VERSION ""

NS_ :

BS_:

BU_: HCM IPMA_ADAS PSCM ABS_ESC PCM ECM_HEV VDM CMR_DSMC SOBDMC_HPCM GWM _delete AWD_DLCM GENERIC TSTR

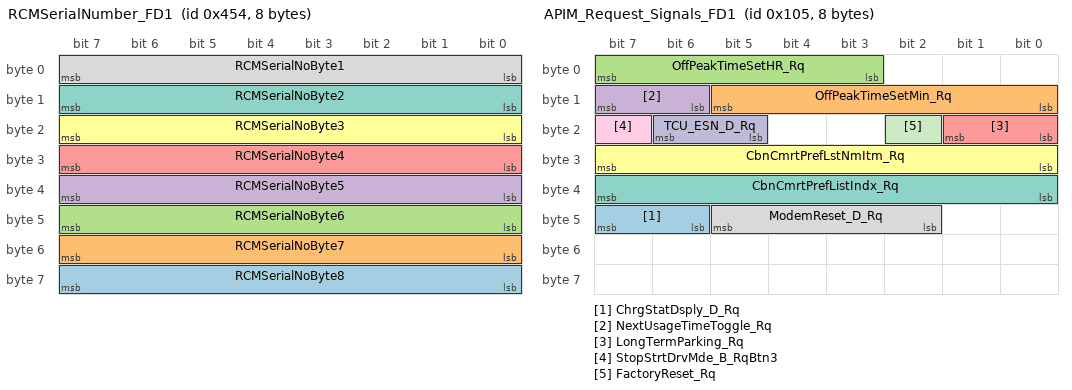
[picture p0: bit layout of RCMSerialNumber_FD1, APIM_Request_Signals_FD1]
BO_ 1108 RCMSerialNumber_FD1: 8 GWM
 SG_ RCMSerialNoByte8 : 63|8@0+ (1,0) [0|253] "Unitless"  ABS_ESC
 SG_ RCMSerialNoByte7 : 55|8@0+ (1,0) [0|253] "Unitless"  ABS_ESC
 SG_ RCMSerialNoByte6 : 47|8@0+ (1,0) [0|253] "Unitless"  ABS_ESC
 SG_ RCMSerialNoByte5 : 39|8@0+ (1,0) [0|253] "Unitless"  ABS_ESC
 SG_ RCMSerialNoByte4 : 31|8@0+ (1,0) [0|253] "Unitless"  ABS_ESC
 SG_ RCMSerialNoByte3 : 23|8@0+ (1,0) [0|253] "Unitless"  ABS_ESC
 SG_ RCMSerialNoByte2 : 15|8@0+ (1,0) [0|253] "Unitless"  ABS_ESC
 SG_ RCMSerialNoByte1 : 7|8@0+ (1,0) [0|253] "Unitless"  ABS_ESC

BO_ 261 APIM_Request_Signals_FD1: 8 GWM
 SG_ ChrgStatDsply_D_Rq : 47|2@0+ (1,0) [0|3] "SED"  GENERIC
 SG_ OffPeakTimeSetMin_Rq : 13|6@0+ (1,0) [0|63] "unitless"  GENERIC
 SG_ OffPeakTimeSetHR_Rq : 7|5@0+ (1,0) [0|31] "unitless"  GENERIC
 SG_ NextUsageTimeToggle_Rq : 15|2@0+ (1,0) [0|3] "SED"  GENERIC
 SG_ LongTermParking_Rq : 17|2@0+ (1,0) [0|3] "SED"  GENERIC
 SG_ CbnCmrtPrefLstNmItm_Rq : 31|8@0+ (1,0) [0|255] "unitless"  GENERIC
 SG_ CbnCmrtPrefListIndx_Rq : 39|8@0+ (1,0) [0|255] "unitless"  GENERIC
 SG_ ModemReset_D_Rq : 45|4@0+ (1,0) [0|15] "SED"  SOBDMC_HPCM
 SG_ StopStrtDrvMde_B_RqBtn3 : 23|1@0+ (1,0) [0|1] "SED"  PCM
 SG_ TCU_ESN_D_Rq : 22|2@0+ (1,0) [0|3] "SED"  GENERIC
 SG_ FactoryReset_Rq : 18|1@0+ (1,0) [0|1] "SED"  SOBDMC_HPCM

BO_ 1146 TrailerInfo_2_FD1: 8 GWM
 SG_ TrlrAidSwtch_D_RqDrv : 35|2@0+ (1,0) [0|3] "SED"  IPMA_ADAS
 SG_ TrlrAidCtl_U_RqDrv : 31|12@0+ (0.00125,0) [0|5.11625] "volt" Vector__XXX

BO_ 533 APIM_Send_Signals_2_FD1: 8 GWM
 SG_ TjaLcEnbl_D_RqMnu : 57|2@0+ (1,0) [0|3] "SED" Vector__XXX
 SG_ ClrExitAsstEnbl_D_RqMnu : 60|2@0+ (1,0) [0|3] "SED"  IPMA_ADAS
 SG_ TrlrAidMde_D_Rq : 5|2@0+ (1,0) [0|3] "SED" Vector__XXX
 SG_ TCU_Init_Actvtn_St : 1|2@0+ (1,0) [0|3] "SED"  GENERIC
 SG_ TCU_Final_Actvtn_St : 3|2@0+ (1,0) [0|3] "SED"  GENERIC
 SG_ OtaTrg_D_Stat : 41|2@0+ (1,0) [0|3] "SED"  GENERIC
 SG_ OnbChrgGoTTouch_D_Rq : 43|2@0+ (1,0) [0|3] "SED"  SOBDMC_HPCM,GENERIC
 SG_ OnbChrgGoTPrcond_D_Rq : 34|2@0+ (1,0) [0|3] "SED"  SOBDMC_HPCM,GENERIC
 SG_ OnbChrgGoTOn_D_Rq : 25|2@0+ (1,0) [0|3] "SED"  SOBDMC_HPCM,GENERIC
 SG_ OnbChrgGoTMnte_D_Rq : 47|4@0+ (1,0) [0|15] "minute"  SOBDMC_HPCM,GENERIC
 SG_ OnbChrgGoTHr_T_Rq : 39|5@0+ (1,0) [0|29] "hour"  SOBDMC_HPCM,GENERIC
 SG_ OnbChrgGoTExtHtr_D_Rq : 27|2@0+ (1,0) [0|3] "SED"  SOBDMC_HPCM,GENERIC
 SG_ OnbChrgGoTElement_D_Rq : 31|4@0+ (1,0) [0|15] "Unitless"  SOBDMC_HPCM,GENERIC
 SG_ OnbChrgGoTDelete_B_Rq : 17|1@0+ (1,0) [0|1] "SED"  SOBDMC_HPCM,GENERIC
 SG_ OnbChrgClearAll_B_Rq : 18|1@0+ (1,0) [0|1] "SED"  SOBDMC_HPCM,GENERIC
 SG_ PaakMyKey_D_Rq : 7|2@0+ (1,0) [0|3] "SED"  GENERIC
 SG_ AutoEpbZoomView_B_Stat : 32|1@0+ (1,0) [0|1] "SED" Vector__XXX
 SG_ AutoEpbButtn_B_Stat : 19|1@0+ (1,0) [0|1] "SED" Vector__XXX
 SG_ DcacPw_D_Rq : 62|2@0+ (1,0) [0|3] "SED" Vector__XXX
 SG_ DcacPwReset_B_Rq : 63|1@0+ (1,0) [0|1] "SED" Vector__XXX
 SG_ LghtAmbDrvMde_D_Rq : 49|2@0+ (1,0) [0|3] "SED"  GENERIC
 SG_ DcacPwLoButtn_B_Stat : 13|1@0+ (1,0) [0|1] "SED" Vector__XXX
 SG_ DcacPwOffButtn_B_Stat : 12|1@0+ (1,0) [0|1] "SED" Vector__XXX
 SG_ DcacPwHiButtn_B_Stat : 14|1@0+ (1,0) [0|1] "SED" Vector__XXX
 SG_ DcacPwResetButtn_B_Stat : 11|1@0+ (1,0) [0|1] "SED" Vector__XXX
 SG_ DcacPwButtn_B_Falt : 15|1@0+ (1,0) [0|1] "SED" Vector__XXX
 SG_ OnbChrgGoTUpdate_B_Rq : 16|1@0+ (1,0) [0|1] "SED"  SOBDMC_HPCM,GENERIC
 SG_ TrlrAlarmButtn_B_Stat : 50|1@0+ (1,0) [0|1] "SED"  GENERIC
 SG_ DcacMdeButtn_B_Stat : 8|1@0+ (1,0) [0|1] "SED" Vector__XXX
 SG_ DcacGfciTestBttn_B_Stat : 9|1@0+ (1,0) [0|1] "SED" Vector__XXX
 SG_ TrlrHitch_D_RqMnu : 23|4@0+ (1,0) [0|15] "SED"  IPMA_ADAS
 SG_ TrlrBrkGain_No_Rq : 55|5@0+ (0.5,0) [0|15.5] "unitless"  GENERIC
 SG_ DcacPwButtn_B_Stat : 10|1@0+ (1,0) [0|1] "SED" Vector__XXX

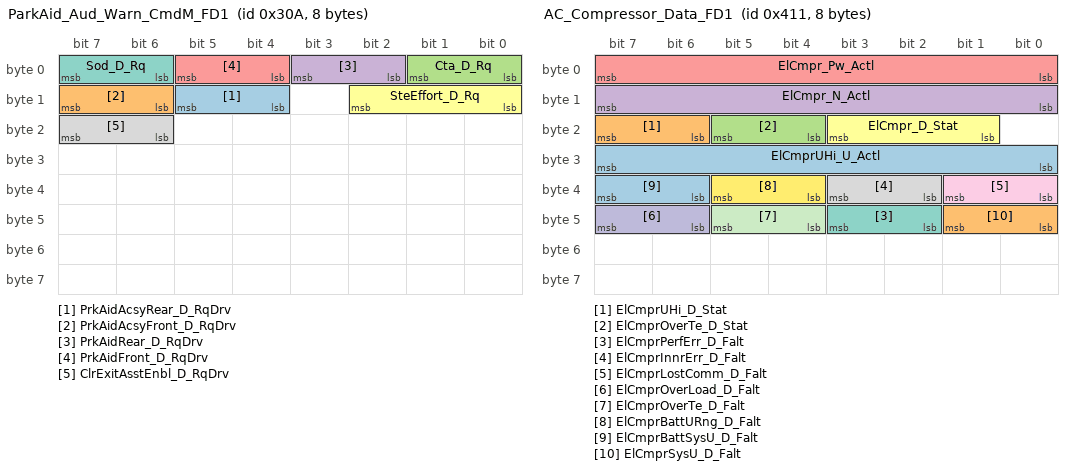
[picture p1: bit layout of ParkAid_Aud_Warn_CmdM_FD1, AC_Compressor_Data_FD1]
BO_ 778 ParkAid_Aud_Warn_CmdM_FD1: 8 GWM
 SG_ PrkAidAcsyRear_D_RqDrv : 13|2@0+ (1,0) [0|3] "SED"  IPMA_ADAS
 SG_ PrkAidAcsyFront_D_RqDrv : 15|2@0+ (1,0) [0|3] "SED"  IPMA_ADAS
 SG_ Cta_D_Rq : 1|2@0+ (1,0) [0|3] "SED"  IPMA_ADAS
 SG_ PrkAidRear_D_RqDrv : 3|2@0+ (1,0) [0|3] "SED"  IPMA_ADAS
 SG_ PrkAidFront_D_RqDrv : 5|2@0+ (1,0) [0|3] "SED"  IPMA_ADAS
 SG_ SteEffort_D_Rq : 10|3@0+ (1,0) [0|7] "SED" Vector__XXX
 SG_ Sod_D_Rq : 7|2@0+ (1,0) [0|3] "SED"  IPMA_ADAS
 SG_ ClrExitAsstEnbl_D_RqDrv : 23|2@0+ (1,0) [0|3] "SED"  IPMA_ADAS

BO_ 1041 AC_Compressor_Data_FD1: 8 GWM
 SG_ ElCmprUHi_U_Actl : 31|8@0+ (2,0) [0|510] "volt"  SOBDMC_HPCM,GENERIC
 SG_ ElCmprUHi_D_Stat : 23|2@0+ (1,0) [0|3] "SED"  SOBDMC_HPCM,GENERIC
 SG_ ElCmprOverTe_D_Stat : 21|2@0+ (1,0) [0|3] "SED"  SOBDMC_HPCM,GENERIC
 SG_ ElCmpr_N_Actl : 15|8@0+ (50,0) [0|12700] "RPM"  SOBDMC_HPCM,GENERIC
 SG_ ElCmpr_Pw_Actl : 7|8@0+ (40,0) [0|10160] "watts"  SOBDMC_HPCM
 SG_ ElCmpr_D_Stat : 19|3@0+ (1,0) [0|7] "SED"  SOBDMC_HPCM,GENERIC
 SG_ ElCmprPerfErr_D_Falt : 43|2@0+ (1,0) [0|3] "SED"  GENERIC,SOBDMC_HPCM
 SG_ ElCmprInnrErr_D_Falt : 35|2@0+ (1,0) [0|3] "SED"  GENERIC,SOBDMC_HPCM
 SG_ ElCmprLostComm_D_Falt : 33|2@0+ (1,0) [0|3] "SED"  GENERIC,SOBDMC_HPCM
 SG_ ElCmprOverLoad_D_Falt : 47|2@0+ (1,0) [0|3] "SED"  GENERIC,SOBDMC_HPCM
 SG_ ElCmprOverTe_D_Falt : 45|2@0+ (1,0) [0|3] "SED"  GENERIC,SOBDMC_HPCM
 SG_ ElCmprBattURng_D_Falt : 37|2@0+ (1,0) [0|3] "SED"  GENERIC,SOBDMC_HPCM
 SG_ ElCmprBattSysU_D_Falt : 39|2@0+ (1,0) [0|3] "SED"  GENERIC,SOBDMC_HPCM
 SG_ ElCmprSysU_D_Falt : 41|2@0+ (1,0) [0|3] "SED"  GENERIC,SOBDMC_HPCM

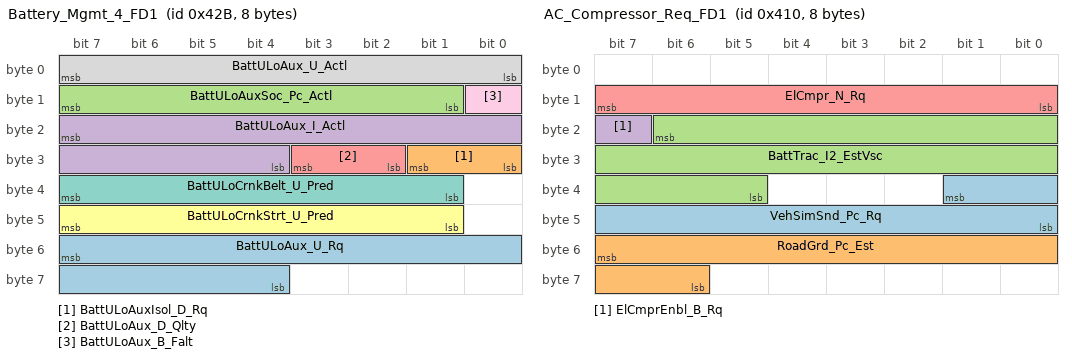
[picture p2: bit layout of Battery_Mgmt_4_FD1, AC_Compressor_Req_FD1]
BO_ 1067 Battery_Mgmt_4_FD1: 8 GWM
 SG_ BattULoAux_U_Rq : 55|12@0+ (0.00390625,0) [0|15.9921875] "volt" Vector__XXX
 SG_ BattULoAuxIsol_D_Rq : 25|2@0+ (1,0) [0|3] "SED" Vector__XXX
 SG_ BattULoAuxSoc_Pc_Actl : 15|7@0+ (1,0) [0|127] "percent" Vector__XXX
 SG_ BattULoAux_I_Actl : 23|12@0+ (0.0625,-128) [-128|127.875] "ampere" Vector__XXX
 SG_ BattULoAux_D_Qlty : 27|2@0+ (1,0) [0|3] "SED" Vector__XXX
 SG_ BattULoCrnkStrt_U_Pred : 47|7@0+ (0.1,0) [0|12.7] "volt" Vector__XXX
 SG_ BattULoCrnkBelt_U_Pred : 39|7@0+ (0.1,0) [0|12.7] "volt" Vector__XXX
 SG_ BattULoAux_U_Actl : 7|8@0+ (0.0625,0) [0|15.875] "volt" Vector__XXX
 SG_ BattULoAux_B_Falt : 8|1@0+ (1,0) [0|1] "SED" Vector__XXX

BO_ 1118 BatteryCharge_Data2_FD1: 8 GWM
 SG_ BptTgl_B_Complt : 29|1@0+ (1,0) [0|1] "SED"  SOBDMC_HPCM
 SG_ AcChrgRdy_B_Stat : 51|1@0+ (1,0) [0|1] "SED"  GENERIC
 SG_ DgtlCommGtwyMde_D_Rq : 48|4@0+ (1,0) [0|15] "SED"  GENERIC
 SG_ ExtChrgNowButtn_B_Rq : 49|1@0+ (1,0) [0|1] "SED"  SOBDMC_HPCM,GENERIC
 SG_ CoolFanChrgr_D_Rq : 45|2@0+ (1,0) [0|3] "SED"  SOBDMC_HPCM,GENERIC
 SG_ ChrgrClntFlw_D_Rq : 31|2@0+ (1,0) [0|3] "SED"  SOBDMC_HPCM,GENERIC
 SG_ PlgStatEvnt_B_Stat : 46|1@0+ (1,0) [0|1] "SED"  SOBDMC_HPCM,ECM_HEV
 SG_ ChrgrCnnctPwr_B_Stat : 47|1@0+ (1,0) [0|1] "SED"  SOBDMC_HPCM,GENERIC
 SG_ ChrgrAvailEvnt_B_Stat : 32|1@0+ (1,0) [0|1] "SED"  SOBDMC_HPCM,ECM_HEV
 SG_ ChrgrSrvcRqd_B_Rq : 0|1@0+ (1,0) [0|1] "SED"  GENERIC
 SG_ ChrgrS2Swtch_B_Stat : 42|1@0+ (1,0) [0|1] "SED"  GENERIC
 SG_ ChrgChngEvnt_B_Stat : 33|1@0+ (1,0) [0|1] "SED"  SOBDMC_HPCM,ECM_HEV
 SG_ ChrgCordLck_D_Stat : 7|3@0+ (1,0) [0|7] "SED"  SOBDMC_HPCM
 SG_ ChrgrInPwMde_D_Actl : 4|4@0+ (1,0) [0|15] "SED"  ECM_HEV,SOBDMC_HPCM
 SG_ ChrgPortDrOpen_B_Stat : 43|1@0+ (1,0) [0|1] "SED"  GENERIC
 SG_ ChrgCordChlng2_No_Actl : 23|8@0+ (1,0) [0|255] "unitless"  GENERIC
 SG_ ChrgCordChlng1_No_Actl : 15|8@0+ (1,0) [0|255] "unitless"  GENERIC
 SG_ ChrgrDcOvrVolt_B_Falt : 50|1@0+ (1,0) [0|1] "SED"  GENERIC
 SG_ ChrgrDcOvrCurnt_B_Falt : 56|1@0+ (1,0) [0|1] "SED"  GENERIC
 SG_ ChrgrPncEnbl_D_Stat : 58|2@0+ (1,0) [0|3] "SED"  GENERIC
 SG_ ChrgrCc2Cnnct_B_Falt : 59|1@0+ (1,0) [0|1] "SED"  GENERIC
 SG_ ChrgPortDcTeMx_B_Falt : 60|1@0+ (1,0) [0|1] "SED"  GENERIC
 SG_ ChrgCrdLck_D_Falt : 41|2@0+ (1,0) [0|3] "SED"  GENERIC

BO_ 1040 AC_Compressor_Req_FD1: 8 SOBDMC_HPCM
 SG_ VehSimSnd_Pc_Rq : 33|10@0+ (0.2,-102.2) [-102.2|102.4] "percent"  GWM
 SG_ RoadGrd_Pc_Est : 55|10@0+ (0.2,-102) [-102|102.4] "percent"  GWM
 SG_ BattTrac_I2_EstVsc : 22|18@0+ (0.05,-6553.52) [-6553.52|6553.53] "ampere"  GWM
 SG_ ElCmprEnbl_B_Rq : 23|1@0+ (1,0) [0|1] "SED"  GWM,ECM_HEV
 SG_ ElCmpr_N_Rq : 15|8@0+ (50,0) [0|12750] "RPM"  GWM,GENERIC

BO_ 1144 MHT_EV_Wakeup_FD1: 8 SOBDMC_HPCM
 SG_ BattTracCool_B_Actl : 60|1@0+ (1,0) [0|1] "SED"  GWM
 SG_ BattChrgInhbt_D2_Rq : 63|3@0+ (1,0) [0|7] "SED"  GWM
 SG_ AwdLckMde_D_Stat : 59|3@0+ (1,0) [0|7] "SED"  GWM
 SG_ ULoBattTrnsfrSustn_B_Rq : 43|1@0+ (1,0) [0|1] "SED"  ECM_HEV,GWM
 SG_ ULoBattTransfer_D_Stat : 46|3@0+ (1,0) [0|7] "SED"  ECM_HEV,GWM
 SG_ BattChrgTrgtSoC_D_Rq : 35|3@0+ (1,0) [0|7] "Percent"  GWM,GENERIC
 SG_ CabnEvapSovFront_B_Rq : 38|1@0+ (1,0) [0|1] "SED"  GWM
 SG_ HeatCoreSovRear_B_Rq : 36|1@0+ (1,0) [0|1] "SED"  GWM,GENERIC
 SG_ BattChlrSov_B_Rq : 39|1@0+ (1,0) [0|1] "SED"  GWM
 SG_ CabnEvapSovRear_B_Rq : 37|1@0+ (1,0) [0|1] "SED"  GWM,GENERIC
 SG_ BrkAppl_D_RqPt : 25|2@0+ (1,0) [0|3] "SED"  GWM,ABS_ESC
 SG_ BattClntVlvOvrrd_D_Rq : 31|2@0+ (1,0) [0|3] "SED"  GWM,GENERIC
 SG_ BattTracChillerOn_B_Rq : 27|1@0+ (1,0) [0|1] "SED"  GWM,GENERIC
 SG_ BattTracChiller_D_Stat : 29|2@0+ (1,0) [0|3] "SED"  GWM,GENERIC
 SG_ HtrnDcdcDis_B_Rq : 26|1@0+ (1,0) [0|1] "SED"  GWM,ECM_HEV
 SG_ HtrnCnnctPwr_B_Stat : 16|1@0+ (1,0) [0|1] "SED"  GWM,GENERIC
 SG_ PtcHtr_D_Stat : 18|2@0+ (1,0) [0|3] "SED"  GWM,ECM_HEV
 SG_ WakeAlarm0_B_Typ : 21|1@0+ (1,0) [0|1] "SED"  GWM,GENERIC
 SG_ WakeAlarm0_T_Rq : 7|15@0+ (1,0) [0|32767] "minute"  GWM,GENERIC
 SG_ HtrnClntFlw_D_Rq : 20|2@0+ (1,0) [0|3] "SED"  GWM,GENERIC
 SG_ BattTracDrvSustn_B_Rq : 8|1@0+ (1,0) [0|1] "SED"  GWM,ECM_HEV
 SG_ CabinDrvSustn_B_Rq : 23|1@0+ (1,0) [0|1] "SED"  GWM,ECM_HEV
 SG_ ChrgNowEvnt_B_Stat : 22|1@0+ (1,0) [0|1] "SED"  GWM,ECM_HEV
 SG_ PreCondBatt_B_Actl : 32|1@0+ (1,0) [0|1] "SED"  GWM,ECM_HEV
 SG_ BattTracClntVlv_B_Rq : 47|1@0+ (1,0) [0|1] "SED"  GWM

BO_ 1112 Battery_Traction_6_FD1: 8 GWM
 SG_ BattDcCnnct_D_Cmd : 14|3@0+ (1,0) [0|7] "SED"  GENERIC
 SG_ BattTrac2_E_Avail : 31|12@0+ (50,0) [0|204650] "watt*hour"  SOBDMC_HPCM
 SG_ BattTracCnnct_D_Cmd : 18|3@0+ (1,0) [0|7] "SED"  SOBDMC_HPCM,ECM_HEV
 SG_ BattTracHvilOpen_B_Stat : 8|1@0+ (1,0) [0|1] "SED"  SOBDMC_HPCM
 SG_ BattTracCoolLvl_D_Rq : 11|3@0+ (1,0) [0|7] "SED"  GENERIC
 SG_ CoolFanBatt_D_Rq : 23|5@0+ (1,0) [0|31] "unitless" Vector__XXX
 SG_ BattTracTeSustn_B_Rq : 1|1@0+ (1,0) [0|1] "SED"  ECM_HEV
 SG_ BattTracTeEvnt_B_Stat : 2|1@0+ (1,0) [0|1] "SED"  SOBDMC_HPCM,ECM_HEV
 SG_ BattTracDcdcDis_B_Rq : 7|1@0+ (1,0) [0|1] "SED"  ECM_HEV
 SG_ BattChrgTrgtEvnt_B_Stat : 3|1@0+ (1,0) [0|1] "SED"  SOBDMC_HPCM,ECM_HEV
 SG_ BattTracChrgSustn_B_Rq : 4|1@0+ (1,0) [0|1] "SED"  SOBDMC_HPCM,ECM_HEV
 SG_ HtrnClntPump_D_Stat : 6|2@0+ (1,0) [0|3] "SED"  SOBDMC_HPCM,GENERIC
 SG_ BattTracIsoDis_B_Stat : 0|1@0+ (1,0) [0|1] "SED"  GENERIC
 SG_ BattTrac2_E_Max : 47|12@0+ (50,0) [0|204650] "watt*hour"  SOBDMC_HPCM
 SG_ BattTracHeat_D_Rq : 35|2@0+ (1,0) [0|3] "SED"  SOBDMC_HPCM
 SG_ BattTracDcFstSustn_B_Rq : 51|1@0+ (1,0) [0|1] "SED" Vector__XXX
 SG_ BattTracDiagClr_B_Rq : 15|1@0+ (1,0) [0|1] "SED"  ECM_HEV
 SG_ BattTracHazrd_D_Stat : 50|3@0+ (1,0) [0|7] "SED"  SOBDMC_HPCM
 SG_ BattTracDelta_Te_Actl : 63|8@0+ (0.5,-60) [-60|66.5] "degC"  SOBDMC_HPCM,GENERIC
 SG_ BattTracClntPmp_D_Stat : 33|2@0+ (1,0) [0|3] "SED"  SOBDMC_HPCM,GENERIC

BO_ 139 CruiseCtrl_Strg_Data_FD1: 8 GWM
 SG_ AccButtnGpTogglePress2 : 25|1@0+ (1,0) [0|1] "SED"  GENERIC
 SG_ TjaButtnOnOffPress2 : 26|1@0+ (1,0) [0|1] "SED"  GENERIC
 SG_ ActvFrontSteMsgTxt_D_Rq : 31|3@0+ (1,0) [0|7] "SED"  GENERIC
 SG_ ActvFrontSteLck_D_Stat : 17|2@0+ (1,0) [0|3] "SED"  PCM
 SG_ SelDrvMdeAdptSte_D_Stat : 28|2@0+ (1,0) [0|3] "SED" Vector__XXX
 SG_ AslButtnOnOffPress2 : 4|1@0+ (1,0) [0|1] "SED"  GENERIC
 SG_ AslButtnOnOffCnclPres2 : 5|1@0+ (1,0) [0|1] "SED"  GENERIC
 SG_ CcButtnOnPress2 : 18|1@0+ (1,0) [0|1] "SED"  GENERIC
 SG_ CcButtnOnOffPress2 : 19|1@0+ (1,0) [0|1] "SED"  GENERIC
 SG_ CcButtnOnOffCnclPress2 : 20|1@0+ (1,0) [0|1] "SED"  GENERIC
 SG_ CcButtnOffPress2 : 21|1@0+ (1,0) [0|1] "SED"  GENERIC
 SG_ CcAsllButtnResPress2 : 22|1@0+ (1,0) [0|1] "SED"  GENERIC
 SG_ CcAslButtnSetPress2 : 23|1@0+ (1,0) [0|1] "SED"  GENERIC
 SG_ CcAslButtnSetIncPress2 : 8|1@0+ (1,0) [0|1] "SED"  GENERIC
 SG_ CcAslButtnSetDecPress2 : 9|1@0+ (1,0) [0|1] "SED"  GENERIC
 SG_ CcAslButtnResIncPress2 : 10|1@0+ (1,0) [0|1] "SED"  GENERIC
 SG_ CcAslButtnResDecPress2 : 11|1@0+ (1,0) [0|1] "SED"  GENERIC
 SG_ CcAslButtnOnPress2 : 12|1@0+ (1,0) [0|1] "SED"  GENERIC
 SG_ CcAslButtnOnOffCncl2 : 13|1@0+ (1,0) [0|1] "SED"  GENERIC
 SG_ CcAslButtnOffCnclPres2 : 14|1@0+ (1,0) [0|1] "SED"  GENERIC
 SG_ CcAslButtnIndxIncPres2 : 15|1@0+ (1,0) [0|1] "SED"  GENERIC
 SG_ CcAslButtnIndxDecPres2 : 0|1@0+ (1,0) [0|1] "SED"  GENERIC
 SG_ CcAslButtnDeny_B_Actl2 : 1|1@0+ (1,0) [0|1] "SED"  GENERIC
 SG_ CcAslButtnCnclResPres2 : 2|1@0+ (1,0) [0|1] "SED"  GENERIC
 SG_ CcAslButtnCnclPress2 : 3|1@0+ (1,0) [0|1] "SED"  GENERIC
 SG_ AccButtnGapIncPress2 : 6|1@0+ (1,0) [0|1] "SED"  GENERIC
 SG_ AccButtnGapDecPress2 : 7|1@0+ (1,0) [0|1] "SED"  GENERIC
 SG_ AfsPw_B_Rq : 24|1@0+ (1,0) [0|1] "SED"  PCM

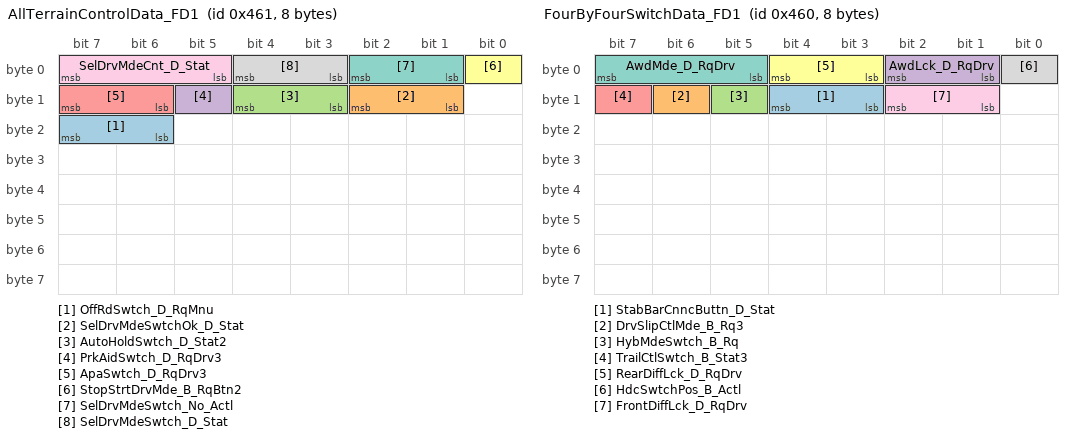
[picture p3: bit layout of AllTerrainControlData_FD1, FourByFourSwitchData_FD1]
BO_ 1121 AllTerrainControlData_FD1: 8 GWM
 SG_ OffRdSwtch_D_RqMnu : 23|2@0+ (1,0) [0|3] "SED"  GENERIC
 SG_ SelDrvMdeSwtchOk_D_Stat : 10|2@0+ (1,0) [0|3] "SED" Vector__XXX
 SG_ AutoHoldSwtch_D_Stat2 : 12|2@0+ (1,0) [0|3] "SED"  ABS_ESC
 SG_ PrkAidSwtch_D_RqDrv3 : 13|1@0+ (1,0) [0|1] "SED"  IPMA_ADAS
 SG_ ApaSwtch_D_RqDrv3 : 15|2@0+ (1,0) [0|3] "SED"  GENERIC
 SG_ StopStrtDrvMde_B_RqBtn2 : 0|1@0+ (1,0) [0|1] "SED" Vector__XXX
 SG_ SelDrvMdeSwtch_No_Actl : 2|2@0+ (1,0) [0|3] "unitless"  ABS_ESC
 SG_ SelDrvMdeSwtch_D_Stat : 4|2@0+ (1,0) [0|3] "SED"  ABS_ESC
 SG_ SelDrvMdeCnt_D_Stat : 7|3@0+ (1,0) [0|7] "Counts"  ABS_ESC

BO_ 1120 FourByFourSwitchData_FD1: 8 GWM
 SG_ StabBarCnncButtn_D_Stat : 12|2@0+ (1,0) [0|3] "SED" Vector__XXX
 SG_ DrvSlipCtlMde_B_Rq3 : 14|1@0+ (1,0) [0|1] "SED"  ABS_ESC
 SG_ HybMdeSwtch_B_Rq : 13|1@0+ (1,0) [0|1] "SED" Vector__XXX
 SG_ AwdLck_D_RqDrv : 2|2@0+ (1,0) [0|3] "SED" Vector__XXX
 SG_ TrailCtlSwtch_B_Stat3 : 15|1@0+ (1,0) [0|1] "SED" Vector__XXX
 SG_ RearDiffLck_D_RqDrv : 4|2@0+ (1,0) [0|3] "SED" Vector__XXX
 SG_ AwdMde_D_RqDrv : 7|3@0+ (1,0) [0|7] "SED" Vector__XXX
 SG_ HdcSwtchPos_B_Actl : 0|1@0+ (1,0) [0|1] "SED" Vector__XXX
 SG_ FrontDiffLck_D_RqDrv : 10|2@0+ (1,0) [0|3] "SED" Vector__XXX

BO_ 1050 Climate_Control_Data_FD1: 8 GWM
 SG_ CamraRearBttn_D_Stat : 35|1@0+ (1,0) [0|1] "SED"  GENERIC
 SG_ TrailCtlSwtch_B_Stat : 16|1@0+ (1,0) [0|1] "SED" Vector__XXX
 SG_ AutoHoldSwtch_D_Stat : 20|2@0+ (1,0) [0|3] "SED"  ABS_ESC
 SG_ GlvBoxRleas_No_Actl : 23|3@0+ (1,0) [0|7] "unitless"  GENERIC
 SG_ EcoInhbt_B_RqHvac : 17|1@0+ (1,0) [0|1] "SED" Vector__XXX
 SG_ LpdbPtc3_B_Rq : 36|1@0+ (1,0) [0|1] "SED"  GENERIC
 SG_ LpdbPtc2_B_Rq : 37|1@0+ (1,0) [0|1] "SED"  GENERIC
 SG_ LpdbPtc1_B_Rq : 38|1@0+ (1,0) [0|1] "SED"  GENERIC
 SG_ LpdbHeatWiprPrk_B_Rq : 39|1@0+ (1,0) [0|1] "SED"  GENERIC
 SG_ LpdbDfrstRearOn_B_Rq : 24|1@0+ (1,0) [0|1] "SED"  GENERIC
 SG_ LpdbDfrstFrOn_B_Rq : 25|1@0+ (1,0) [0|1] "SED"  GENERIC
 SG_ LpdbDfrstFlOn_B_Rq : 26|1@0+ (1,0) [0|1] "SED"  GENERIC
 SG_ LpdbAuxBlwr_B_Rq : 27|1@0+ (1,0) [0|1] "SED"  GENERIC
 SG_ PrkAidSwtch_No_Cnt : 31|4@0+ (1,0) [0|15] "Unitless"  GENERIC
 SG_ PrkAidSwtch_D_RqDrv : 18|1@0+ (1,0) [0|1] "SED"  GENERIC
 SG_ SteWhlHeat_D_Rq : 13|4@0+ (1,0) [0|15] "SED"  GENERIC
 SG_ MirrorHeatOn_B_Rq : 14|1@0+ (1,0) [0|1] "SED"  GENERIC
 SG_ Remote_Start_QuietMode : 15|1@0+ (1,0) [0|1] "SED"  GENERIC
 SG_ DrvSlipCtlMde_B_Rq : 9|1@0+ (1,0) [0|1] "SED"  ABS_ESC
 SG_ Outside_Air_Temp_Stat : 7|8@0+ (0.5,-40) [-40|86.5] "Degrees C"  ECM_HEV,IPMA_ADAS,PCM,PSCM,VDM
 SG_ CamraFrntBttn_D_Stat : 8|1@0+ (1,0) [0|1] "SED"  IPMA_ADAS

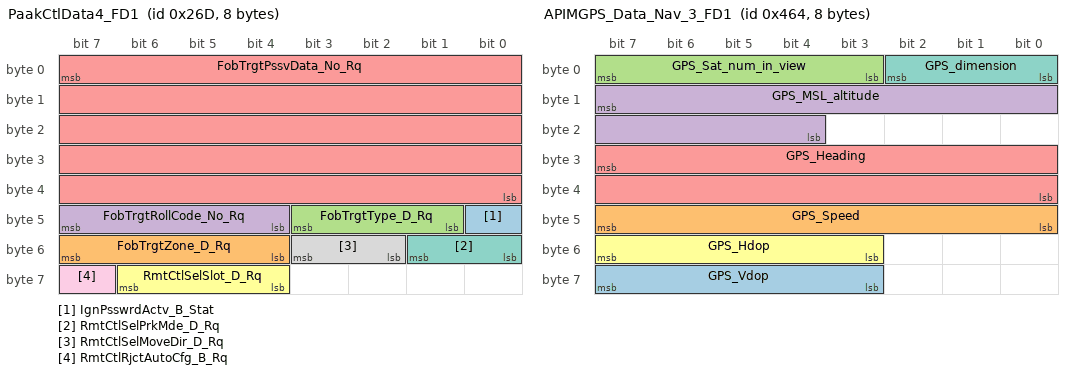
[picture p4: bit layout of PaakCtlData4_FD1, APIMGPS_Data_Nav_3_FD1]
BO_ 621 PaakCtlData4_FD1: 8 GWM
 SG_ IgnPsswrdActv_B_Stat : 40|1@0+ (1,0) [0|1] "SED"  GENERIC
 SG_ FobTrgtZone_D_Rq : 55|4@0+ (1,0) [0|15] "SED"  GENERIC
 SG_ FobTrgtType_D_Rq : 43|3@0+ (1,0) [0|7] "SED"  GENERIC
 SG_ FobTrgtRollCode_No_Rq : 47|4@0+ (1,0) [0|15] "unitless"  GENERIC
 SG_ FobTrgtPssvData_No_Rq : 7|40@0+ (1,0) [0|1099511627775] "Encrypted"  GENERIC
 SG_ RmtCtlSelSlot_D_Rq : 62|3@0+ (1,0) [0|7] "SED"  IPMA_ADAS
 SG_ RmtCtlSelPrkMde_D_Rq : 49|2@0+ (1,0) [0|3] "SED"  IPMA_ADAS
 SG_ RmtCtlSelMoveDir_D_Rq : 51|2@0+ (1,0) [0|3] "SED"  IPMA_ADAS
 SG_ RmtCtlRjctAutoCfg_B_Rq : 63|1@0+ (1,0) [0|1] "SED"  IPMA_ADAS

BO_ 1124 APIMGPS_Data_Nav_3_FD1: 8 GWM
 SG_ GPS_Vdop : 63|5@0+ (0.2,0) [0|5.8] "unitless"  GENERIC
 SG_ GPS_Speed : 47|8@0+ (1,0) [0|253] "MPH"  GENERIC
 SG_ GPS_Sat_num_in_view : 7|5@0+ (1,0) [0|29] "unitless"  GENERIC
 SG_ GPS_MSL_altitude : 15|12@0+ (10,-20460) [-20460|20470] "feet"  GENERIC
 SG_ GPS_Heading : 31|16@0+ (0.01,0) [0|655.33] "Degrees" Vector__XXX
 SG_ GPS_Hdop : 55|5@0+ (0.2,0) [0|5.8] "unitless"  GENERIC
 SG_ GPS_dimension : 2|3@0+ (1,0) [0|7] "SED"  GENERIC

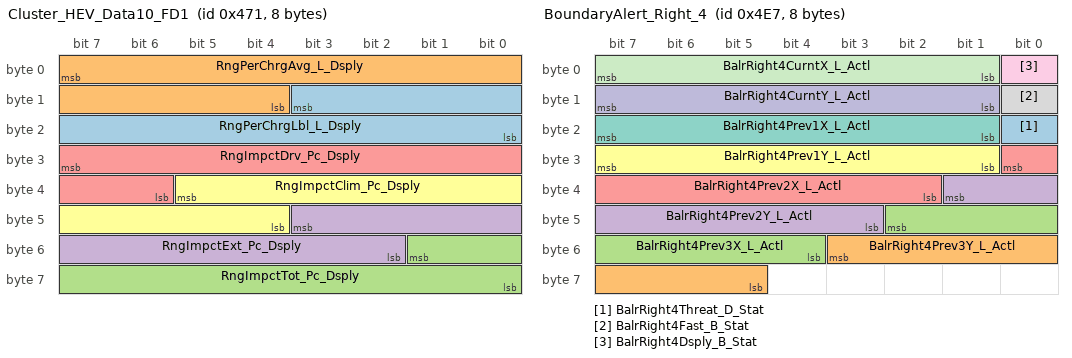
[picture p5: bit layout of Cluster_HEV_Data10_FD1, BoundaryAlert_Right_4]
BO_ 1137 Cluster_HEV_Data10_FD1: 8 PCM
 SG_ RngPerChrgLbl_L_Dsply : 11|12@0+ (0.1,0) [0|409.3] "km"  GWM
 SG_ RngPerChrgAvg_L_Dsply : 7|12@0+ (0.1,0) [0|409.3] "km"  GWM
 SG_ RngImpctTot_Pc_Dsply : 49|10@0+ (0.2,-102) [-102|102.4] "percent"  GWM
 SG_ RngImpctExt_Pc_Dsply : 43|10@0+ (0.2,-102) [-102|102.4] "percent"  GWM
 SG_ RngImpctDrv_Pc_Dsply : 31|10@0+ (0.2,-102) [-102|102.4] "percent"  GWM
 SG_ RngImpctClim_Pc_Dsply : 37|10@0+ (0.2,-102) [-102|102.4] "percent"  GWM

BO_ 1255 BoundaryAlert_Right_4: 8 IPMA_ADAS
 SG_ BalrRight4Threat_D_Stat : 16|1@0+ (1,0) [0|1] "SED"  GWM
 SG_ BalrRight4Prev3Y_L_Actl : 51|7@0+ (0.5,-32) [-32|31.5] "meter"  GWM
 SG_ BalrRight4Prev3X_L_Actl : 42|7@0+ (0.5,-32) [-32|31.5] "meter"  GWM
 SG_ BalrRight4Prev2Y_L_Actl : 33|7@0+ (0.5,-32) [-32|31.5] "meter"  GWM
 SG_ BalrRight4Prev2X_L_Actl : 24|7@0+ (0.5,-32) [-32|31.5] "meter"  GWM
 SG_ BalrRight4Prev1Y_L_Actl : 31|7@0+ (0.5,-32) [-32|31.5] "meter"  GWM
 SG_ BalrRight4Prev1X_L_Actl : 23|7@0+ (0.5,-32) [-32|31.5] "meter"  GWM
 SG_ BalrRight4Fast_B_Stat : 8|1@0+ (1,0) [0|1] "SED"  GWM
 SG_ BalrRight4Dsply_B_Stat : 0|1@0+ (1,0) [0|1] "SED"  GWM
 SG_ BalrRight4CurntY_L_Actl : 15|7@0+ (0.5,-32) [-32|31.5] "meter"  GWM
 SG_ BalrRight4CurntX_L_Actl : 7|7@0+ (0.5,-32) [-32|31.5] "meter"  GWM

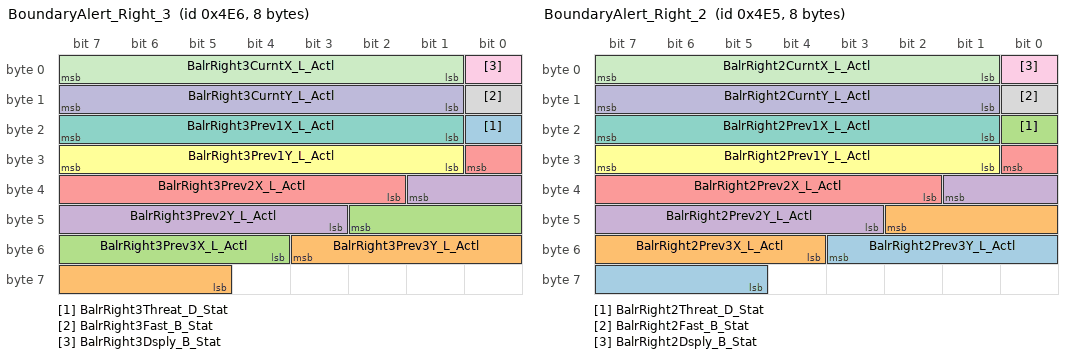
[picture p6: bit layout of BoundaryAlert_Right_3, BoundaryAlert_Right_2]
BO_ 1254 BoundaryAlert_Right_3: 8 IPMA_ADAS
 SG_ BalrRight3Threat_D_Stat : 16|1@0+ (1,0) [0|1] "SED"  GWM
 SG_ BalrRight3Prev3Y_L_Actl : 51|7@0+ (0.5,-32) [-32|31.5] "meter"  GWM
 SG_ BalrRight3Prev3X_L_Actl : 42|7@0+ (0.5,-32) [-32|31.5] "meter"  GWM
 SG_ BalrRight3Prev2Y_L_Actl : 33|7@0+ (0.5,-32) [-32|31.5] "meter"  GWM
 SG_ BalrRight3Prev2X_L_Actl : 24|7@0+ (0.5,-32) [-32|31.5] "meter"  GWM
 SG_ BalrRight3Prev1Y_L_Actl : 31|7@0+ (0.5,-32) [-32|31.5] "meter"  GWM
 SG_ BalrRight3Prev1X_L_Actl : 23|7@0+ (0.5,-32) [-32|31.5] "meter"  GWM
 SG_ BalrRight3Fast_B_Stat : 8|1@0+ (1,0) [0|1] "SED"  GWM
 SG_ BalrRight3Dsply_B_Stat : 0|1@0+ (1,0) [0|1] "SED"  GWM
 SG_ BalrRight3CurntY_L_Actl : 15|7@0+ (0.5,-32) [-32|31.5] "meter"  GWM
 SG_ BalrRight3CurntX_L_Actl : 7|7@0+ (0.5,-32) [-32|31.5] "meter"  GWM

BO_ 1253 BoundaryAlert_Right_2: 8 IPMA_ADAS
 SG_ BalrRight2Prev3Y_L_Actl : 51|7@0+ (0.5,-32) [-32|31.5] "meter"  GWM
 SG_ BalrRight2Prev3X_L_Actl : 42|7@0+ (0.5,-32) [-32|31.5] "meter"  GWM
 SG_ BalrRight2Threat_D_Stat : 16|1@0+ (1,0) [0|1] "SED"  GWM
 SG_ BalrRight2Prev2Y_L_Actl : 33|7@0+ (0.5,-32) [-32|31.5] "meter"  GWM
 SG_ BalrRight2Prev2X_L_Actl : 24|7@0+ (0.5,-32) [-32|31.5] "meter"  GWM
 SG_ BalrRight2Prev1Y_L_Actl : 31|7@0+ (0.5,-32) [-32|31.5] "meter"  GWM
 SG_ BalrRight2Prev1X_L_Actl : 23|7@0+ (0.5,-32) [-32|31.5] "meter"  GWM
 SG_ BalrRight2Fast_B_Stat : 8|1@0+ (1,0) [0|1] "SED"  GWM
 SG_ BalrRight2Dsply_B_Stat : 0|1@0+ (1,0) [0|1] "SED"  GWM
 SG_ BalrRight2CurntY_L_Actl : 15|7@0+ (0.5,-32) [-32|31.5] "meter"  GWM
 SG_ BalrRight2CurntX_L_Actl : 7|7@0+ (0.5,-32) [-32|31.5] "meter"  GWM

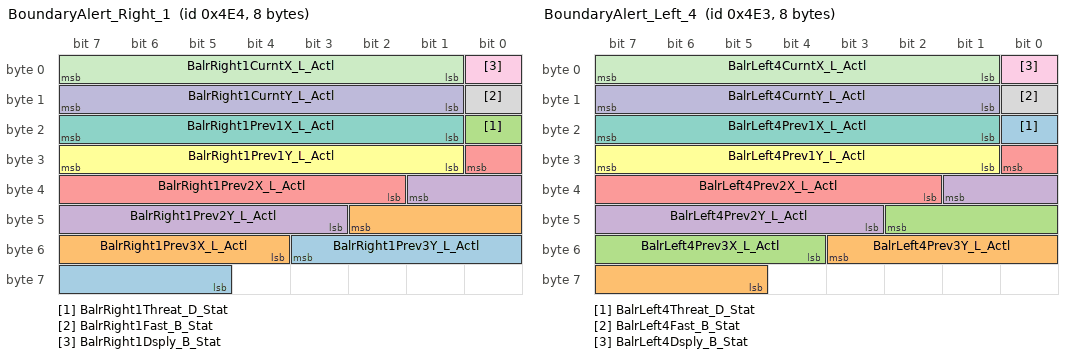
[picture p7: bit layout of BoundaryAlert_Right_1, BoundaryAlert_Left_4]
BO_ 1252 BoundaryAlert_Right_1: 8 IPMA_ADAS
 SG_ BalrRight1Prev3Y_L_Actl : 51|7@0+ (0.5,-32) [-32|31.5] "meter"  GWM
 SG_ BalrRight1Prev3X_L_Actl : 42|7@0+ (0.5,-32) [-32|31.5] "meter"  GWM
 SG_ BalrRight1Threat_D_Stat : 16|1@0+ (1,0) [0|1] "SED"  GWM
 SG_ BalrRight1Prev2Y_L_Actl : 33|7@0+ (0.5,-32) [-32|31.5] "meter"  GWM
 SG_ BalrRight1Prev2X_L_Actl : 24|7@0+ (0.5,-32) [-32|31.5] "meter"  GWM
 SG_ BalrRight1Prev1Y_L_Actl : 31|7@0+ (0.5,-32) [-32|31.5] "meter"  GWM
 SG_ BalrRight1Prev1X_L_Actl : 23|7@0+ (0.5,-32) [-32|31.5] "meter"  GWM
 SG_ BalrRight1Fast_B_Stat : 8|1@0+ (1,0) [0|1] "SED"  GWM
 SG_ BalrRight1Dsply_B_Stat : 0|1@0+ (1,0) [0|1] "SED"  GWM
 SG_ BalrRight1CurntY_L_Actl : 15|7@0+ (0.5,-32) [-32|31.5] "meter"  GWM
 SG_ BalrRight1CurntX_L_Actl : 7|7@0+ (0.5,-32) [-32|31.5] "meter"  GWM

BO_ 1251 BoundaryAlert_Left_4: 8 IPMA_ADAS
 SG_ BalrLeft4Threat_D_Stat : 16|1@0+ (1,0) [0|1] "SED"  GWM
 SG_ BalrLeft4Prev3Y_L_Actl : 51|7@0+ (0.5,-32) [-32|31.5] "meter"  GWM
 SG_ BalrLeft4Prev3X_L_Actl : 42|7@0+ (0.5,-32) [-32|31.5] "meter"  GWM
 SG_ BalrLeft4Prev2Y_L_Actl : 33|7@0+ (0.5,-32) [-32|31.5] "meter"  GWM
 SG_ BalrLeft4Prev2X_L_Actl : 24|7@0+ (0.5,-32) [-32|31.5] "meter"  GWM
 SG_ BalrLeft4Prev1Y_L_Actl : 31|7@0+ (0.5,-32) [-32|31.5] "meter"  GWM
 SG_ BalrLeft4Prev1X_L_Actl : 23|7@0+ (0.5,-32) [-32|31.5] "meter"  GWM
 SG_ BalrLeft4Fast_B_Stat : 8|1@0+ (1,0) [0|1] "SED"  GWM
 SG_ BalrLeft4Dsply_B_Stat : 0|1@0+ (1,0) [0|1] "SED"  GWM
 SG_ BalrLeft4CurntY_L_Actl : 15|7@0+ (0.5,-32) [-32|31.5] "meter"  GWM
 SG_ BalrLeft4CurntX_L_Actl : 7|7@0+ (0.5,-32) [-32|31.5] "meter"  GWM

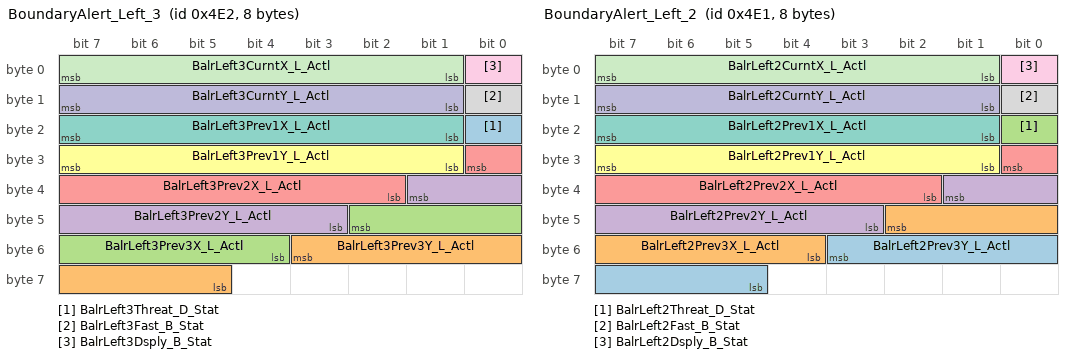
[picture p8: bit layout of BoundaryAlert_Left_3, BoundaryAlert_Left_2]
BO_ 1250 BoundaryAlert_Left_3: 8 IPMA_ADAS
 SG_ BalrLeft3Threat_D_Stat : 16|1@0+ (1,0) [0|1] "SED"  GWM
 SG_ BalrLeft3Prev3Y_L_Actl : 51|7@0+ (0.5,-32) [-32|31.5] "meter"  GWM
 SG_ BalrLeft3Prev3X_L_Actl : 42|7@0+ (0.5,-32) [-32|31.5] "meter"  GWM
 SG_ BalrLeft3Prev2Y_L_Actl : 33|7@0+ (0.5,-32) [-32|31.5] "meter"  GWM
 SG_ BalrLeft3Prev2X_L_Actl : 24|7@0+ (0.5,-32) [-32|31.5] "meter"  GWM
 SG_ BalrLeft3Prev1Y_L_Actl : 31|7@0+ (0.5,-32) [-32|31.5] "meter"  GWM
 SG_ BalrLeft3Prev1X_L_Actl : 23|7@0+ (0.5,-32) [-32|31.5] "meter"  GWM
 SG_ BalrLeft3Fast_B_Stat : 8|1@0+ (1,0) [0|1] "SED"  GWM
 SG_ BalrLeft3Dsply_B_Stat : 0|1@0+ (1,0) [0|1] "SED"  GWM
 SG_ BalrLeft3CurntY_L_Actl : 15|7@0+ (0.5,-32) [-32|31.5] "meter"  GWM
 SG_ BalrLeft3CurntX_L_Actl : 7|7@0+ (0.5,-32) [-32|31.5] "meter"  GWM

BO_ 1249 BoundaryAlert_Left_2: 8 IPMA_ADAS
 SG_ BalrLeft2Prev3Y_L_Actl : 51|7@0+ (0.5,-32) [-32|31.5] "meter"  GWM
 SG_ BalrLeft2Prev3X_L_Actl : 42|7@0+ (0.5,-32) [-32|31.5] "meter"  GWM
 SG_ BalrLeft2Threat_D_Stat : 16|1@0+ (1,0) [0|1] "SED"  GWM
 SG_ BalrLeft2Prev2Y_L_Actl : 33|7@0+ (0.5,-32) [-32|31.5] "meter"  GWM
 SG_ BalrLeft2Prev2X_L_Actl : 24|7@0+ (0.5,-32) [-32|31.5] "meter"  GWM
 SG_ BalrLeft2Prev1Y_L_Actl : 31|7@0+ (0.5,-32) [-32|31.5] "meter"  GWM
 SG_ BalrLeft2Prev1X_L_Actl : 23|7@0+ (0.5,-32) [-32|31.5] "meter"  GWM
 SG_ BalrLeft2Fast_B_Stat : 8|1@0+ (1,0) [0|1] "SED"  GWM
 SG_ BalrLeft2Dsply_B_Stat : 0|1@0+ (1,0) [0|1] "SED"  GWM
 SG_ BalrLeft2CurntY_L_Actl : 15|7@0+ (0.5,-32) [-32|31.5] "meter"  GWM
 SG_ BalrLeft2CurntX_L_Actl : 7|7@0+ (0.5,-32) [-32|31.5] "meter"  GWM

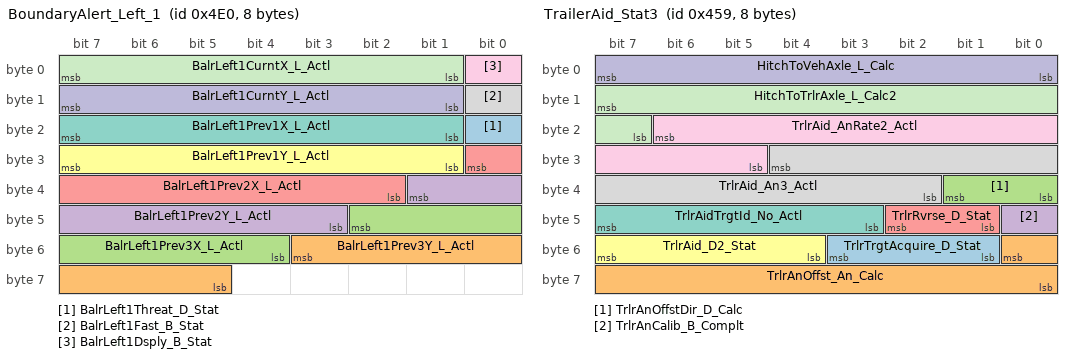
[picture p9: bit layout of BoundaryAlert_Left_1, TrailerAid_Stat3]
BO_ 1248 BoundaryAlert_Left_1: 8 IPMA_ADAS
 SG_ BalrLeft1Threat_D_Stat : 16|1@0+ (1,0) [0|1] "SED"  GWM
 SG_ BalrLeft1Prev3Y_L_Actl : 51|7@0+ (0.5,-32) [-32|31.5] "meter"  GWM
 SG_ BalrLeft1Prev3X_L_Actl : 42|7@0+ (0.5,-32) [-32|31.5] "meter"  GWM
 SG_ BalrLeft1Prev2Y_L_Actl : 33|7@0+ (0.5,-32) [-32|31.5] "meter"  GWM
 SG_ BalrLeft1Prev2X_L_Actl : 24|7@0+ (0.5,-32) [-32|31.5] "meter"  GWM
 SG_ BalrLeft1Prev1Y_L_Actl : 31|7@0+ (0.5,-32) [-32|31.5] "meter"  GWM
 SG_ BalrLeft1Prev1X_L_Actl : 23|7@0+ (0.5,-32) [-32|31.5] "meter"  GWM
 SG_ BalrLeft1Fast_B_Stat : 8|1@0+ (1,0) [0|1] "SED"  GWM
 SG_ BalrLeft1Dsply_B_Stat : 0|1@0+ (1,0) [0|1] "SED"  GWM
 SG_ BalrLeft1CurntY_L_Actl : 15|7@0+ (0.5,-32) [-32|31.5] "meter"  GWM
 SG_ BalrLeft1CurntX_L_Actl : 7|7@0+ (0.5,-32) [-32|31.5] "meter"  GWM

BO_ 2610988248 PARSEDPhysGWM_ECGtoIPMA: 64 GWM
 SG_ PARSEDPhysGWM_ECGtoIPMA : 7|29@0+ (1,0) [0|536870911] "unitless"  IPMA_ADAS

BO_ 1113 TrailerAid_Stat3: 8 IPMA_ADAS
 SG_ TrlrTrgtAcquire_D_Stat : 51|3@0+ (1,0) [0|7] "SED"  GWM
 SG_ TrlrAnOffst_An_Calc : 48|9@0+ (0.1,0) [0|51.1] "degrees"  GWM
 SG_ TrlrAnOffstDir_D_Calc : 33|2@0+ (1,0) [0|3] "SED"  GWM
 SG_ TrlrAnCalib_B_Complt : 40|1@0+ (1,0) [0|1] "SED"  GWM
 SG_ TrlrRvrse_D_Stat : 42|2@0+ (1,0) [0|3] "SED" Vector__XXX
 SG_ TrlrAid_D2_Stat : 55|4@0+ (1,0) [0|15] "SED" Vector__XXX
 SG_ TrlrAidTrgtId_No_Actl : 47|5@0+ (1,0) [0|31] "unitless"  GWM
 SG_ TrlrAid_An3_Actl : 28|11@0+ (0.125,-90) [-90|165.75] "degrees"  GWM
 SG_ TrlrAid_AnRate2_Actl : 22|10@0+ (0.125,-50) [-50|77.75] "degrees/second"  GWM
 SG_ HitchToVehAxle_L_Calc : 7|8@0+ (0.0127,-0.508) [-0.508|2.7178] "meter"  GWM
 SG_ HitchToTrlrAxle_L_Calc2 : 15|9@0+ (0.0254,0) [0|12.9794] "meter"  GWM

BO_ 1105 Image_Processing_Data: 8 IPMA_ADAS
 SG_ ClrExitAsstMsgTxt2_D_Rq : 55|4@0+ (1,0) [0|15] "SED"  GWM
 SG_ ClrExitAsstActv_B_Rq : 24|1@0+ (1,0) [0|1] "SED"  GWM
 SG_ TrlrRvrseMsgTxt_D2_Rq : 31|6@0+ (1,0) [0|63] "SED"  GWM
 SG_ TrlrRvrseEnbl_D2_Stat : 18|3@0+ (1,0) [0|7] "SED"  GWM
 SG_ RbaMsg_D_Rq : 22|2@0+ (1,0) [0|3] "SED"  GWM
 SG_ BrkDecel_B_RqRba : 8|1@0+ (1,0) [0|1] "SED"  ABS_ESC
 SG_ BrkEnbl_B_RqRba : 23|1@0+ (1,0) [0|1] "SED"  ABS_ESC
 SG_ Rba_D_Stat : 14|2@0+ (1,0) [0|3] "SED"  GWM
 SG_ RbaAlrt_D_Dsply : 12|2@0+ (1,0) [0|3] "SED"  GWM
 SG_ RbaMnu_D_Rq : 10|2@0+ (1,0) [0|3] "SED"  GWM
 SG_ CamraFrntStat_D_Stat : 7|2@0+ (1,0) [0|3] "SED"  GWM
 SG_ TrlrHitchLamp_D_Rq2 : 15|1@0+ (1,0) [0|1] "SED"  GWM
 SG_ CamraFrntOffRd_B_Stat : 25|1@0+ (1,0) [0|1] "SED"  GWM
 SG_ TrlrAidSwtchLamp_B_Rq : 32|1@0+ (1,0) [0|1] "SED"  GWM
 SG_ TrlrAidEnbl_D_RqAdas : 5|3@0+ (1,0) [0|7] "SED"  GWM
 SG_ TrlrHitchMsgTxt_D_Rq : 47|6@0+ (1,0) [0|63] "SED"  GWM
 SG_ TrlrHitchIcon_D_Rq : 36|4@0+ (1,0) [0|15] "SED"  GWM
 SG_ TrlrHitchChime_D_Rq : 39|3@0+ (1,0) [0|7] "SED"  GWM

BO_ 938 ParkAid_Aud_Warn_Stat: 8 IPMA_ADAS
 SG_ SidePrkSnsR2_D_Stat : 59|4@0+ (1,0) [0|15] "SED"  GWM
 SG_ SidePrkSnsR1_D_Stat : 63|4@0+ (1,0) [0|15] "SED"  GWM
 SG_ SidePrkSnsL2_D_Stat : 51|4@0+ (1,0) [0|15] "SED"  GWM
 SG_ ApaMde_D_Stat : 23|3@0+ (1,0) [0|7] "SED"  GWM
 SG_ ApaActvSd_D_Actl : 14|2@0+ (1,0) [0|3] "SED"  GWM
 SG_ PrkAidSwtch_B_Stat : 8|1@0+ (1,0) [0|1] "SED"  GWM
 SG_ ApaMde_D_Avail : 12|4@0+ (1,0) [0|15] "SED"  GWM
 SG_ PrkAidSnsFrCrnr_D_Stat : 47|4@0+ (1,0) [0|15] "SED"  GWM
 SG_ PrkAidSnsFrCntr_D_Stat : 35|4@0+ (1,0) [0|15] "SED"  GWM
 SG_ PrkAidSnsFlCrnr_D_Stat : 27|4@0+ (1,0) [0|15] "SED"  GWM
 SG_ PrkAidSnsFlCntr_D_Stat : 31|4@0+ (1,0) [0|15] "SED"  GWM
 SG_ PrkBrkEl_B_RqFap : 20|1@0+ (1,0) [0|1] "SED"  GWM,ABS_ESC
 SG_ RpaChime_D_Rq : 7|4@0+ (1,0) [0|15] "SED"  GWM
 SG_ FpaChime_D_Rq : 3|4@0+ (1,0) [0|15] "SED"  GWM
 SG_ PrkAidMsgTxt_D_Rq : 19|4@0+ (1,0) [0|15] "SED"  GWM
 SG_ SidePrkSnsL1_D_Stat : 55|4@0+ (1,0) [0|15] "SED"  GWM
 SG_ PrkAidAudioMute_B_Rq : 15|1@0+ (1,0) [0|1] "SED"  GWM

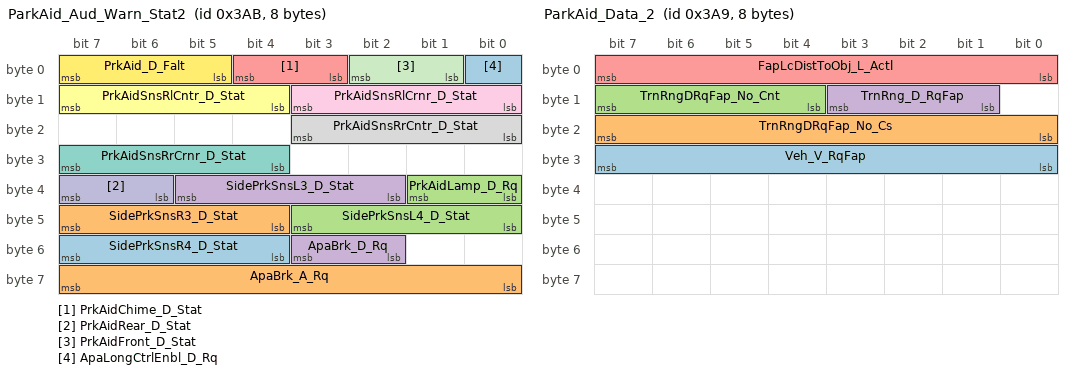
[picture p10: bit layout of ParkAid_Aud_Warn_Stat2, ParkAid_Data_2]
BO_ 939 ParkAid_Aud_Warn_Stat2: 8 IPMA_ADAS
 SG_ SidePrkSnsR4_D_Stat : 55|4@0+ (1,0) [0|15] "SED"  GWM
 SG_ SidePrkSnsR3_D_Stat : 47|4@0+ (1,0) [0|15] "SED"  GWM
 SG_ SidePrkSnsL4_D_Stat : 43|4@0+ (1,0) [0|15] "SED"  GWM
 SG_ SidePrkSnsL3_D_Stat : 37|4@0+ (1,0) [0|15] "SED"  GWM
 SG_ PrkAidChime_D_Stat : 4|2@0+ (1,0) [0|3] "SED"  GWM
 SG_ PrkAidSnsRlCntr_D_Stat : 15|4@0+ (1,0) [0|15] "SED"  GWM
 SG_ PrkAidSnsRrCrnr_D_Stat : 31|4@0+ (1,0) [0|15] "SED"  GWM
 SG_ PrkAidSnsRrCntr_D_Stat : 19|4@0+ (1,0) [0|15] "SED"  GWM
 SG_ PrkAidSnsRlCrnr_D_Stat : 11|4@0+ (1,0) [0|15] "SED"  GWM
 SG_ PrkAidRear_D_Stat : 39|2@0+ (1,0) [0|3] "SED"  GWM
 SG_ PrkAidFront_D_Stat : 2|2@0+ (1,0) [0|3] "SED"  GWM
 SG_ PrkAid_D_Falt : 7|3@0+ (1,0) [0|7] "SED"  GWM
 SG_ ApaLongCtrlEnbl_D_Rq : 0|1@0+ (1,0) [0|1] "SED"  SOBDMC_HPCM,ABS_ESC,ECM_HEV,PCM,GWM
 SG_ ApaBrk_A_Rq : 63|8@0+ (0.05,-12.75) [-12.75|0] "m/sec^2"  ABS_ESC,ECM_HEV,PCM,GWM
 SG_ PrkAidLamp_D_Rq : 33|2@0+ (1,0) [0|3] "SED"  GWM
 SG_ ApaBrk_D_Rq : 51|2@0+ (1,0) [0|3] "SED"  GWM

BO_ 937 ParkAid_Data_2: 8 IPMA_ADAS
 SG_ Veh_V_RqFap : 31|8@0+ (0.1,0) [0|25.5] "km/h"  ECM_HEV,PCM
 SG_ TrnRngDRqFap_No_Cs : 23|8@0+ (1,0) [0|255] "unitless"  ECM_HEV,SOBDMC_HPCM,PCM
 SG_ TrnRngDRqFap_No_Cnt : 15|4@0+ (1,0) [0|15] "unitless"  ECM_HEV,SOBDMC_HPCM,PCM
 SG_ TrnRng_D_RqFap : 11|3@0+ (1,0) [0|7] "SED"  SOBDMC_HPCM,ECM_HEV,PCM,GWM
 SG_ FapLcDistToObj_L_Actl : 7|8@0+ (0.01,0) [0|2.53] "meter"  ECM_HEV,PCM

BO_ 936 ParkAid_Data: 8 IPMA_ADAS
 SG_ ApaSys_D_Stat : 61|3@0+ (1,0) [0|7] "SED"  PSCM,GWM,ECM_HEV,PCM
 SG_ ApaSteWhl_D_RqDrv : 63|2@0+ (1,0) [0|3] "SED"  GWM
 SG_ ApaSteScanMde_D_Stat : 49|2@0+ (1,0) [0|3] "SED"  GWM
 SG_ ApaSelSapp_D_Stat : 51|2@0+ (1,0) [0|3] "SED"  GWM
 SG_ ApaSelPpa_D_Stat : 53|2@0+ (1,0) [0|3] "SED"  GWM
 SG_ ApaSelPoa_D_Stat : 55|2@0+ (1,0) [0|3] "SED"  GWM
 SG_ ApaScan_D_Stat : 41|2@0+ (1,0) [0|3] "SED"  GWM
 SG_ ApaLongCtl_D_RqDrv : 44|3@0+ (1,0) [0|7] "SED"  GWM
 SG_ ApaGearShif_D_RqDrv : 47|3@0+ (1,0) [0|7] "SED"  GWM
 SG_ ApaActvSide2_D_Stat : 33|2@0+ (1,0) [0|3] "SED"  GWM
 SG_ ApaAcsy_D_RqDrv : 36|3@0+ (1,0) [0|7] "SED"  GWM
 SG_ ApaTrgtDist_D_Stat : 11|4@0+ (1,0) [0|15] "SED"  GWM
 SG_ ApaMsgTxt_D_Rq : 15|4@0+ (1,0) [0|15] "SED"  GWM
 SG_ ApaChime_D_Rq : 39|3@0+ (1,0) [0|7] "SED"  GWM
 SG_ SAPPStatusCoding : 7|8@0+ (1,0) [0|255] "unitless"  GWM
 SG_ EPASExtAngleStatReq : 23|1@0+ (1,0) [0|1] "SED"  PSCM,GWM,ABS_ESC
 SG_ ExtSteeringAngleReq2 : 22|15@0+ (0.1,-1000) [-1000|2276.5] "Degrees"  GWM,PSCM
 SG_ ApaButtnPrssd_B_Stat : 58|1@0+ (1,0) [0|1] "SED"  GWM

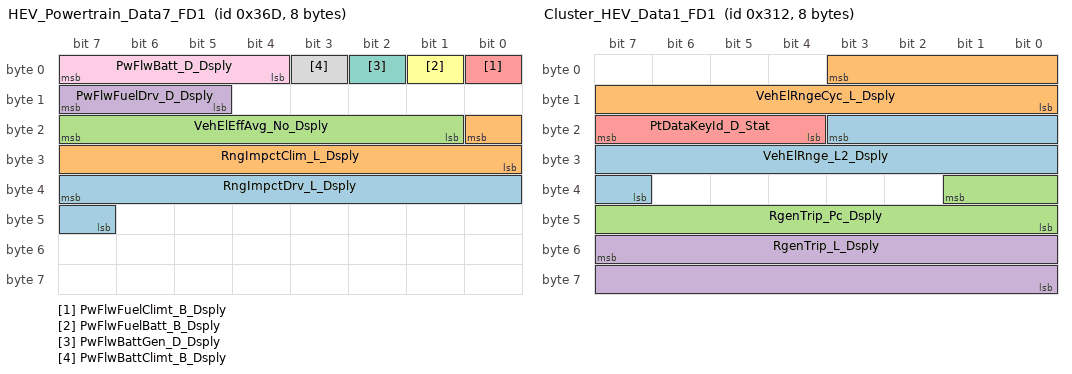
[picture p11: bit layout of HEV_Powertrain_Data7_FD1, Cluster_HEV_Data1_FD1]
BO_ 877 HEV_Powertrain_Data7_FD1: 8 SOBDMC_HPCM
 SG_ RngImpctDrv_L_Dsply : 39|9@0+ (1,-255) [-255|256] "km"  GWM
 SG_ RngImpctClim_L_Dsply : 16|9@0+ (1,-255) [-255|256] "km"  GWM
 SG_ VehElEffAvg_No_Dsply : 23|7@0+ (10,-100) [-100|1150] "wattHr/km"  GWM
 SG_ PwFlwFuelDrv_D_Dsply : 15|3@0+ (1,0) [0|7] "SED"  GWM
 SG_ PwFlwFuelClimt_B_Dsply : 0|1@0+ (1,0) [0|1] "SED"  GWM
 SG_ PwFlwFuelBatt_B_Dsply : 1|1@0+ (1,0) [0|1] "SED"  GWM
 SG_ PwFlwBattGen_D_Dsply : 2|1@0+ (1,0) [0|1] "SED"  GWM
 SG_ PwFlwBattClimt_B_Dsply : 3|1@0+ (1,0) [0|1] "SED"  GWM
 SG_ PwFlwBatt_D_Dsply : 7|4@0+ (1,0) [0|15] "SED"  GWM

BO_ 791 Cluster_HEV_Data8_FD1: 8 GWM
 SG_ AwdDrvMde_D2_Rq : 21|4@0+ (1,0) [0|15] "SED"  GENERIC
 SG_ StopStrtVThres_D_RqMnu : 17|2@0+ (1,0) [0|3] "SED" Vector__XXX
 SG_ EngAirFilt_B_RqReset : 48|1@0+ (1,0) [0|1] "SED"  GENERIC
 SG_ BattElEmotive_Pc_Dsply : 1|10@0+ (0.1,0) [0|102.1] "percent"  GENERIC
 SG_ HybMdeOvrrd_D_Rq : 7|2@0+ (1,0) [0|3] "SED"  SOBDMC_HPCM
 SG_ GpsElMdeSel_B_Rq : 50|1@0+ (1,0) [0|1] "SED"  SOBDMC_HPCM
 SG_ LongTermReset_B_Rq : 49|1@0+ (1,0) [0|1] "SED"  SOBDMC_HPCM
 SG_ EcoCcActv_B_Rq : 51|1@0+ (1,0) [0|1] "SED" Vector__XXX
 SG_ DrvEffLvl_No_Stat : 61|6@0+ (1,0) [0|61] "unitless"  SOBDMC_HPCM
 SG_ ChargeProfIDPref_Rq : 5|2@0+ (1,0) [0|3] "SED"  GENERIC
 SG_ ConsAvgTrip_Fe_Dsply : 31|24@0+ (0.0001,0) [0|1677.7215] "litre/100km"  GENERIC
 SG_ GrdAsstAllw_D_RqMnu : 23|2@0+ (1,0) [0|3] "SED"  SOBDMC_HPCM,ECM_HEV
 SG_ PlgOvrrdStrt_D_Cmd : 55|2@0+ (1,0) [0|3] "SED"  SOBDMC_HPCM
 SG_ EcoMde_D_RqMnu : 3|2@0+ (1,0) [0|3] "SED"  SOBDMC_HPCM
 SG_ EmotiveType_D_Dsply : 53|2@0+ (1,0) [0|3] "SED"  GENERIC
 SG_ VehElEffTrip2Reset_B_Rq : 62|1@0+ (1,0) [0|1] "SED" Vector__XXX
 SG_ VehElEffTrip1Reset_B_Rq : 63|1@0+ (1,0) [0|1] "SED" Vector__XXX

BO_ 786 Cluster_HEV_Data1_FD1: 8 SOBDMC_HPCM
 SG_ VehElRnge_L2_Dsply : 19|13@0+ (0.1,0) [0|818.9] "kilometer"  GWM
 SG_ VehElRngeCyc_L_Dsply : 3|12@0+ (0.1,0) [0|409.3] "km"  GENERIC,GWM
 SG_ RgenTrip_Pc_Dsply : 33|10@0+ (0.1,0) [0|102.3] "percent"  GENERIC,GWM
 SG_ RgenTrip_L_Dsply : 55|16@0+ (0.1,0) [0|6553.3] "kilometer"  GENERIC,GWM
 SG_ PtDataKeyId_D_Stat : 23|4@0+ (1,0) [0|15] "SED"  GWM

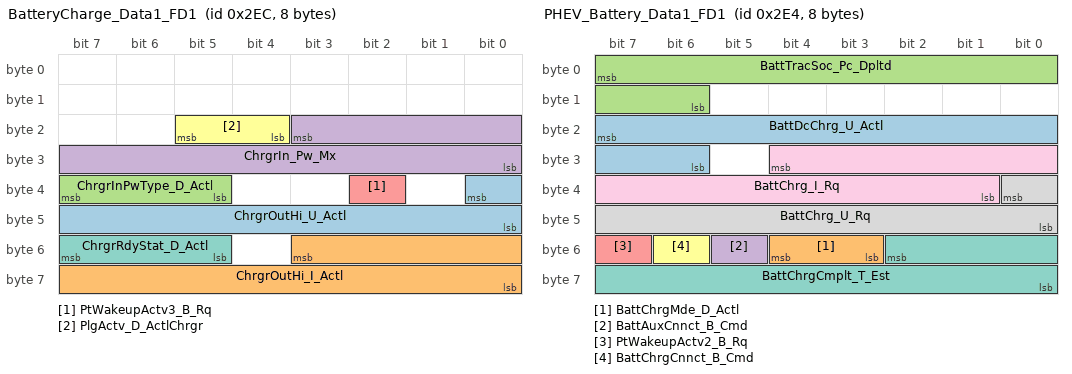
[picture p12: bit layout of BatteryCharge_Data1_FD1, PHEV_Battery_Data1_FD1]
BO_ 748 BatteryCharge_Data1_FD1: 8 GWM
 SG_ ChrgrOutHi_U_Actl : 32|9@0+ (1,0) [0|510] "volt"  SOBDMC_HPCM,GENERIC
 SG_ ChrgrOutHi_I_Actl : 51|12@0+ (0.1,0) [0|409.4] "ampere"  SOBDMC_HPCM,GENERIC
 SG_ ChrgrInPwType_D_Actl : 39|3@0+ (1,0) [0|7] "SED"  SOBDMC_HPCM,GENERIC
 SG_ ChrgrIn_Pw_Mx : 19|12@0+ (50,0) [0|204700] "watts"  ECM_HEV,SOBDMC_HPCM
 SG_ PtWakeupActv3_B_Rq : 34|1@0+ (1,0) [0|1] "SED"  GENERIC
 SG_ PlgActv_D_ActlChrgr : 21|2@0+ (1,0) [0|3] "SED"  SOBDMC_HPCM,ECM_HEV
 SG_ ChrgrRdyStat_D_Actl : 55|3@0+ (1,0) [0|7] "SED"  SOBDMC_HPCM,ECM_HEV

BO_ 740 PHEV_Battery_Data1_FD1: 8 GWM
 SG_ BattDcChrg_U_Actl : 23|10@0+ (0.5,0) [0|510.5] "volt"  GENERIC
 SG_ BattChrgMde_D_Actl : 52|2@0+ (1,0) [0|3] "SED"  GENERIC
 SG_ BattTracSoc_Pc_Dpltd : 7|10@0+ (0.1,0) [0|102.3] "percent"  SOBDMC_HPCM
 SG_ BattAuxCnnct_B_Cmd : 53|1@0+ (1,0) [0|1] "SED"  SOBDMC_HPCM,GENERIC
 SG_ PtWakeupActv2_B_Rq : 55|1@0+ (1,0) [0|1] "SED"  GENERIC
 SG_ BattChrgCnnct_B_Cmd : 54|1@0+ (1,0) [0|1] "SED"  GENERIC
 SG_ BattChrgCmplt_T_Est : 50|11@0+ (1,0) [0|2047] "minute"  GENERIC
 SG_ BattChrg_U_Rq : 32|9@0+ (1,0) [0|511] "volt"  SOBDMC_HPCM,GENERIC
 SG_ BattChrg_I_Rq : 28|12@0+ (0.1,0) [0|409.5] "ampere"  SOBDMC_HPCM,GENERIC

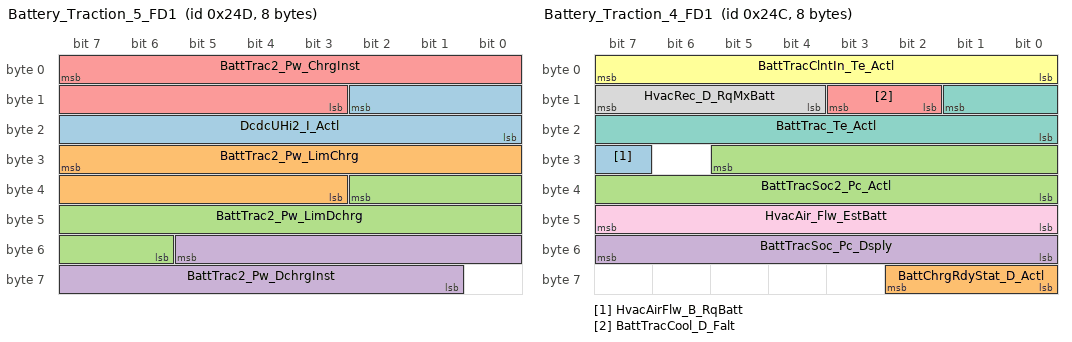
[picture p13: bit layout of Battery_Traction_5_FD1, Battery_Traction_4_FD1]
BO_ 589 Battery_Traction_5_FD1: 8 GWM
 SG_ DcdcUHi2_I_Actl : 10|11@0+ (0.1,0) [0|204.6] "ampere" Vector__XXX
 SG_ BattTrac2_Pw_LimChrg : 31|13@0+ (50,0) [0|409550] "watts"  SOBDMC_HPCM
 SG_ BattTrac2_Pw_LimDchrg : 34|13@0+ (50,0) [0|409550] "watts"  SOBDMC_HPCM
 SG_ BattTrac2_Pw_DchrgInst : 53|13@0+ (50,0) [0|409550] "watts"  SOBDMC_HPCM
 SG_ BattTrac2_Pw_ChrgInst : 7|13@0+ (50,0) [0|409550] "watts"  SOBDMC_HPCM

BO_ 588 Battery_Traction_4_FD1: 8 GWM
 SG_ HvacAirFlw_B_RqBatt : 31|1@0+ (1,0) [0|1] "SED"  SOBDMC_HPCM
 SG_ BattChrgRdyStat_D_Actl : 58|3@0+ (1,0) [0|7] "SED"  SOBDMC_HPCM,ECM_HEV
 SG_ BattTracSoc2_Pc_Actl : 29|14@0+ (0.01,0) [0|163.81] "%"  SOBDMC_HPCM,ECM_HEV
 SG_ BattTracSoc_Pc_Dsply : 55|8@0+ (0.5,0) [0|126.5] "Percent"  SOBDMC_HPCM
 SG_ BattTracCool_D_Falt : 11|2@0+ (1,0) [0|3] "SED"  GENERIC
 SG_ BattTracClntIn_Te_Actl : 7|8@0+ (1,-50) [-50|204] "degC"  GENERIC
 SG_ BattTrac_Te_Actl : 9|10@0+ (0.5,-50) [-50|460.5] "degC"  SOBDMC_HPCM,ECM_HEV
 SG_ HvacRec_D_RqMxBatt : 15|4@0+ (1,0) [0|15] "SED"  GENERIC
 SG_ HvacAir_Flw_EstBatt : 47|8@0+ (0.5,0) [0|127] "liter/second" Vector__XXX

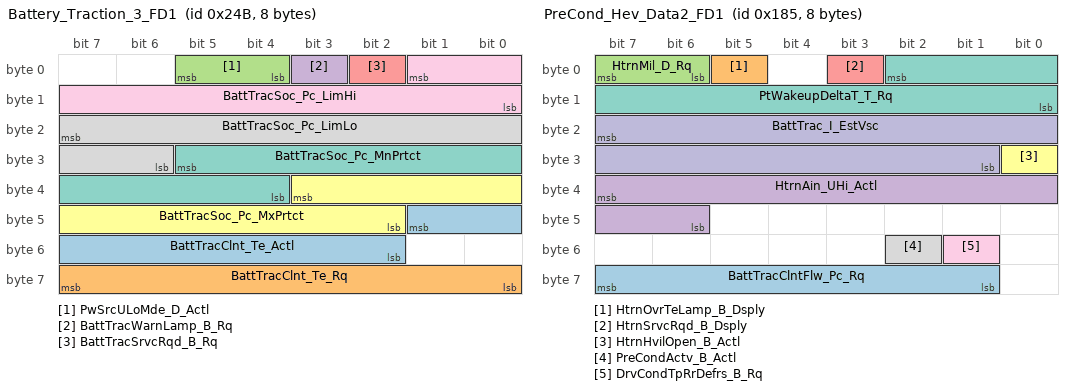
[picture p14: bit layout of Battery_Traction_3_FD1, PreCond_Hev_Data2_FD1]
BO_ 587 Battery_Traction_3_FD1: 8 GWM
 SG_ BattTracClnt_Te_Actl : 41|8@0+ (0.5,-60) [-60|66.5] "degC"  SOBDMC_HPCM
 SG_ BattTracClnt_Te_Rq : 63|8@0+ (0.5,-60) [-60|67.5] "degC"  GENERIC
 SG_ PwSrcULoMde_D_Actl : 5|2@0+ (1,0) [0|3] "SED" Vector__XXX
 SG_ BattTracWarnLamp_B_Rq : 3|1@0+ (1,0) [0|1] "SED"  GENERIC
 SG_ BattTracSrvcRqd_B_Rq : 2|1@0+ (1,0) [0|1] "SED"  GENERIC
 SG_ BattTracSoc_Pc_MxPrtct : 35|10@0+ (0.1,0) [0|100] "%"  SOBDMC_HPCM
 SG_ BattTracSoc_Pc_MnPrtct : 29|10@0+ (0.1,0) [0|100] "%"  SOBDMC_HPCM,ECM_HEV
 SG_ BattTracSoc_Pc_LimLo : 23|10@0+ (0.1,0) [0|100] "%"  SOBDMC_HPCM,ECM_HEV
 SG_ BattTracSoc_Pc_LimHi : 1|10@0+ (0.1,0) [0|100] "%"  SOBDMC_HPCM,ECM_HEV

BO_ 389 PreCond_Hev_Data2_FD1: 8 SOBDMC_HPCM
 SG_ BattTracClntFlw_Pc_Rq : 63|7@0+ (1,0) [0|127] "percent"  GWM,GENERIC
 SG_ HtrnOvrTeLamp_B_Dsply : 5|1@0+ (1,0) [0|1] "SED"  GWM,GENERIC
 SG_ HtrnMil_D_Rq : 7|2@0+ (1,0) [0|3] "SED"  GWM
 SG_ HtrnAin_UHi_Actl : 39|10@0+ (0.5,0) [0|510.5] "volt"  GWM,ECM_HEV
 SG_ HtrnSrvcRqd_B_Dsply : 3|1@0+ (1,0) [0|1] "SED"  GWM
 SG_ HtrnHvilOpen_B_Actl : 24|1@0+ (1,0) [0|1] "SED"  GWM
 SG_ PtWakeupDeltaT_T_Rq : 2|11@0+ (1,0) [0|2045] "minute"  GWM,GENERIC
 SG_ PreCondActv_B_Actl : 50|1@0+ (1,0) [0|1] "SED"  GWM,ECM_HEV
 SG_ DrvCondTpRrDefrs_B_Rq : 49|1@0+ (1,0) [0|1] "SED"  GWM,GENERIC
 SG_ BattTrac_I_EstVsc : 23|15@0+ (0.05,-750) [-750|888.25] "Amps"  GWM

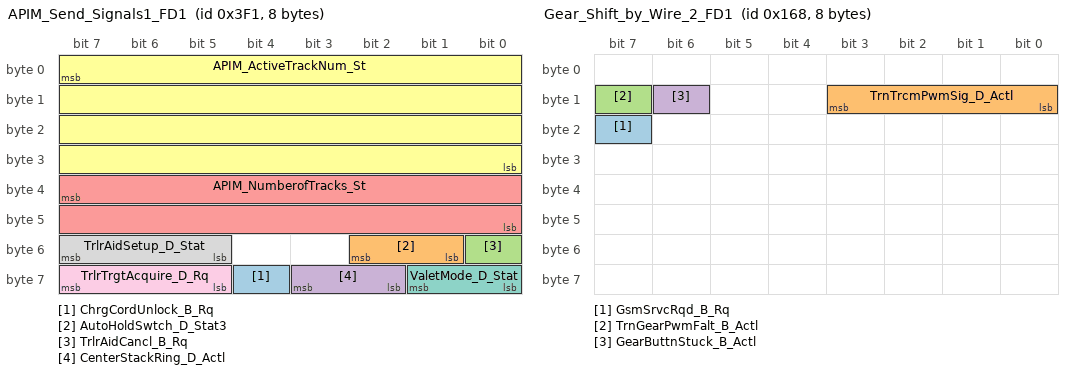
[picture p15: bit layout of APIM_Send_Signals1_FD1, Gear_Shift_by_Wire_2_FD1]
BO_ 1009 APIM_Send_Signals1_FD1: 8 GWM
 SG_ ChrgCordUnlock_B_Rq : 60|1@0+ (1,0) [0|1] "SED"  GENERIC
 SG_ AutoHoldSwtch_D_Stat3 : 50|2@0+ (1,0) [0|3] "SED"  ABS_ESC
 SG_ TrlrAidCancl_B_Rq : 48|1@0+ (1,0) [0|1] "SED"  IPMA_ADAS
 SG_ CenterStackRing_D_Actl : 59|2@0+ (1,0) [0|3] "SED"  GENERIC
 SG_ APIM_NumberofTracks_St : 39|16@0+ (1,0) [0|65535] "unitless"  GENERIC
 SG_ APIM_ActiveTrackNum_St : 7|32@0+ (1,0) [0|4294967295] "unitless"  GENERIC
 SG_ ValetMode_D_Stat : 57|2@0+ (1,0) [0|3] "SED"  GENERIC
 SG_ TrlrAidSetup_D_Stat : 55|3@0+ (1,0) [0|7] "SED"  GENERIC
 SG_ TrlrTrgtAcquire_D_Rq : 63|3@0+ (1,0) [0|7] "SED"  GENERIC

BO_ 360 Gear_Shift_by_Wire_2_FD1: 8 GWM
 SG_ GsmSrvcRqd_B_Rq : 23|1@0+ (1,0) [0|1] "SED"  SOBDMC_HPCM
 SG_ TrnTrcmPwmSig_D_Actl : 11|4@0+ (1,0) [0|15] "SED" Vector__XXX
 SG_ TrnGearPwmFalt_B_Actl : 15|1@0+ (1,0) [0|1] "SED"  SOBDMC_HPCM,PCM
 SG_ GearButtnStuck_B_Actl : 14|1@0+ (1,0) [0|1] "SED"  SOBDMC_HPCM,PCM

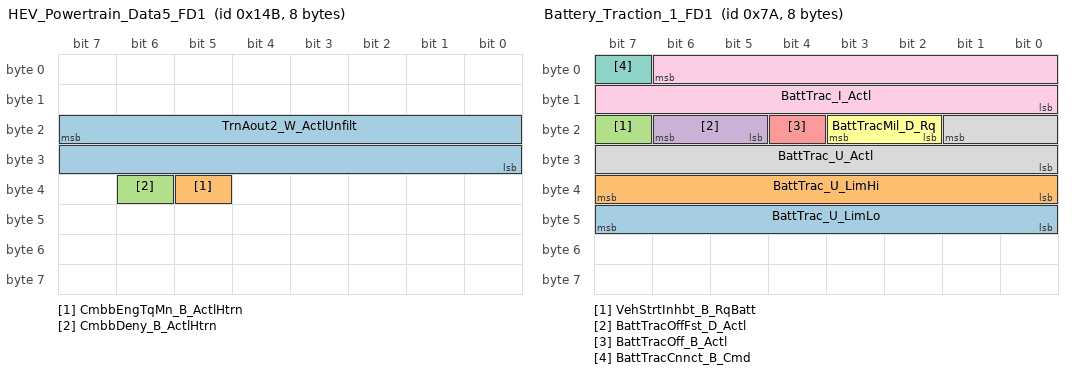
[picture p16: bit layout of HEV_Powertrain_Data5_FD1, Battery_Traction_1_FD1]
BO_ 331 HEV_Powertrain_Data5_FD1: 8 SOBDMC_HPCM
 SG_ TrnAout2_W_ActlUnfilt : 23|16@0+ (0.1,-3276.5) [-3276.5|3276.8] "rad/s"  GWM
 SG_ CmbbEngTqMn_B_ActlHtrn : 37|1@0+ (1,0) [0|1] "SED"  GWM,ECM_HEV
 SG_ CmbbDeny_B_ActlHtrn : 38|1@0+ (1,0) [0|1] "SED"  GWM,ECM_HEV

BO_ 140 CruiseCtrl_StrgData2_FD1: 8 GWM
 SG_ DcacPwResetBttn_D_Stat : 36|2@0+ (1,0) [0|3] "SED"  ECM_HEV
 SG_ CcAslButtnIndxIncPress2 : 18|1@0+ (1,0) [0|1] "SED" Vector__XXX
 SG_ SteWhlSwtchMde_D_Stat : 23|2@0+ (1,0) [0|3] "SED"  GENERIC
 SG_ CcAslButtnIndxDecPress2 : 19|1@0+ (1,0) [0|1] "SED" Vector__XXX
 SG_ CcAslButtnResIncPress3 : 29|1@0+ (1,0) [0|1] "SED" Vector__XXX
 SG_ CcButtnOnPress3 : 37|1@0+ (1,0) [0|1] "SED" Vector__XXX
 SG_ CcButtnOnOffPress3 : 38|1@0+ (1,0) [0|1] "SED" Vector__XXX
 SG_ CcButtnOnOffCnclPress3 : 39|1@0+ (1,0) [0|1] "SED" Vector__XXX
 SG_ CcButtnOffPress3 : 24|1@0+ (1,0) [0|1] "SED" Vector__XXX
 SG_ CcAsllButtnResPress3 : 25|1@0+ (1,0) [0|1] "SED" Vector__XXX
 SG_ CcAslButtnSetPress3 : 26|1@0+ (1,0) [0|1] "SED" Vector__XXX
 SG_ CcAslButtnSetIncPress3 : 27|1@0+ (1,0) [0|1] "SED" Vector__XXX
 SG_ CcAslButtnSetDecPress3 : 28|1@0+ (1,0) [0|1] "SED" Vector__XXX
 SG_ CcAslButtnResDecPress3 : 30|1@0+ (1,0) [0|1] "SED" Vector__XXX
 SG_ CcAslButtnOnPress3 : 31|1@0+ (1,0) [0|1] "SED" Vector__XXX
 SG_ CcAslButtnOnOffCncl3 : 16|1@0+ (1,0) [0|1] "SED" Vector__XXX
 SG_ CcAslButtnDeny_B_Actl3 : 20|1@0+ (1,0) [0|1] "SED" Vector__XXX
 SG_ CcAslButtnCnclPress3 : 8|1@0+ (1,0) [0|1] "SED" Vector__XXX
 SG_ AslButtnOnOffPress3 : 9|1@0+ (1,0) [0|1] "SED" Vector__XXX
 SG_ AslButtnOnOffCnclPress2 : 10|1@0+ (1,0) [0|1] "SED" Vector__XXX
 SG_ CcAslButtnOffCnclPress2 : 17|1@0+ (1,0) [0|1] "SED" Vector__XXX
 SG_ CcAslButtnCnclResPress2 : 21|1@0+ (1,0) [0|1] "SED" Vector__XXX

BO_ 122 Battery_Traction_1_FD1: 8 GWM
 SG_ BattTrac_U_LimLo : 47|8@0+ (2,0) [0|510] "volt"  SOBDMC_HPCM
 SG_ BattTrac_U_LimHi : 39|8@0+ (2,0) [0|510] "volt"  SOBDMC_HPCM
 SG_ VehStrtInhbt_B_RqBatt : 23|1@0+ (1,0) [0|1] "SED"  SOBDMC_HPCM
 SG_ BattTracOffFst_D_Actl : 22|2@0+ (1,0) [0|3] "SED"  SOBDMC_HPCM,ECM_HEV
 SG_ BattTracOff_B_Actl : 20|1@0+ (1,0) [0|1] "SED"  SOBDMC_HPCM
 SG_ BattTracMil_D_Rq : 19|2@0+ (1,0) [0|3] "SED"  ECM_HEV
 SG_ BattTracCnnct_B_Cmd : 7|1@0+ (1,0) [0|1] "SED"  SOBDMC_HPCM,ECM_HEV
 SG_ BattTrac_U_Actl : 17|10@0+ (0.5,0) [0|510.5] "Volts"  SOBDMC_HPCM
 SG_ BattTrac_I_Actl : 6|15@0+ (0.05,-750) [-750|888.25] "Amps"  SOBDMC_HPCM

BO_TX_BU_ 1137 : SOBDMC_HPCM,PCM;
CM_ SG_ 1112 BattTracClntPmp_D_Stat "48V mHEV: ECM_HEVDSL is Tx,  MHT HEV: PCM_HEV is Tx,  Powersplit HEV: SOBDMC_HPCM is Tx";
CM_ SG_ 1050 Outside_Air_Temp_Stat "Filtered value, i.e. same as disply for customer";
CM_ BO_ 1124 "HS3 APIM Sync Gen3 Tx 0x464.  FrameGateway to 0x467 on HS1, HS2, HS3 and MS1.";
CM_ SG_ 791 ChargeProfIDPref_Rq "Object:ChargeProfIDPref_St
Status of the charge preference for the current Charge Profile.";
CM_ BO_ 1009 "APIM Tx";
CM_ SG_ 1009 CenterStackRing_D_Actl "The Center Stack sends the CPLR a signal to turn On or Off the light Ring, This is a customer selectable preference switch";
CM_ SG_ 1009 APIM_NumberofTracks_St "Object NumberofTracks";
CM_ SG_ 1009 APIM_ActiveTrackNum_St "Object.ActiveTrackNum";
CM_ SG_ 360 GsmSrvcRqd_B_Rq "Signal not transmitted on vehicles that do not have shift by wire.";
CM_ SG_ 360 TrnTrcmPwmSig_D_Actl "Signal not transmitted on vehicles that do not have shift by wire.";
CM_ SG_ 360 TrnGearPwmFalt_B_Actl "Signal not transmitted on vehicles that do not have shift by wire.";
CM_ SG_ 360 GearButtnStuck_B_Actl "Signal not transmitted on vehicles that do not have shift by wire.";
BA_DEF_ SG_  "U_CDX706_MY2023_Tx" ENUM  "No","Yes";
BA_DEF_ SG_  "U_CDX706_MY2023_Rx" ENUM  "No","Yes";
BA_DEF_ BO_  "AuthFreshnessCounterSyncAttempt" INT 0 2;
BA_DEF_ BO_  "VFrameFormat" ENUM  "StandardCAN","ExtendedCAN","reserved","reserved","reserved","reserved","reserved","reserved","reserved","reserved","reserved","reserved","reserved","reserved","StandardCAN_FD","ExtendedCAN_FD";
BA_DEF_ SG_  "GenSigSendType" ENUM  "Cyclic","OnWrite","vector_leerstring","OnChange","vector_leerstring","IfActive","vector_leerstring","NoSigSendType";
BA_DEF_ SG_  "GenSigInactiveValue" INT 0 100000;
BA_DEF_ SG_  "WakeupSignal" ENUM  "No","Yes";
BA_DEF_ SG_  "UsedOnPgmDBC" ENUM  "No","Yes";
BA_DEF_ SG_  "GenSigStartValueInteger" INT 0 1000000000;
BA_DEF_ SG_  "ContentDependant" ENUM  "No","Yes";
BA_DEF_ SG_  "MetaData" ENUM  "No","Yes";
BA_DEF_ SG_  "GenSigStartValue" HEX 0 268435455;
BA_DEF_ SG_  "U_CX727_MY2021_Rx" ENUM  "No","Yes";
BA_DEF_ SG_  "U_P702_MY2021_Rx" ENUM  "No","Yes";
BA_DEF_ SG_  "U_T6_MCA_MY2020_Rx" ENUM  "No","Yes";
BA_DEF_ SG_  "ECGUsedRxSignal" ENUM  "No","Yes";
BA_DEF_ SG_  "U_CD542_MY2021_Rx" ENUM  "No","Yes";
BA_DEF_ SG_  "U_U55X_MY2022_Rx" ENUM  "No","Yes";
BA_DEF_ SG_  "U_CD764_MY2022_Rx" ENUM  "No","Yes";
BA_DEF_ SG_  "U_CX727_MY2021_Tx" ENUM  "No","Yes";
BA_DEF_ SG_  "U_P702_MY2021_Tx" ENUM  "No","Yes";
BA_DEF_ SG_  "U_T6_MCA_MY2020_Tx" ENUM  "No","Yes";
BA_DEF_ SG_  "ECGUsedTxSignal" ENUM  "No","Yes";
BA_DEF_ SG_  "U_CD542_MY2021_Tx" ENUM  "No","Yes";
BA_DEF_ SG_  "U_U55X_MY2022_Tx" ENUM  "No","Yes";
BA_DEF_ SG_  "U_CD764_MY2022_Tx" ENUM  "No","Yes";
BA_DEF_ BO_  "GenMsgILSupport" ENUM  "No","Yes";
BA_DEF_ BO_  "DiagResponse" ENUM  "No","Yes";
BA_DEF_ BO_  "DiagRequest" ENUM  "No","Yes";
BA_DEF_ BO_  "TpTxIndex" INT 0 536870911;
BA_DEF_ BO_  "DiagState" ENUM  "No","Yes";
BA_DEF_ BO_  "TpApplType" STRING ;
BA_DEF_ BO_  "NmAsrMessage" ENUM  "No","Yes";
BA_DEF_ BO_  "SCP_AuthInfoTxLength" INT 0 512;
BA_DEF_ BO_  "SCP_FreshnessValueTxLength" INT 0 512;
BA_DEF_ BO_  "SCP_FreshnessValueLength" INT 0 512;
BA_DEF_ BO_  "OvtpPushApplication" ENUM  "FALSE","TRUE";
BA_DEF_ BO_  "GenMsgSendType" ENUM  "FixedPeriodic","Event","EnabledPeriodic","NotUsed","NotUsed","EventPeriodic","NotUsed","NotUsed","NoMsgSendType";
BA_DEF_ BO_  "GenMsgCycleTime" INT 0 100000;
BA_DEF_ BO_  "GenMsgDelayTime" INT 0 1000;
BA_DEF_ BO_  "GenMsgNrOfRepetition" INT 0 100;
BA_DEF_ BO_  "GenMsgStartDelayTime" INT 0 10000;
BA_DEF_ BO_  "EventRateOfChange" INT 10 10000;
BA_DEF_ BO_  "FrameGatewayId" HEX 0 1407;
BA_DEF_ BO_  "NetworkInitialization" ENUM  "No","Yes";
BA_DEF_ BO_  "FrameGatewayNetwork" STRING ;
BA_DEF_ BO_  "FrameRouting" STRING ;
BA_DEF_DEF_  "U_CDX706_MY2023_Tx" "No";
BA_DEF_DEF_  "U_CDX706_MY2023_Rx" "No";
BA_DEF_DEF_  "AuthFreshnessCounterSyncAttempt" 2;
BA_DEF_DEF_  "VFrameFormat" "ExtendedCAN_FD";
BA_DEF_DEF_  "GenSigSendType" "NoSigSendType";
BA_DEF_DEF_  "GenSigInactiveValue" 0;
BA_DEF_DEF_  "WakeupSignal" "No";
BA_DEF_DEF_  "UsedOnPgmDBC" "Yes";
BA_DEF_DEF_  "GenSigStartValueInteger" 0;
BA_DEF_DEF_  "ContentDependant" "No";
BA_DEF_DEF_  "MetaData" "No";
BA_DEF_DEF_  "GenSigStartValue" 0;
BA_DEF_DEF_  "U_CX727_MY2021_Rx" "No";
BA_DEF_DEF_  "U_P702_MY2021_Rx" "No";
BA_DEF_DEF_  "U_T6_MCA_MY2020_Rx" "No";
BA_DEF_DEF_  "ECGUsedRxSignal" "No";
BA_DEF_DEF_  "U_CD542_MY2021_Rx" "No";
BA_DEF_DEF_  "U_U55X_MY2022_Rx" "No";
BA_DEF_DEF_  "U_CD764_MY2022_Rx" "No";
BA_DEF_DEF_  "U_CX727_MY2021_Tx" "No";
BA_DEF_DEF_  "U_P702_MY2021_Tx" "No";
BA_DEF_DEF_  "U_T6_MCA_MY2020_Tx" "No";
BA_DEF_DEF_  "ECGUsedTxSignal" "No";
BA_DEF_DEF_  "U_CD542_MY2021_Tx" "No";
BA_DEF_DEF_  "U_U55X_MY2022_Tx" "No";
BA_DEF_DEF_  "U_CD764_MY2022_Tx" "No";
BA_DEF_DEF_  "GenMsgILSupport" "Yes";
BA_DEF_DEF_  "DiagResponse" "No";
BA_DEF_DEF_  "DiagRequest" "No";
BA_DEF_DEF_  "TpTxIndex" 0;
BA_DEF_DEF_  "DiagState" "No";
BA_DEF_DEF_  "TpApplType" "";
BA_DEF_DEF_  "NmAsrMessage" "No";
BA_DEF_DEF_  "SCP_AuthInfoTxLength" 53;
BA_DEF_DEF_  "SCP_FreshnessValueTxLength" 11;
BA_DEF_DEF_  "SCP_FreshnessValueLength" 64;
BA_DEF_DEF_  "OvtpPushApplication" "FALSE";
BA_DEF_DEF_  "GenMsgSendType" "NoMsgSendType";
BA_DEF_DEF_  "GenMsgCycleTime" 0;
BA_DEF_DEF_  "GenMsgDelayTime" 20;
BA_DEF_DEF_  "GenMsgNrOfRepetition" 1;
BA_DEF_DEF_  "GenMsgStartDelayTime" 0;
BA_DEF_DEF_  "EventRateOfChange" 10000;
BA_DEF_DEF_  "FrameGatewayId" 0;
BA_DEF_DEF_  "NetworkInitialization" "Yes";
BA_DEF_DEF_  "FrameGatewayNetwork" "NONE";
BA_DEF_DEF_  "FrameRouting" "";
BA_ "FrameGatewayId" BO_ 1108 1108;
BA_ "FrameGatewayNetwork" BO_ 1108 "HS2_CAN";
BA_ "FrameRouting" BO_ 1108 "HS2_CAN,0x454;";
BA_ "VFrameFormat" BO_ 1108 14;
BA_ "FrameGatewayId" BO_ 261 261;
BA_ "FrameGatewayNetwork" BO_ 261 "HS3_CAN";
BA_ "FrameRouting" BO_ 261 "HS3_CAN,0x105;";
BA_ "VFrameFormat" BO_ 261 14;
BA_ "FrameRouting" BO_ 1146 "HS3_CAN,0x47A;MS1_CAN,0x44A;HS2_CAN,0x47A;";
BA_ "VFrameFormat" BO_ 1146 14;
BA_ "FrameGatewayId" BO_ 533 533;
BA_ "FrameGatewayNetwork" BO_ 533 "HS3_CAN";
BA_ "FrameRouting" BO_ 533 "HS3_CAN,0x215;";
BA_ "VFrameFormat" BO_ 533 14;
BA_ "FrameGatewayId" BO_ 778 778;
BA_ "FrameGatewayNetwork" BO_ 778 "HS3_CAN";
BA_ "FrameRouting" BO_ 778 "HS3_CAN,0x30A;";
BA_ "VFrameFormat" BO_ 778 14;
BA_ "FrameGatewayId" BO_ 1041 1041;
BA_ "FrameGatewayNetwork" BO_ 1041 "HS1_CAN";
BA_ "FrameRouting" BO_ 1041 "HS1_CAN,0x411;";
BA_ "VFrameFormat" BO_ 1041 14;
BA_ "FrameGatewayId" BO_ 1067 1067;
BA_ "FrameGatewayNetwork" BO_ 1067 "HS1_CAN";
BA_ "FrameRouting" BO_ 1067 "HS1_CAN,0x42B;";
BA_ "VFrameFormat" BO_ 1067 14;
BA_ "FrameGatewayId" BO_ 1118 1118;
BA_ "FrameGatewayNetwork" BO_ 1118 "HS5_CAN";
BA_ "FrameRouting" BO_ 1118 "HS5_CAN,0x45E;";
BA_ "VFrameFormat" BO_ 1118 14;
BA_ "GenMsgSendType" BO_ 1040 0;
BA_ "GenMsgCycleTime" BO_ 1040 100;
BA_ "VFrameFormat" BO_ 1040 14;
BA_ "GenMsgSendType" BO_ 1144 5;
BA_ "GenMsgCycleTime" BO_ 1144 1000;
BA_ "VFrameFormat" BO_ 1144 14;
BA_ "FrameGatewayId" BO_ 1112 1112;
BA_ "FrameGatewayNetwork" BO_ 1112 "HS5_CAN";
BA_ "FrameRouting" BO_ 1112 "HS5_CAN,0x458;";
BA_ "VFrameFormat" BO_ 1112 14;
BA_ "FrameGatewayId" BO_ 139 139;
BA_ "FrameGatewayNetwork" BO_ 139 "HS2_CAN";
BA_ "FrameRouting" BO_ 139 "HS2_CAN,0x8B;";
BA_ "VFrameFormat" BO_ 139 14;
BA_ "FrameGatewayId" BO_ 1121 1121;
BA_ "FrameGatewayNetwork" BO_ 1121 "HS2_CAN";
BA_ "FrameRouting" BO_ 1121 "HS2_CAN,0x461;";
BA_ "VFrameFormat" BO_ 1121 14;
BA_ "FrameGatewayId" BO_ 1120 1120;
BA_ "FrameGatewayNetwork" BO_ 1120 "HS2_CAN";
BA_ "FrameRouting" BO_ 1120 "HS2_CAN,0x460;";
BA_ "VFrameFormat" BO_ 1120 14;
BA_ "FrameGatewayId" BO_ 1050 1050;
BA_ "FrameGatewayNetwork" BO_ 1050 "MS1_CAN";
BA_ "FrameRouting" BO_ 1050 "MS1_CAN,0x41A;";
BA_ "VFrameFormat" BO_ 1050 14;
BA_ "FrameGatewayId" BO_ 621 621;
BA_ "FrameGatewayNetwork" BO_ 621 "HS4_CAN";
BA_ "FrameRouting" BO_ 621 "HS4_CAN,0x26D;";
BA_ "VFrameFormat" BO_ 621 14;
BA_ "FrameGatewayId" BO_ 1124 1124;
BA_ "FrameGatewayNetwork" BO_ 1124 "HS3_CAN";
BA_ "FrameRouting" BO_ 1124 "HS3_CAN,0x464;";
BA_ "VFrameFormat" BO_ 1124 14;
BA_ "GenMsgSendType" BO_ 1137 0;
BA_ "GenMsgCycleTime" BO_ 1137 1000;
BA_ "VFrameFormat" BO_ 1137 14;
BA_ "GenMsgSendType" BO_ 1255 0;
BA_ "GenMsgCycleTime" BO_ 1255 1000;
BA_ "VFrameFormat" BO_ 1255 14;
BA_ "GenMsgSendType" BO_ 1254 0;
BA_ "GenMsgCycleTime" BO_ 1254 1000;
BA_ "VFrameFormat" BO_ 1254 14;
BA_ "GenMsgSendType" BO_ 1253 0;
BA_ "GenMsgCycleTime" BO_ 1253 1000;
BA_ "VFrameFormat" BO_ 1253 14;
BA_ "GenMsgSendType" BO_ 1252 0;
BA_ "GenMsgCycleTime" BO_ 1252 1000;
BA_ "VFrameFormat" BO_ 1252 14;
BA_ "GenMsgSendType" BO_ 1251 0;
BA_ "GenMsgCycleTime" BO_ 1251 1000;
BA_ "VFrameFormat" BO_ 1251 14;
BA_ "GenMsgSendType" BO_ 1250 0;
BA_ "GenMsgCycleTime" BO_ 1250 1000;
BA_ "VFrameFormat" BO_ 1250 14;
BA_ "GenMsgSendType" BO_ 1249 0;
BA_ "GenMsgCycleTime" BO_ 1249 1000;
BA_ "VFrameFormat" BO_ 1249 14;
BA_ "GenMsgSendType" BO_ 1248 0;
BA_ "GenMsgCycleTime" BO_ 1248 1000;
BA_ "VFrameFormat" BO_ 1248 14;
BA_ "TpTxIndex" BO_ 2610988248 463504600;
BA_ "GenMsgSendType" BO_ 2610988248 1;
BA_ "GenMsgDelayTime" BO_ 2610988248 0;
BA_ "NetworkInitialization" BO_ 2610988248 0;
BA_ "GenMsgSendType" BO_ 1113 0;
BA_ "GenMsgCycleTime" BO_ 1113 50;
BA_ "VFrameFormat" BO_ 1113 14;
BA_ "GenMsgSendType" BO_ 1105 5;
BA_ "GenMsgCycleTime" BO_ 1105 1000;
BA_ "VFrameFormat" BO_ 1105 14;
BA_ "GenMsgSendType" BO_ 938 5;
BA_ "GenMsgCycleTime" BO_ 938 200;
BA_ "VFrameFormat" BO_ 938 14;
BA_ "GenMsgSendType" BO_ 939 5;
BA_ "GenMsgCycleTime" BO_ 939 200;
BA_ "VFrameFormat" BO_ 939 14;
BA_ "GenMsgSendType" BO_ 937 0;
BA_ "GenMsgCycleTime" BO_ 937 20;
BA_ "GenMsgDelayTime" BO_ 937 10;
BA_ "VFrameFormat" BO_ 937 14;
BA_ "GenMsgSendType" BO_ 936 0;
BA_ "GenMsgCycleTime" BO_ 936 20;
BA_ "GenMsgDelayTime" BO_ 936 10;
BA_ "VFrameFormat" BO_ 936 14;
BA_ "GenMsgSendType" BO_ 877 5;
BA_ "GenMsgCycleTime" BO_ 877 1000;
BA_ "VFrameFormat" BO_ 877 14;
BA_ "FrameGatewayId" BO_ 791 791;
BA_ "FrameGatewayNetwork" BO_ 791 "HS3_CAN";
BA_ "FrameRouting" BO_ 791 "HS3_CAN,0x317;";
BA_ "VFrameFormat" BO_ 791 14;
BA_ "GenMsgSendType" BO_ 786 0;
BA_ "GenMsgCycleTime" BO_ 786 100;
BA_ "VFrameFormat" BO_ 786 14;
BA_ "FrameGatewayId" BO_ 748 748;
BA_ "FrameGatewayNetwork" BO_ 748 "HS5_CAN";
BA_ "FrameRouting" BO_ 748 "HS5_CAN,0x2EC;";
BA_ "VFrameFormat" BO_ 748 14;
BA_ "FrameGatewayId" BO_ 740 740;
BA_ "FrameGatewayNetwork" BO_ 740 "HS5_CAN";
BA_ "FrameRouting" BO_ 740 "HS5_CAN,0x2E4;";
BA_ "VFrameFormat" BO_ 740 14;
BA_ "FrameGatewayId" BO_ 589 589;
BA_ "FrameGatewayNetwork" BO_ 589 "HS5_CAN";
BA_ "FrameRouting" BO_ 589 "HS5_CAN,0x24D;";
BA_ "VFrameFormat" BO_ 589 14;
BA_ "FrameGatewayId" BO_ 588 588;
BA_ "FrameGatewayNetwork" BO_ 588 "HS5_CAN";
BA_ "FrameRouting" BO_ 588 "HS5_CAN,0x24C;";
BA_ "VFrameFormat" BO_ 588 14;
BA_ "FrameGatewayId" BO_ 587 587;
BA_ "FrameGatewayNetwork" BO_ 587 "HS5_CAN";
BA_ "FrameRouting" BO_ 587 "HS5_CAN,0x24B;";
BA_ "VFrameFormat" BO_ 587 14;
BA_ "GenMsgSendType" BO_ 389 0;
BA_ "GenMsgCycleTime" BO_ 389 100;
BA_ "VFrameFormat" BO_ 389 14;
BA_ "FrameGatewayId" BO_ 1009 1009;
BA_ "FrameGatewayNetwork" BO_ 1009 "HS3_CAN";
BA_ "FrameRouting" BO_ 1009 "HS3_CAN,0x3F1;";
BA_ "VFrameFormat" BO_ 1009 14;
BA_ "FrameGatewayId" BO_ 360 360;
BA_ "FrameGatewayNetwork" BO_ 360 "HS2_CAN";
BA_ "FrameRouting" BO_ 360 "HS2_CAN,0x168;";
BA_ "VFrameFormat" BO_ 360 14;
BA_ "GenMsgSendType" BO_ 331 0;
BA_ "GenMsgCycleTime" BO_ 331 10;
BA_ "GenMsgDelayTime" BO_ 331 0;
BA_ "VFrameFormat" BO_ 331 14;
BA_ "FrameGatewayId" BO_ 140 140;
BA_ "FrameGatewayNetwork" BO_ 140 "HS3_CAN";
BA_ "FrameRouting" BO_ 140 "HS3_CAN,0x8C;";
BA_ "VFrameFormat" BO_ 140 14;
BA_ "FrameGatewayId" BO_ 122 122;
BA_ "FrameGatewayNetwork" BO_ 122 "HS5_CAN";
BA_ "FrameRouting" BO_ 122 "HS5_CAN,0x7A;";
BA_ "VFrameFormat" BO_ 122 14;
BA_ "U_CX727_MY2021_Rx" SG_ 1108 RCMSerialNoByte8 1;
BA_ "U_P702_MY2021_Rx" SG_ 1108 RCMSerialNoByte8 1;
BA_ "U_T6_MCA_MY2020_Rx" SG_ 1108 RCMSerialNoByte8 1;
BA_ "U_CD542_MY2021_Rx" SG_ 1108 RCMSerialNoByte8 1;
BA_ "U_U55X_MY2022_Rx" SG_ 1108 RCMSerialNoByte8 1;
BA_ "U_CD764_MY2022_Rx" SG_ 1108 RCMSerialNoByte8 1;
BA_ "U_CX727_MY2021_Rx" SG_ 1108 RCMSerialNoByte7 1;
BA_ "U_P702_MY2021_Rx" SG_ 1108 RCMSerialNoByte7 1;
BA_ "U_T6_MCA_MY2020_Rx" SG_ 1108 RCMSerialNoByte7 1;
BA_ "U_CD542_MY2021_Rx" SG_ 1108 RCMSerialNoByte7 1;
BA_ "U_U55X_MY2022_Rx" SG_ 1108 RCMSerialNoByte7 1;
BA_ "U_CD764_MY2022_Rx" SG_ 1108 RCMSerialNoByte7 1;
BA_ "U_CX727_MY2021_Rx" SG_ 1108 RCMSerialNoByte6 1;
BA_ "U_P702_MY2021_Rx" SG_ 1108 RCMSerialNoByte6 1;
BA_ "U_T6_MCA_MY2020_Rx" SG_ 1108 RCMSerialNoByte6 1;
BA_ "U_CD542_MY2021_Rx" SG_ 1108 RCMSerialNoByte6 1;
BA_ "U_U55X_MY2022_Rx" SG_ 1108 RCMSerialNoByte6 1;
BA_ "U_CD764_MY2022_Rx" SG_ 1108 RCMSerialNoByte6 1;
BA_ "U_CX727_MY2021_Rx" SG_ 1108 RCMSerialNoByte5 1;
BA_ "U_P702_MY2021_Rx" SG_ 1108 RCMSerialNoByte5 1;
BA_ "U_T6_MCA_MY2020_Rx" SG_ 1108 RCMSerialNoByte5 1;
BA_ "U_CD542_MY2021_Rx" SG_ 1108 RCMSerialNoByte5 1;
BA_ "U_U55X_MY2022_Rx" SG_ 1108 RCMSerialNoByte5 1;
BA_ "U_CD764_MY2022_Rx" SG_ 1108 RCMSerialNoByte5 1;
BA_ "U_CX727_MY2021_Rx" SG_ 1108 RCMSerialNoByte4 1;
BA_ "U_P702_MY2021_Rx" SG_ 1108 RCMSerialNoByte4 1;
BA_ "U_T6_MCA_MY2020_Rx" SG_ 1108 RCMSerialNoByte4 1;
BA_ "U_CD542_MY2021_Rx" SG_ 1108 RCMSerialNoByte4 1;
BA_ "U_U55X_MY2022_Rx" SG_ 1108 RCMSerialNoByte4 1;
BA_ "U_CD764_MY2022_Rx" SG_ 1108 RCMSerialNoByte4 1;
BA_ "U_CX727_MY2021_Rx" SG_ 1108 RCMSerialNoByte3 1;
BA_ "U_P702_MY2021_Rx" SG_ 1108 RCMSerialNoByte3 1;
BA_ "U_T6_MCA_MY2020_Rx" SG_ 1108 RCMSerialNoByte3 1;
BA_ "U_CD542_MY2021_Rx" SG_ 1108 RCMSerialNoByte3 1;
BA_ "U_U55X_MY2022_Rx" SG_ 1108 RCMSerialNoByte3 1;
BA_ "U_CD764_MY2022_Rx" SG_ 1108 RCMSerialNoByte3 1;
BA_ "U_CX727_MY2021_Rx" SG_ 1108 RCMSerialNoByte2 1;
BA_ "U_P702_MY2021_Rx" SG_ 1108 RCMSerialNoByte2 1;
BA_ "U_T6_MCA_MY2020_Rx" SG_ 1108 RCMSerialNoByte2 1;
BA_ "U_CD542_MY2021_Rx" SG_ 1108 RCMSerialNoByte2 1;
BA_ "U_U55X_MY2022_Rx" SG_ 1108 RCMSerialNoByte2 1;
BA_ "U_CD764_MY2022_Rx" SG_ 1108 RCMSerialNoByte2 1;
BA_ "U_CX727_MY2021_Rx" SG_ 1108 RCMSerialNoByte1 1;
BA_ "U_P702_MY2021_Rx" SG_ 1108 RCMSerialNoByte1 1;
BA_ "U_T6_MCA_MY2020_Rx" SG_ 1108 RCMSerialNoByte1 1;
BA_ "U_CD542_MY2021_Rx" SG_ 1108 RCMSerialNoByte1 1;
BA_ "U_U55X_MY2022_Rx" SG_ 1108 RCMSerialNoByte1 1;
BA_ "U_CD764_MY2022_Rx" SG_ 1108 RCMSerialNoByte1 1;
BA_ "GenSigStartValueInteger" SG_ 261 ChrgStatDsply_D_Rq 1;
BA_ "GenSigStartValue" SG_ 261 ChrgStatDsply_D_Rq 1;
BA_ "U_CX727_MY2021_Rx" SG_ 261 ModemReset_D_Rq 1;
BA_ "U_CD542_MY2021_Rx" SG_ 261 ModemReset_D_Rq 1;
BA_ "U_T6_MCA_MY2020_Rx" SG_ 261 StopStrtDrvMde_B_RqBtn3 1;
BA_ "U_CD542_MY2021_Rx" SG_ 261 StopStrtDrvMde_B_RqBtn3 1;
BA_ "U_CD764_MY2022_Rx" SG_ 261 StopStrtDrvMde_B_RqBtn3 1;
BA_ "U_CX727_MY2021_Rx" SG_ 261 FactoryReset_Rq 1;
BA_ "U_P702_MY2021_Rx" SG_ 261 FactoryReset_Rq 1;
BA_ "U_P702_MY2021_Rx" SG_ 1146 TrlrAidSwtch_D_RqDrv 1;
BA_ "U_T6_MCA_MY2020_Rx" SG_ 1146 TrlrAidSwtch_D_RqDrv 1;
BA_ "U_CD542_MY2021_Rx" SG_ 1146 TrlrAidSwtch_D_RqDrv 1;
BA_ "U_U55X_MY2022_Rx" SG_ 1146 TrlrAidSwtch_D_RqDrv 1;
BA_ "U_CD764_MY2022_Rx" SG_ 1146 TrlrAidSwtch_D_RqDrv 1;
BA_ "GenSigStartValueInteger" SG_ 1146 TrlrAidCtl_U_RqDrv 4094;
BA_ "GenSigStartValue" SG_ 1146 TrlrAidCtl_U_RqDrv 4093;
BA_ "U_P702_MY2021_Rx" SG_ 1146 TrlrAidCtl_U_RqDrv 1;
BA_ "U_T6_MCA_MY2020_Rx" SG_ 1146 TrlrAidCtl_U_RqDrv 1;
BA_ "U_U55X_MY2022_Rx" SG_ 1146 TrlrAidCtl_U_RqDrv 1;
BA_ "U_U55X_MY2022_Rx" SG_ 533 ClrExitAsstEnbl_D_RqMnu 1;
BA_ "U_P702_MY2021_Rx" SG_ 533 TrlrAidMde_D_Rq 1;
BA_ "U_T6_MCA_MY2020_Rx" SG_ 533 TrlrAidMde_D_Rq 1;
BA_ "U_U55X_MY2022_Rx" SG_ 533 TrlrAidMde_D_Rq 1;
BA_ "U_CX727_MY2021_Rx" SG_ 533 OnbChrgGoTTouch_D_Rq 1;
BA_ "U_P702_MY2021_Rx" SG_ 533 OnbChrgGoTTouch_D_Rq 1;
BA_ "U_CD542_MY2021_Rx" SG_ 533 OnbChrgGoTTouch_D_Rq 1;
BA_ "U_CX727_MY2021_Rx" SG_ 533 OnbChrgGoTPrcond_D_Rq 1;
BA_ "U_P702_MY2021_Rx" SG_ 533 OnbChrgGoTPrcond_D_Rq 1;
BA_ "U_CD542_MY2021_Rx" SG_ 533 OnbChrgGoTPrcond_D_Rq 1;
BA_ "GenSigStartValueInteger" SG_ 533 OnbChrgGoTOn_D_Rq 2;
BA_ "GenSigStartValue" SG_ 533 OnbChrgGoTOn_D_Rq 2;
BA_ "U_CX727_MY2021_Rx" SG_ 533 OnbChrgGoTOn_D_Rq 1;
BA_ "U_P702_MY2021_Rx" SG_ 533 OnbChrgGoTOn_D_Rq 1;
BA_ "U_CD542_MY2021_Rx" SG_ 533 OnbChrgGoTOn_D_Rq 1;
BA_ "U_CX727_MY2021_Rx" SG_ 533 OnbChrgGoTMnte_D_Rq 1;
BA_ "U_P702_MY2021_Rx" SG_ 533 OnbChrgGoTMnte_D_Rq 1;
BA_ "U_CD542_MY2021_Rx" SG_ 533 OnbChrgGoTMnte_D_Rq 1;
BA_ "GenSigStartValueInteger" SG_ 533 OnbChrgGoTHr_T_Rq 30;
BA_ "GenSigStartValue" SG_ 533 OnbChrgGoTHr_T_Rq 30;
BA_ "U_CX727_MY2021_Rx" SG_ 533 OnbChrgGoTHr_T_Rq 1;
BA_ "U_P702_MY2021_Rx" SG_ 533 OnbChrgGoTHr_T_Rq 1;
BA_ "U_CD542_MY2021_Rx" SG_ 533 OnbChrgGoTHr_T_Rq 1;
BA_ "U_CX727_MY2021_Rx" SG_ 533 OnbChrgGoTExtHtr_D_Rq 1;
BA_ "U_P702_MY2021_Rx" SG_ 533 OnbChrgGoTExtHtr_D_Rq 1;
BA_ "U_CD542_MY2021_Rx" SG_ 533 OnbChrgGoTExtHtr_D_Rq 1;
BA_ "U_CX727_MY2021_Rx" SG_ 533 OnbChrgGoTElement_D_Rq 1;
BA_ "U_P702_MY2021_Rx" SG_ 533 OnbChrgGoTElement_D_Rq 1;
BA_ "U_CD542_MY2021_Rx" SG_ 533 OnbChrgGoTElement_D_Rq 1;
BA_ "U_CX727_MY2021_Rx" SG_ 533 OnbChrgGoTDelete_B_Rq 1;
BA_ "U_P702_MY2021_Rx" SG_ 533 OnbChrgGoTDelete_B_Rq 1;
BA_ "U_CD542_MY2021_Rx" SG_ 533 OnbChrgGoTDelete_B_Rq 1;
BA_ "U_CX727_MY2021_Rx" SG_ 533 OnbChrgClearAll_B_Rq 1;
BA_ "U_P702_MY2021_Rx" SG_ 533 OnbChrgClearAll_B_Rq 1;
BA_ "U_CD542_MY2021_Rx" SG_ 533 OnbChrgClearAll_B_Rq 1;
BA_ "U_T6_MCA_MY2020_Rx" SG_ 533 AutoEpbZoomView_B_Stat 1;
BA_ "U_U55X_MY2022_Rx" SG_ 533 AutoEpbZoomView_B_Stat 1;
BA_ "U_T6_MCA_MY2020_Rx" SG_ 533 AutoEpbButtn_B_Stat 1;
BA_ "U_U55X_MY2022_Rx" SG_ 533 AutoEpbButtn_B_Stat 1;
BA_ "WakeupSignal" SG_ 533 LghtAmbDrvMde_D_Rq 1;
BA_ "U_CX727_MY2021_Rx" SG_ 533 OnbChrgGoTUpdate_B_Rq 1;
BA_ "U_CD542_MY2021_Rx" SG_ 533 OnbChrgGoTUpdate_B_Rq 1;
BA_ "U_T6_MCA_MY2020_Rx" SG_ 533 TrlrHitch_D_RqMnu 1;
BA_ "U_CD542_MY2021_Rx" SG_ 533 TrlrHitch_D_RqMnu 1;
BA_ "U_U55X_MY2022_Rx" SG_ 533 TrlrHitch_D_RqMnu 1;
BA_ "U_CD764_MY2022_Rx" SG_ 533 TrlrHitch_D_RqMnu 1;
BA_ "U_T6_MCA_MY2020_Rx" SG_ 778 PrkAidAcsyRear_D_RqDrv 1;
BA_ "U_CD542_MY2021_Rx" SG_ 778 PrkAidAcsyRear_D_RqDrv 1;
BA_ "U_U55X_MY2022_Rx" SG_ 778 PrkAidAcsyRear_D_RqDrv 1;
BA_ "U_CD764_MY2022_Rx" SG_ 778 PrkAidAcsyRear_D_RqDrv 1;
BA_ "U_T6_MCA_MY2020_Rx" SG_ 778 PrkAidAcsyFront_D_RqDrv 1;
BA_ "U_CD542_MY2021_Rx" SG_ 778 PrkAidAcsyFront_D_RqDrv 1;
BA_ "U_U55X_MY2022_Rx" SG_ 778 PrkAidAcsyFront_D_RqDrv 1;
BA_ "U_CD764_MY2022_Rx" SG_ 778 PrkAidAcsyFront_D_RqDrv 1;
BA_ "GenSigStartValueInteger" SG_ 778 Cta_D_Rq 1;
BA_ "GenSigStartValue" SG_ 778 Cta_D_Rq 1;
BA_ "U_T6_MCA_MY2020_Rx" SG_ 778 Cta_D_Rq 1;
BA_ "U_CD542_MY2021_Rx" SG_ 778 Cta_D_Rq 1;
BA_ "U_U55X_MY2022_Rx" SG_ 778 Cta_D_Rq 1;
BA_ "U_CD764_MY2022_Rx" SG_ 778 Cta_D_Rq 1;
BA_ "U_T6_MCA_MY2020_Rx" SG_ 778 PrkAidRear_D_RqDrv 1;
BA_ "U_CD542_MY2021_Rx" SG_ 778 PrkAidRear_D_RqDrv 1;
BA_ "U_U55X_MY2022_Rx" SG_ 778 PrkAidRear_D_RqDrv 1;
BA_ "U_CD764_MY2022_Rx" SG_ 778 PrkAidRear_D_RqDrv 1;
BA_ "U_T6_MCA_MY2020_Rx" SG_ 778 PrkAidFront_D_RqDrv 1;
BA_ "U_CD542_MY2021_Rx" SG_ 778 PrkAidFront_D_RqDrv 1;
BA_ "U_U55X_MY2022_Rx" SG_ 778 PrkAidFront_D_RqDrv 1;
BA_ "U_CD764_MY2022_Rx" SG_ 778 PrkAidFront_D_RqDrv 1;
BA_ "GenSigStartValueInteger" SG_ 778 Sod_D_Rq 2;
BA_ "GenSigStartValue" SG_ 778 Sod_D_Rq 2;
BA_ "U_T6_MCA_MY2020_Rx" SG_ 778 Sod_D_Rq 1;
BA_ "U_CD542_MY2021_Rx" SG_ 778 Sod_D_Rq 1;
BA_ "U_U55X_MY2022_Rx" SG_ 778 Sod_D_Rq 1;
BA_ "U_CD764_MY2022_Rx" SG_ 778 Sod_D_Rq 1;
BA_ "U_U55X_MY2022_Rx" SG_ 778 ClrExitAsstEnbl_D_RqDrv 1;
BA_ "U_CD764_MY2022_Rx" SG_ 778 ClrExitAsstEnbl_D_RqDrv 1;
BA_ "U_CX727_MY2021_Rx" SG_ 1041 ElCmprUHi_U_Actl 1;
BA_ "U_P702_MY2021_Rx" SG_ 1041 ElCmprUHi_U_Actl 1;
BA_ "U_CD542_MY2021_Rx" SG_ 1041 ElCmprUHi_U_Actl 1;
BA_ "U_CX727_MY2021_Rx" SG_ 1041 ElCmprUHi_D_Stat 1;
BA_ "U_P702_MY2021_Rx" SG_ 1041 ElCmprUHi_D_Stat 1;
BA_ "U_CD542_MY2021_Rx" SG_ 1041 ElCmprUHi_D_Stat 1;
BA_ "U_CX727_MY2021_Rx" SG_ 1041 ElCmprOverTe_D_Stat 1;
BA_ "U_P702_MY2021_Rx" SG_ 1041 ElCmprOverTe_D_Stat 1;
BA_ "U_CD542_MY2021_Rx" SG_ 1041 ElCmprOverTe_D_Stat 1;
BA_ "U_CX727_MY2021_Rx" SG_ 1041 ElCmpr_N_Actl 1;
BA_ "U_P702_MY2021_Rx" SG_ 1041 ElCmpr_N_Actl 1;
BA_ "U_CD542_MY2021_Rx" SG_ 1041 ElCmpr_N_Actl 1;
BA_ "U_CX727_MY2021_Rx" SG_ 1041 ElCmpr_Pw_Actl 1;
BA_ "U_P702_MY2021_Rx" SG_ 1041 ElCmpr_Pw_Actl 1;
BA_ "U_CD542_MY2021_Rx" SG_ 1041 ElCmpr_Pw_Actl 1;
BA_ "U_CX727_MY2021_Rx" SG_ 1041 ElCmpr_D_Stat 1;
BA_ "U_P702_MY2021_Rx" SG_ 1041 ElCmpr_D_Stat 1;
BA_ "U_CD542_MY2021_Rx" SG_ 1041 ElCmpr_D_Stat 1;
BA_ "U_CX727_MY2021_Rx" SG_ 1041 ElCmprPerfErr_D_Falt 1;
BA_ "U_P702_MY2021_Rx" SG_ 1041 ElCmprPerfErr_D_Falt 1;
BA_ "U_CD542_MY2021_Rx" SG_ 1041 ElCmprPerfErr_D_Falt 1;
BA_ "U_CX727_MY2021_Rx" SG_ 1041 ElCmprInnrErr_D_Falt 1;
BA_ "U_P702_MY2021_Rx" SG_ 1041 ElCmprInnrErr_D_Falt 1;
BA_ "U_CD542_MY2021_Rx" SG_ 1041 ElCmprInnrErr_D_Falt 1;
BA_ "U_CX727_MY2021_Rx" SG_ 1041 ElCmprLostComm_D_Falt 1;
BA_ "U_P702_MY2021_Rx" SG_ 1041 ElCmprLostComm_D_Falt 1;
BA_ "U_CD542_MY2021_Rx" SG_ 1041 ElCmprLostComm_D_Falt 1;
BA_ "U_CX727_MY2021_Rx" SG_ 1041 ElCmprOverLoad_D_Falt 1;
BA_ "U_P702_MY2021_Rx" SG_ 1041 ElCmprOverLoad_D_Falt 1;
BA_ "U_CD542_MY2021_Rx" SG_ 1041 ElCmprOverLoad_D_Falt 1;
BA_ "U_CX727_MY2021_Rx" SG_ 1041 ElCmprOverTe_D_Falt 1;
BA_ "U_P702_MY2021_Rx" SG_ 1041 ElCmprOverTe_D_Falt 1;
BA_ "U_CD542_MY2021_Rx" SG_ 1041 ElCmprOverTe_D_Falt 1;
BA_ "U_CX727_MY2021_Rx" SG_ 1041 ElCmprBattURng_D_Falt 1;
BA_ "U_P702_MY2021_Rx" SG_ 1041 ElCmprBattURng_D_Falt 1;
BA_ "U_CD542_MY2021_Rx" SG_ 1041 ElCmprBattURng_D_Falt 1;
BA_ "U_CX727_MY2021_Rx" SG_ 1041 ElCmprBattSysU_D_Falt 1;
BA_ "U_P702_MY2021_Rx" SG_ 1041 ElCmprBattSysU_D_Falt 1;
BA_ "U_CD542_MY2021_Rx" SG_ 1041 ElCmprBattSysU_D_Falt 1;
BA_ "U_CX727_MY2021_Rx" SG_ 1041 ElCmprSysU_D_Falt 1;
BA_ "U_P702_MY2021_Rx" SG_ 1041 ElCmprSysU_D_Falt 1;
BA_ "U_CD542_MY2021_Rx" SG_ 1041 ElCmprSysU_D_Falt 1;
BA_ "GenSigStartValue" SG_ 1067 BattULoAux_U_Rq 3296;
BA_ "U_P702_MY2021_Rx" SG_ 1067 BattULoAux_U_Rq 1;
BA_ "GenSigStartValueInteger" SG_ 1067 BattULoAuxIsol_D_Rq 2;
BA_ "GenSigStartValue" SG_ 1067 BattULoAuxIsol_D_Rq 2;
BA_ "U_P702_MY2021_Rx" SG_ 1067 BattULoAuxIsol_D_Rq 1;
BA_ "GenSigStartValueInteger" SG_ 1067 BattULoAuxSoc_Pc_Actl 95;
BA_ "GenSigStartValue" SG_ 1067 BattULoAuxSoc_Pc_Actl 95;
BA_ "U_P702_MY2021_Rx" SG_ 1067 BattULoAuxSoc_Pc_Actl 1;
BA_ "GenSigStartValueInteger" SG_ 1067 BattULoAux_I_Actl 2048;
BA_ "U_P702_MY2021_Rx" SG_ 1067 BattULoAux_I_Actl 1;
BA_ "U_P702_MY2021_Rx" SG_ 1067 BattULoAux_D_Qlty 1;
BA_ "U_P702_MY2021_Rx" SG_ 1067 BattULoCrnkStrt_U_Pred 1;
BA_ "U_P702_MY2021_Rx" SG_ 1067 BattULoCrnkBelt_U_Pred 1;
BA_ "GenSigStartValueInteger" SG_ 1067 BattULoAux_U_Actl 203;
BA_ "GenSigStartValue" SG_ 1067 BattULoAux_U_Actl 203;
BA_ "U_P702_MY2021_Rx" SG_ 1067 BattULoAux_U_Actl 1;
BA_ "U_P702_MY2021_Rx" SG_ 1067 BattULoAux_B_Falt 1;
BA_ "U_CX727_MY2021_Rx" SG_ 1118 ExtChrgNowButtn_B_Rq 1;
BA_ "U_CD542_MY2021_Rx" SG_ 1118 ExtChrgNowButtn_B_Rq 1;
BA_ "U_CX727_MY2021_Rx" SG_ 1118 CoolFanChrgr_D_Rq 1;
BA_ "U_CD542_MY2021_Rx" SG_ 1118 CoolFanChrgr_D_Rq 1;
BA_ "U_CX727_MY2021_Rx" SG_ 1118 ChrgrClntFlw_D_Rq 1;
BA_ "U_CD542_MY2021_Rx" SG_ 1118 ChrgrClntFlw_D_Rq 1;
BA_ "U_CX727_MY2021_Rx" SG_ 1118 PlgStatEvnt_B_Stat 1;
BA_ "U_CD542_MY2021_Rx" SG_ 1118 PlgStatEvnt_B_Stat 1;
BA_ "U_CX727_MY2021_Rx" SG_ 1118 ChrgrCnnctPwr_B_Stat 1;
BA_ "U_CD542_MY2021_Rx" SG_ 1118 ChrgrCnnctPwr_B_Stat 1;
BA_ "U_CX727_MY2021_Rx" SG_ 1118 ChrgrAvailEvnt_B_Stat 1;
BA_ "U_CD542_MY2021_Rx" SG_ 1118 ChrgrAvailEvnt_B_Stat 1;
BA_ "U_CX727_MY2021_Rx" SG_ 1118 ChrgChngEvnt_B_Stat 1;
BA_ "U_CD542_MY2021_Rx" SG_ 1118 ChrgChngEvnt_B_Stat 1;
BA_ "U_CX727_MY2021_Rx" SG_ 1118 ChrgCordLck_D_Stat 1;
BA_ "U_CD542_MY2021_Rx" SG_ 1118 ChrgCordLck_D_Stat 1;
BA_ "U_CX727_MY2021_Rx" SG_ 1118 ChrgrInPwMde_D_Actl 1;
BA_ "U_CD542_MY2021_Rx" SG_ 1118 ChrgrInPwMde_D_Actl 1;
BA_ "GenSigStartValueInteger" SG_ 1118 ChrgrPncEnbl_D_Stat 3;
BA_ "GenSigStartValue" SG_ 1118 ChrgrPncEnbl_D_Stat 3;
BA_ "U_CDX706_MY2023_Tx" SG_ 1040 VehSimSnd_Pc_Rq 1;
BA_ "GenSigStartValue" SG_ 1040 VehSimSnd_Pc_Rq 511;
BA_ "U_CDX706_MY2023_Rx" SG_ 1040 RoadGrd_Pc_Est 1;
BA_ "ECGUsedRxSignal" SG_ 1040 RoadGrd_Pc_Est 1;
BA_ "GenSigStartValue" SG_ 1040 RoadGrd_Pc_Est 1023;
BA_ "GenSigStartValueInteger" SG_ 1040 BattTrac_I2_EstVsc 15000;
BA_ "GenSigStartValue" SG_ 1040 BattTrac_I2_EstVsc 262142;
BA_ "U_CX727_MY2021_Rx" SG_ 1040 ElCmprEnbl_B_Rq 1;
BA_ "U_P702_MY2021_Rx" SG_ 1040 ElCmprEnbl_B_Rq 1;
BA_ "U_CD542_MY2021_Rx" SG_ 1040 ElCmprEnbl_B_Rq 1;
BA_ "U_CX727_MY2021_Tx" SG_ 1040 ElCmprEnbl_B_Rq 1;
BA_ "U_P702_MY2021_Tx" SG_ 1040 ElCmprEnbl_B_Rq 1;
BA_ "U_CD542_MY2021_Tx" SG_ 1040 ElCmprEnbl_B_Rq 1;
BA_ "U_CX727_MY2021_Tx" SG_ 1040 ElCmpr_N_Rq 1;
BA_ "U_P702_MY2021_Tx" SG_ 1040 ElCmpr_N_Rq 1;
BA_ "U_CD542_MY2021_Tx" SG_ 1040 ElCmpr_N_Rq 1;
BA_ "U_CDX706_MY2023_Tx" SG_ 1144 BattTracCool_B_Actl 1;
BA_ "GenSigSendType" SG_ 1144 BattTracCool_B_Actl 3;
BA_ "GenSigStartValue" SG_ 1144 BattChrgInhbt_D2_Rq 1;
BA_ "GenSigSendType" SG_ 1144 BattChrgInhbt_D2_Rq 3;
BA_ "GenSigSendType" SG_ 1144 AwdLckMde_D_Stat 3;
BA_ "GenSigSendType" SG_ 1144 ULoBattTrnsfrSustn_B_Rq 3;
BA_ "ECGUsedRxSignal" SG_ 1144 ULoBattTrnsfrSustn_B_Rq 1;
BA_ "U_CD542_MY2021_Rx" SG_ 1144 ULoBattTrnsfrSustn_B_Rq 1;
BA_ "U_U55X_MY2022_Rx" SG_ 1144 ULoBattTrnsfrSustn_B_Rq 1;
BA_ "U_CD542_MY2021_Tx" SG_ 1144 ULoBattTrnsfrSustn_B_Rq 1;
BA_ "GenSigSendType" SG_ 1144 ULoBattTransfer_D_Stat 3;
BA_ "ECGUsedRxSignal" SG_ 1144 ULoBattTransfer_D_Stat 1;
BA_ "U_CD542_MY2021_Rx" SG_ 1144 ULoBattTransfer_D_Stat 1;
BA_ "U_U55X_MY2022_Rx" SG_ 1144 ULoBattTransfer_D_Stat 1;
BA_ "U_CD542_MY2021_Tx" SG_ 1144 ULoBattTransfer_D_Stat 1;
BA_ "U_CX727_MY2021_Tx" SG_ 1144 BattChrgTrgtSoC_D_Rq 1;
BA_ "U_P702_MY2021_Tx" SG_ 1144 BattChrgTrgtSoC_D_Rq 1;
BA_ "U_CD542_MY2021_Tx" SG_ 1144 BattChrgTrgtSoC_D_Rq 1;
BA_ "GenSigSendType" SG_ 1144 CabnEvapSovFront_B_Rq 3;
BA_ "WakeupSignal" SG_ 1144 CabnEvapSovFront_B_Rq 1;
BA_ "U_CX727_MY2021_Tx" SG_ 1144 CabnEvapSovFront_B_Rq 1;
BA_ "U_P702_MY2021_Tx" SG_ 1144 CabnEvapSovFront_B_Rq 1;
BA_ "U_CD542_MY2021_Tx" SG_ 1144 CabnEvapSovFront_B_Rq 1;
BA_ "GenSigSendType" SG_ 1144 HeatCoreSovRear_B_Rq 3;
BA_ "WakeupSignal" SG_ 1144 HeatCoreSovRear_B_Rq 1;
BA_ "U_CX727_MY2021_Tx" SG_ 1144 HeatCoreSovRear_B_Rq 1;
BA_ "U_P702_MY2021_Tx" SG_ 1144 HeatCoreSovRear_B_Rq 1;
BA_ "U_CD542_MY2021_Tx" SG_ 1144 HeatCoreSovRear_B_Rq 1;
BA_ "GenSigSendType" SG_ 1144 BattChlrSov_B_Rq 3;
BA_ "WakeupSignal" SG_ 1144 BattChlrSov_B_Rq 1;
BA_ "U_CX727_MY2021_Tx" SG_ 1144 BattChlrSov_B_Rq 1;
BA_ "U_P702_MY2021_Tx" SG_ 1144 BattChlrSov_B_Rq 1;
BA_ "U_CD542_MY2021_Tx" SG_ 1144 BattChlrSov_B_Rq 1;
BA_ "GenSigSendType" SG_ 1144 CabnEvapSovRear_B_Rq 3;
BA_ "WakeupSignal" SG_ 1144 CabnEvapSovRear_B_Rq 1;
BA_ "U_CX727_MY2021_Tx" SG_ 1144 CabnEvapSovRear_B_Rq 1;
BA_ "U_P702_MY2021_Tx" SG_ 1144 CabnEvapSovRear_B_Rq 1;
BA_ "U_CD542_MY2021_Tx" SG_ 1144 CabnEvapSovRear_B_Rq 1;
BA_ "GenSigSendType" SG_ 1144 BrkAppl_D_RqPt 3;
BA_ "U_CX727_MY2021_Rx" SG_ 1144 BrkAppl_D_RqPt 1;
BA_ "U_CD542_MY2021_Rx" SG_ 1144 BrkAppl_D_RqPt 1;
BA_ "U_CD764_MY2022_Rx" SG_ 1144 BrkAppl_D_RqPt 1;
BA_ "U_CX727_MY2021_Tx" SG_ 1144 BrkAppl_D_RqPt 1;
BA_ "U_P702_MY2021_Tx" SG_ 1144 BrkAppl_D_RqPt 1;
BA_ "U_CD542_MY2021_Tx" SG_ 1144 BrkAppl_D_RqPt 1;
BA_ "GenSigSendType" SG_ 1144 BattClntVlvOvrrd_D_Rq 3;
BA_ "U_CX727_MY2021_Tx" SG_ 1144 BattClntVlvOvrrd_D_Rq 1;
BA_ "U_CD542_MY2021_Tx" SG_ 1144 BattClntVlvOvrrd_D_Rq 1;
BA_ "GenSigSendType" SG_ 1144 BattTracChillerOn_B_Rq 3;
BA_ "U_CX727_MY2021_Tx" SG_ 1144 BattTracChillerOn_B_Rq 1;
BA_ "U_CD542_MY2021_Tx" SG_ 1144 BattTracChillerOn_B_Rq 1;
BA_ "GenSigSendType" SG_ 1144 BattTracChiller_D_Stat 3;
BA_ "U_CX727_MY2021_Tx" SG_ 1144 BattTracChiller_D_Stat 1;
BA_ "U_CD542_MY2021_Tx" SG_ 1144 BattTracChiller_D_Stat 1;
BA_ "GenSigSendType" SG_ 1144 HtrnDcdcDis_B_Rq 3;
BA_ "U_CX727_MY2021_Rx" SG_ 1144 HtrnDcdcDis_B_Rq 1;
BA_ "U_CD542_MY2021_Rx" SG_ 1144 HtrnDcdcDis_B_Rq 1;
BA_ "U_CX727_MY2021_Tx" SG_ 1144 HtrnDcdcDis_B_Rq 1;
BA_ "U_CD542_MY2021_Tx" SG_ 1144 HtrnDcdcDis_B_Rq 1;
BA_ "GenSigSendType" SG_ 1144 HtrnCnnctPwr_B_Stat 3;
BA_ "U_CX727_MY2021_Tx" SG_ 1144 HtrnCnnctPwr_B_Stat 1;
BA_ "U_P702_MY2021_Tx" SG_ 1144 HtrnCnnctPwr_B_Stat 1;
BA_ "U_CD542_MY2021_Tx" SG_ 1144 HtrnCnnctPwr_B_Stat 1;
BA_ "GenSigSendType" SG_ 1144 PtcHtr_D_Stat 3;
BA_ "U_CX727_MY2021_Rx" SG_ 1144 PtcHtr_D_Stat 1;
BA_ "U_P702_MY2021_Rx" SG_ 1144 PtcHtr_D_Stat 1;
BA_ "U_CD542_MY2021_Rx" SG_ 1144 PtcHtr_D_Stat 1;
BA_ "U_CX727_MY2021_Tx" SG_ 1144 PtcHtr_D_Stat 1;
BA_ "U_P702_MY2021_Tx" SG_ 1144 PtcHtr_D_Stat 1;
BA_ "U_CD542_MY2021_Tx" SG_ 1144 PtcHtr_D_Stat 1;
BA_ "GenSigSendType" SG_ 1144 WakeAlarm0_B_Typ 3;
BA_ "U_CX727_MY2021_Tx" SG_ 1144 WakeAlarm0_B_Typ 1;
BA_ "U_CD542_MY2021_Tx" SG_ 1144 WakeAlarm0_B_Typ 1;
BA_ "GenSigStartValueInteger" SG_ 1144 WakeAlarm0_T_Rq 32767;
BA_ "GenSigStartValue" SG_ 1144 WakeAlarm0_T_Rq 32767;
BA_ "U_CX727_MY2021_Tx" SG_ 1144 WakeAlarm0_T_Rq 1;
BA_ "U_CD542_MY2021_Tx" SG_ 1144 WakeAlarm0_T_Rq 1;
BA_ "GenSigSendType" SG_ 1144 HtrnClntFlw_D_Rq 3;
BA_ "U_CX727_MY2021_Tx" SG_ 1144 HtrnClntFlw_D_Rq 1;
BA_ "U_P702_MY2021_Tx" SG_ 1144 HtrnClntFlw_D_Rq 1;
BA_ "U_CD542_MY2021_Tx" SG_ 1144 HtrnClntFlw_D_Rq 1;
BA_ "GenSigSendType" SG_ 1144 BattTracDrvSustn_B_Rq 3;
BA_ "U_CX727_MY2021_Rx" SG_ 1144 BattTracDrvSustn_B_Rq 1;
BA_ "U_CD542_MY2021_Rx" SG_ 1144 BattTracDrvSustn_B_Rq 1;
BA_ "U_CX727_MY2021_Tx" SG_ 1144 BattTracDrvSustn_B_Rq 1;
BA_ "U_P702_MY2021_Tx" SG_ 1144 BattTracDrvSustn_B_Rq 1;
BA_ "U_CD542_MY2021_Tx" SG_ 1144 BattTracDrvSustn_B_Rq 1;
BA_ "GenSigSendType" SG_ 1144 CabinDrvSustn_B_Rq 3;
BA_ "U_CX727_MY2021_Rx" SG_ 1144 CabinDrvSustn_B_Rq 1;
BA_ "U_CD542_MY2021_Rx" SG_ 1144 CabinDrvSustn_B_Rq 1;
BA_ "U_CX727_MY2021_Tx" SG_ 1144 CabinDrvSustn_B_Rq 1;
BA_ "U_CD542_MY2021_Tx" SG_ 1144 CabinDrvSustn_B_Rq 1;
BA_ "GenSigSendType" SG_ 1144 ChrgNowEvnt_B_Stat 3;
BA_ "U_CX727_MY2021_Tx" SG_ 1144 ChrgNowEvnt_B_Stat 1;
BA_ "U_CD542_MY2021_Tx" SG_ 1144 ChrgNowEvnt_B_Stat 1;
BA_ "GenSigSendType" SG_ 1144 PreCondBatt_B_Actl 3;
BA_ "U_CX727_MY2021_Tx" SG_ 1144 PreCondBatt_B_Actl 1;
BA_ "U_CD542_MY2021_Tx" SG_ 1144 PreCondBatt_B_Actl 1;
BA_ "GenSigSendType" SG_ 1144 BattTracClntVlv_B_Rq 3;
BA_ "U_CX727_MY2021_Tx" SG_ 1144 BattTracClntVlv_B_Rq 1;
BA_ "U_P702_MY2021_Tx" SG_ 1144 BattTracClntVlv_B_Rq 1;
BA_ "U_CD542_MY2021_Tx" SG_ 1144 BattTracClntVlv_B_Rq 1;
BA_ "U_CX727_MY2021_Rx" SG_ 1112 BattTrac2_E_Avail 1;
BA_ "U_CD542_MY2021_Rx" SG_ 1112 BattTrac2_E_Avail 1;
BA_ "U_CX727_MY2021_Rx" SG_ 1112 BattTracCnnct_D_Cmd 1;
BA_ "U_P702_MY2021_Rx" SG_ 1112 BattTracCnnct_D_Cmd 1;
BA_ "U_CD542_MY2021_Rx" SG_ 1112 BattTracCnnct_D_Cmd 1;
BA_ "U_CX727_MY2021_Rx" SG_ 1112 BattTracHvilOpen_B_Stat 1;
BA_ "U_P702_MY2021_Rx" SG_ 1112 BattTracHvilOpen_B_Stat 1;
BA_ "U_CD542_MY2021_Rx" SG_ 1112 BattTracHvilOpen_B_Stat 1;
BA_ "U_CX727_MY2021_Rx" SG_ 1112 BattTracTeSustn_B_Rq 1;
BA_ "U_CX727_MY2021_Rx" SG_ 1112 BattTracTeEvnt_B_Stat 1;
BA_ "U_CD542_MY2021_Rx" SG_ 1112 BattTracTeEvnt_B_Stat 1;
BA_ "U_CX727_MY2021_Rx" SG_ 1112 BattTracDcdcDis_B_Rq 1;
BA_ "U_P702_MY2021_Rx" SG_ 1112 BattTracDcdcDis_B_Rq 1;
BA_ "U_CD542_MY2021_Rx" SG_ 1112 BattTracDcdcDis_B_Rq 1;
BA_ "U_CX727_MY2021_Rx" SG_ 1112 BattChrgTrgtEvnt_B_Stat 1;
BA_ "U_CD542_MY2021_Rx" SG_ 1112 BattChrgTrgtEvnt_B_Stat 1;
BA_ "U_CX727_MY2021_Rx" SG_ 1112 BattTracChrgSustn_B_Rq 1;
BA_ "U_CD542_MY2021_Rx" SG_ 1112 BattTracChrgSustn_B_Rq 1;
BA_ "U_CX727_MY2021_Rx" SG_ 1112 HtrnClntPump_D_Stat 1;
BA_ "U_P702_MY2021_Rx" SG_ 1112 HtrnClntPump_D_Stat 1;
BA_ "U_CD542_MY2021_Rx" SG_ 1112 HtrnClntPump_D_Stat 1;
BA_ "GenSigStartValueInteger" SG_ 1112 BattTrac2_E_Max 4094;
BA_ "GenSigStartValue" SG_ 1112 BattTrac2_E_Max 4094;
BA_ "U_CX727_MY2021_Rx" SG_ 1112 BattTrac2_E_Max 1;
BA_ "U_CX727_MY2021_Rx" SG_ 1112 BattTracDcFstSustn_B_Rq 1;
BA_ "U_CD542_MY2021_Rx" SG_ 1112 BattTracDiagClr_B_Rq 1;
BA_ "GenSigStartValueInteger" SG_ 1112 BattTracDelta_Te_Actl 164;
BA_ "GenSigStartValue" SG_ 1112 BattTracDelta_Te_Actl 254;
BA_ "U_CX727_MY2021_Rx" SG_ 1112 BattTracDelta_Te_Actl 1;
BA_ "U_P702_MY2021_Rx" SG_ 1112 BattTracDelta_Te_Actl 1;
BA_ "U_CD542_MY2021_Rx" SG_ 1112 BattTracDelta_Te_Actl 1;
BA_ "ContentDependant" SG_ 1112 BattTracClntPmp_D_Stat 1;
BA_ "U_CX727_MY2021_Rx" SG_ 1112 BattTracClntPmp_D_Stat 1;
BA_ "U_P702_MY2021_Rx" SG_ 1112 BattTracClntPmp_D_Stat 1;
BA_ "U_CD542_MY2021_Rx" SG_ 1112 BattTracClntPmp_D_Stat 1;
BA_ "U_P702_MY2021_Rx" SG_ 139 ActvFrontSteLck_D_Stat 1;
BA_ "U_T6_MCA_MY2020_Rx" SG_ 139 ActvFrontSteLck_D_Stat 1;
BA_ "U_P702_MY2021_Rx" SG_ 139 SelDrvMdeAdptSte_D_Stat 1;
BA_ "U_U55X_MY2022_Rx" SG_ 139 SelDrvMdeAdptSte_D_Stat 1;
BA_ "U_P702_MY2021_Rx" SG_ 139 AfsPw_B_Rq 1;
BA_ "U_T6_MCA_MY2020_Rx" SG_ 139 AfsPw_B_Rq 1;
BA_ "GenSigStartValue" SG_ 1121 OffRdSwtch_D_RqMnu 2;
BA_ "U_CX727_MY2021_Rx" SG_ 1121 SelDrvMdeSwtchOk_D_Stat 1;
BA_ "U_CX727_MY2021_Rx" SG_ 1121 AutoHoldSwtch_D_Stat2 1;
BA_ "U_T6_MCA_MY2020_Rx" SG_ 1121 AutoHoldSwtch_D_Stat2 1;
BA_ "U_U55X_MY2022_Rx" SG_ 1121 AutoHoldSwtch_D_Stat2 1;
BA_ "U_T6_MCA_MY2020_Rx" SG_ 1121 StopStrtDrvMde_B_RqBtn2 1;
BA_ "U_CX727_MY2021_Rx" SG_ 1121 SelDrvMdeSwtch_No_Actl 1;
BA_ "U_P702_MY2021_Rx" SG_ 1121 SelDrvMdeSwtch_No_Actl 1;
BA_ "U_T6_MCA_MY2020_Rx" SG_ 1121 SelDrvMdeSwtch_No_Actl 1;
BA_ "U_U55X_MY2022_Rx" SG_ 1121 SelDrvMdeSwtch_No_Actl 1;
BA_ "U_CX727_MY2021_Rx" SG_ 1121 SelDrvMdeSwtch_D_Stat 1;
BA_ "U_P702_MY2021_Rx" SG_ 1121 SelDrvMdeSwtch_D_Stat 1;
BA_ "U_T6_MCA_MY2020_Rx" SG_ 1121 SelDrvMdeSwtch_D_Stat 1;
BA_ "U_U55X_MY2022_Rx" SG_ 1121 SelDrvMdeSwtch_D_Stat 1;
BA_ "U_CX727_MY2021_Rx" SG_ 1121 SelDrvMdeCnt_D_Stat 1;
BA_ "U_P702_MY2021_Rx" SG_ 1121 SelDrvMdeCnt_D_Stat 1;
BA_ "U_T6_MCA_MY2020_Rx" SG_ 1121 SelDrvMdeCnt_D_Stat 1;
BA_ "U_U55X_MY2022_Rx" SG_ 1121 SelDrvMdeCnt_D_Stat 1;
BA_ "U_T6_MCA_MY2020_Rx" SG_ 1120 StabBarCnncButtn_D_Stat 1;
BA_ "U_P702_MY2021_Rx" SG_ 1120 DrvSlipCtlMde_B_Rq3 1;
BA_ "U_T6_MCA_MY2020_Rx" SG_ 1120 DrvSlipCtlMde_B_Rq3 1;
BA_ "U_U55X_MY2022_Rx" SG_ 1120 DrvSlipCtlMde_B_Rq3 1;
BA_ "U_P702_MY2021_Rx" SG_ 1120 HybMdeSwtch_B_Rq 1;
BA_ "GenSigStartValueInteger" SG_ 1120 AwdLck_D_RqDrv 2;
BA_ "GenSigStartValue" SG_ 1120 AwdLck_D_RqDrv 2;
BA_ "U_T6_MCA_MY2020_Rx" SG_ 1120 TrailCtlSwtch_B_Stat3 1;
BA_ "GenSigStartValueInteger" SG_ 1120 RearDiffLck_D_RqDrv 2;
BA_ "GenSigStartValue" SG_ 1120 RearDiffLck_D_RqDrv 2;
BA_ "U_P702_MY2021_Rx" SG_ 1120 RearDiffLck_D_RqDrv 1;
BA_ "U_T6_MCA_MY2020_Rx" SG_ 1120 RearDiffLck_D_RqDrv 1;
BA_ "U_U55X_MY2022_Rx" SG_ 1120 RearDiffLck_D_RqDrv 1;
BA_ "GenSigStartValueInteger" SG_ 1120 AwdMde_D_RqDrv 5;
BA_ "GenSigStartValue" SG_ 1120 AwdMde_D_RqDrv 5;
BA_ "U_P702_MY2021_Rx" SG_ 1120 AwdMde_D_RqDrv 1;
BA_ "U_T6_MCA_MY2020_Rx" SG_ 1120 AwdMde_D_RqDrv 1;
BA_ "U_U55X_MY2022_Rx" SG_ 1120 AwdMde_D_RqDrv 1;
BA_ "U_P702_MY2021_Rx" SG_ 1120 HdcSwtchPos_B_Actl 1;
BA_ "U_T6_MCA_MY2020_Rx" SG_ 1120 HdcSwtchPos_B_Actl 1;
BA_ "U_U55X_MY2022_Rx" SG_ 1120 HdcSwtchPos_B_Actl 1;
BA_ "GenSigStartValueInteger" SG_ 1120 FrontDiffLck_D_RqDrv 2;
BA_ "GenSigStartValue" SG_ 1120 FrontDiffLck_D_RqDrv 2;
BA_ "U_T6_MCA_MY2020_Rx" SG_ 1120 FrontDiffLck_D_RqDrv 1;
BA_ "U_CX727_MY2021_Rx" SG_ 1050 TrailCtlSwtch_B_Stat 1;
BA_ "U_CX727_MY2021_Rx" SG_ 1050 AutoHoldSwtch_D_Stat 1;
BA_ "U_P702_MY2021_Rx" SG_ 1050 AutoHoldSwtch_D_Stat 1;
BA_ "U_CD542_MY2021_Rx" SG_ 1050 AutoHoldSwtch_D_Stat 1;
BA_ "U_U55X_MY2022_Rx" SG_ 1050 AutoHoldSwtch_D_Stat 1;
BA_ "U_CD764_MY2022_Rx" SG_ 1050 AutoHoldSwtch_D_Stat 1;
BA_ "WakeupSignal" SG_ 1050 GlvBoxRleas_No_Actl 1;
BA_ "U_CX727_MY2021_Rx" SG_ 1050 DrvSlipCtlMde_B_Rq 1;
BA_ "U_T6_MCA_MY2020_Rx" SG_ 1050 DrvSlipCtlMde_B_Rq 1;
BA_ "U_U55X_MY2022_Rx" SG_ 1050 DrvSlipCtlMde_B_Rq 1;
BA_ "GenSigStartValueInteger" SG_ 1050 Outside_Air_Temp_Stat 254;
BA_ "GenSigStartValue" SG_ 1050 Outside_Air_Temp_Stat 254;
BA_ "U_CX727_MY2021_Rx" SG_ 1050 Outside_Air_Temp_Stat 1;
BA_ "U_P702_MY2021_Rx" SG_ 1050 Outside_Air_Temp_Stat 1;
BA_ "U_T6_MCA_MY2020_Rx" SG_ 1050 Outside_Air_Temp_Stat 1;
BA_ "U_CD542_MY2021_Rx" SG_ 1050 Outside_Air_Temp_Stat 1;
BA_ "U_U55X_MY2022_Rx" SG_ 1050 Outside_Air_Temp_Stat 1;
BA_ "U_CD764_MY2022_Rx" SG_ 1050 Outside_Air_Temp_Stat 1;
BA_ "U_U55X_MY2022_Rx" SG_ 621 RmtCtlSelSlot_D_Rq 1;
BA_ "U_U55X_MY2022_Rx" SG_ 621 RmtCtlSelPrkMde_D_Rq 1;
BA_ "U_U55X_MY2022_Rx" SG_ 621 RmtCtlSelMoveDir_D_Rq 1;
BA_ "U_U55X_MY2022_Rx" SG_ 621 RmtCtlRjctAutoCfg_B_Rq 1;
BA_ "U_T6_MCA_MY2020_Rx" SG_ 1124 GPS_Vdop 1;
BA_ "U_CX727_MY2021_Rx" SG_ 1124 GPS_Sat_num_in_view 1;
BA_ "U_P702_MY2021_Rx" SG_ 1124 GPS_Sat_num_in_view 1;
BA_ "U_CD542_MY2021_Rx" SG_ 1124 GPS_Sat_num_in_view 1;
BA_ "U_T6_MCA_MY2020_Rx" SG_ 1124 GPS_Heading 1;
BA_ "U_CD542_MY2021_Rx" SG_ 1124 GPS_Heading 1;
BA_ "U_CD764_MY2022_Rx" SG_ 1124 GPS_Heading 1;
BA_ "U_T6_MCA_MY2020_Rx" SG_ 1124 GPS_Hdop 1;
BA_ "U_CX727_MY2021_Rx" SG_ 1124 GPS_dimension 1;
BA_ "U_P702_MY2021_Rx" SG_ 1124 GPS_dimension 1;
BA_ "U_CD542_MY2021_Rx" SG_ 1124 GPS_dimension 1;
BA_ "GenSigStartValueInteger" SG_ 1137 RngPerChrgLbl_L_Dsply 4094;
BA_ "GenSigStartValue" SG_ 1137 RngPerChrgLbl_L_Dsply 4093;
BA_ "U_CX727_MY2021_Tx" SG_ 1137 RngPerChrgLbl_L_Dsply 1;
BA_ "U_CD542_MY2021_Tx" SG_ 1137 RngPerChrgLbl_L_Dsply 1;
BA_ "GenSigStartValueInteger" SG_ 1137 RngPerChrgAvg_L_Dsply 4094;
BA_ "GenSigStartValue" SG_ 1137 RngPerChrgAvg_L_Dsply 4093;
BA_ "U_CX727_MY2021_Tx" SG_ 1137 RngPerChrgAvg_L_Dsply 1;
BA_ "U_P702_MY2021_Tx" SG_ 1137 RngPerChrgAvg_L_Dsply 1;
BA_ "U_CD542_MY2021_Tx" SG_ 1137 RngPerChrgAvg_L_Dsply 1;
BA_ "GenSigStartValueInteger" SG_ 1137 RngImpctTot_Pc_Dsply 1023;
BA_ "GenSigStartValue" SG_ 1137 RngImpctTot_Pc_Dsply 1022;
BA_ "U_CX727_MY2021_Tx" SG_ 1137 RngImpctTot_Pc_Dsply 1;
BA_ "U_CD542_MY2021_Tx" SG_ 1137 RngImpctTot_Pc_Dsply 1;
BA_ "GenSigStartValueInteger" SG_ 1137 RngImpctExt_Pc_Dsply 1023;
BA_ "GenSigStartValue" SG_ 1137 RngImpctExt_Pc_Dsply 1022;
BA_ "U_CX727_MY2021_Tx" SG_ 1137 RngImpctExt_Pc_Dsply 1;
BA_ "U_CD542_MY2021_Tx" SG_ 1137 RngImpctExt_Pc_Dsply 1;
BA_ "GenSigStartValueInteger" SG_ 1137 RngImpctDrv_Pc_Dsply 1023;
BA_ "GenSigStartValue" SG_ 1137 RngImpctDrv_Pc_Dsply 1022;
BA_ "U_CX727_MY2021_Tx" SG_ 1137 RngImpctDrv_Pc_Dsply 1;
BA_ "U_CD542_MY2021_Tx" SG_ 1137 RngImpctDrv_Pc_Dsply 1;
BA_ "GenSigStartValueInteger" SG_ 1137 RngImpctClim_Pc_Dsply 1023;
BA_ "GenSigStartValue" SG_ 1137 RngImpctClim_Pc_Dsply 1022;
BA_ "U_CX727_MY2021_Tx" SG_ 1137 RngImpctClim_Pc_Dsply 1;
BA_ "U_CD542_MY2021_Tx" SG_ 1137 RngImpctClim_Pc_Dsply 1;
BA_ "U_T6_MCA_MY2020_Tx" SG_ 1255 BalrRight4Threat_D_Stat 1;
BA_ "U_CD542_MY2021_Tx" SG_ 1255 BalrRight4Threat_D_Stat 1;
BA_ "U_U55X_MY2022_Tx" SG_ 1255 BalrRight4Threat_D_Stat 1;
BA_ "U_CD764_MY2022_Tx" SG_ 1255 BalrRight4Threat_D_Stat 1;
BA_ "GenSigStartValueInteger" SG_ 1255 BalrRight4Prev3Y_L_Actl 64;
BA_ "U_T6_MCA_MY2020_Tx" SG_ 1255 BalrRight4Prev3Y_L_Actl 1;
BA_ "U_CD542_MY2021_Tx" SG_ 1255 BalrRight4Prev3Y_L_Actl 1;
BA_ "U_U55X_MY2022_Tx" SG_ 1255 BalrRight4Prev3Y_L_Actl 1;
BA_ "U_CD764_MY2022_Tx" SG_ 1255 BalrRight4Prev3Y_L_Actl 1;
BA_ "GenSigStartValueInteger" SG_ 1255 BalrRight4Prev3X_L_Actl 64;
BA_ "U_T6_MCA_MY2020_Tx" SG_ 1255 BalrRight4Prev3X_L_Actl 1;
BA_ "U_CD542_MY2021_Tx" SG_ 1255 BalrRight4Prev3X_L_Actl 1;
BA_ "U_U55X_MY2022_Tx" SG_ 1255 BalrRight4Prev3X_L_Actl 1;
BA_ "U_CD764_MY2022_Tx" SG_ 1255 BalrRight4Prev3X_L_Actl 1;
BA_ "GenSigStartValueInteger" SG_ 1255 BalrRight4Prev2Y_L_Actl 64;
BA_ "U_T6_MCA_MY2020_Tx" SG_ 1255 BalrRight4Prev2Y_L_Actl 1;
BA_ "U_CD542_MY2021_Tx" SG_ 1255 BalrRight4Prev2Y_L_Actl 1;
BA_ "U_U55X_MY2022_Tx" SG_ 1255 BalrRight4Prev2Y_L_Actl 1;
BA_ "U_CD764_MY2022_Tx" SG_ 1255 BalrRight4Prev2Y_L_Actl 1;
BA_ "GenSigStartValueInteger" SG_ 1255 BalrRight4Prev2X_L_Actl 64;
BA_ "U_T6_MCA_MY2020_Tx" SG_ 1255 BalrRight4Prev2X_L_Actl 1;
BA_ "U_CD542_MY2021_Tx" SG_ 1255 BalrRight4Prev2X_L_Actl 1;
BA_ "U_U55X_MY2022_Tx" SG_ 1255 BalrRight4Prev2X_L_Actl 1;
BA_ "U_CD764_MY2022_Tx" SG_ 1255 BalrRight4Prev2X_L_Actl 1;
BA_ "GenSigStartValueInteger" SG_ 1255 BalrRight4Prev1Y_L_Actl 64;
BA_ "U_T6_MCA_MY2020_Tx" SG_ 1255 BalrRight4Prev1Y_L_Actl 1;
BA_ "U_CD542_MY2021_Tx" SG_ 1255 BalrRight4Prev1Y_L_Actl 1;
BA_ "U_U55X_MY2022_Tx" SG_ 1255 BalrRight4Prev1Y_L_Actl 1;
BA_ "U_CD764_MY2022_Tx" SG_ 1255 BalrRight4Prev1Y_L_Actl 1;
BA_ "GenSigStartValueInteger" SG_ 1255 BalrRight4Prev1X_L_Actl 64;
BA_ "U_T6_MCA_MY2020_Tx" SG_ 1255 BalrRight4Prev1X_L_Actl 1;
BA_ "U_CD542_MY2021_Tx" SG_ 1255 BalrRight4Prev1X_L_Actl 1;
BA_ "U_U55X_MY2022_Tx" SG_ 1255 BalrRight4Prev1X_L_Actl 1;
BA_ "U_CD764_MY2022_Tx" SG_ 1255 BalrRight4Prev1X_L_Actl 1;
BA_ "U_T6_MCA_MY2020_Tx" SG_ 1255 BalrRight4Fast_B_Stat 1;
BA_ "U_CD542_MY2021_Tx" SG_ 1255 BalrRight4Fast_B_Stat 1;
BA_ "U_U55X_MY2022_Tx" SG_ 1255 BalrRight4Fast_B_Stat 1;
BA_ "U_CD764_MY2022_Tx" SG_ 1255 BalrRight4Fast_B_Stat 1;
BA_ "U_T6_MCA_MY2020_Tx" SG_ 1255 BalrRight4Dsply_B_Stat 1;
BA_ "U_CD542_MY2021_Tx" SG_ 1255 BalrRight4Dsply_B_Stat 1;
BA_ "U_U55X_MY2022_Tx" SG_ 1255 BalrRight4Dsply_B_Stat 1;
BA_ "U_CD764_MY2022_Tx" SG_ 1255 BalrRight4Dsply_B_Stat 1;
BA_ "GenSigStartValueInteger" SG_ 1255 BalrRight4CurntY_L_Actl 64;
BA_ "U_T6_MCA_MY2020_Tx" SG_ 1255 BalrRight4CurntY_L_Actl 1;
BA_ "U_CD542_MY2021_Tx" SG_ 1255 BalrRight4CurntY_L_Actl 1;
BA_ "U_U55X_MY2022_Tx" SG_ 1255 BalrRight4CurntY_L_Actl 1;
BA_ "U_CD764_MY2022_Tx" SG_ 1255 BalrRight4CurntY_L_Actl 1;
BA_ "GenSigStartValueInteger" SG_ 1255 BalrRight4CurntX_L_Actl 64;
BA_ "U_T6_MCA_MY2020_Tx" SG_ 1255 BalrRight4CurntX_L_Actl 1;
BA_ "U_CD542_MY2021_Tx" SG_ 1255 BalrRight4CurntX_L_Actl 1;
BA_ "U_U55X_MY2022_Tx" SG_ 1255 BalrRight4CurntX_L_Actl 1;
BA_ "U_CD764_MY2022_Tx" SG_ 1255 BalrRight4CurntX_L_Actl 1;
BA_ "GenSigSendType" SG_ 1254 BalrRight3Threat_D_Stat 3;
BA_ "U_T6_MCA_MY2020_Tx" SG_ 1254 BalrRight3Threat_D_Stat 1;
BA_ "U_CD542_MY2021_Tx" SG_ 1254 BalrRight3Threat_D_Stat 1;
BA_ "U_U55X_MY2022_Tx" SG_ 1254 BalrRight3Threat_D_Stat 1;
BA_ "U_CD764_MY2022_Tx" SG_ 1254 BalrRight3Threat_D_Stat 1;
BA_ "GenSigStartValueInteger" SG_ 1254 BalrRight3Prev3Y_L_Actl 64;
BA_ "U_T6_MCA_MY2020_Tx" SG_ 1254 BalrRight3Prev3Y_L_Actl 1;
BA_ "U_CD542_MY2021_Tx" SG_ 1254 BalrRight3Prev3Y_L_Actl 1;
BA_ "U_U55X_MY2022_Tx" SG_ 1254 BalrRight3Prev3Y_L_Actl 1;
BA_ "U_CD764_MY2022_Tx" SG_ 1254 BalrRight3Prev3Y_L_Actl 1;
BA_ "GenSigStartValueInteger" SG_ 1254 BalrRight3Prev3X_L_Actl 64;
BA_ "U_T6_MCA_MY2020_Tx" SG_ 1254 BalrRight3Prev3X_L_Actl 1;
BA_ "U_CD542_MY2021_Tx" SG_ 1254 BalrRight3Prev3X_L_Actl 1;
BA_ "U_U55X_MY2022_Tx" SG_ 1254 BalrRight3Prev3X_L_Actl 1;
BA_ "U_CD764_MY2022_Tx" SG_ 1254 BalrRight3Prev3X_L_Actl 1;
BA_ "GenSigStartValueInteger" SG_ 1254 BalrRight3Prev2Y_L_Actl 64;
BA_ "U_T6_MCA_MY2020_Tx" SG_ 1254 BalrRight3Prev2Y_L_Actl 1;
BA_ "U_CD542_MY2021_Tx" SG_ 1254 BalrRight3Prev2Y_L_Actl 1;
BA_ "U_U55X_MY2022_Tx" SG_ 1254 BalrRight3Prev2Y_L_Actl 1;
BA_ "U_CD764_MY2022_Tx" SG_ 1254 BalrRight3Prev2Y_L_Actl 1;
BA_ "GenSigStartValueInteger" SG_ 1254 BalrRight3Prev2X_L_Actl 64;
BA_ "U_T6_MCA_MY2020_Tx" SG_ 1254 BalrRight3Prev2X_L_Actl 1;
BA_ "U_CD542_MY2021_Tx" SG_ 1254 BalrRight3Prev2X_L_Actl 1;
BA_ "U_U55X_MY2022_Tx" SG_ 1254 BalrRight3Prev2X_L_Actl 1;
BA_ "U_CD764_MY2022_Tx" SG_ 1254 BalrRight3Prev2X_L_Actl 1;
BA_ "GenSigStartValueInteger" SG_ 1254 BalrRight3Prev1Y_L_Actl 64;
BA_ "U_T6_MCA_MY2020_Tx" SG_ 1254 BalrRight3Prev1Y_L_Actl 1;
BA_ "U_CD542_MY2021_Tx" SG_ 1254 BalrRight3Prev1Y_L_Actl 1;
BA_ "U_U55X_MY2022_Tx" SG_ 1254 BalrRight3Prev1Y_L_Actl 1;
BA_ "U_CD764_MY2022_Tx" SG_ 1254 BalrRight3Prev1Y_L_Actl 1;
BA_ "GenSigStartValueInteger" SG_ 1254 BalrRight3Prev1X_L_Actl 64;
BA_ "U_T6_MCA_MY2020_Tx" SG_ 1254 BalrRight3Prev1X_L_Actl 1;
BA_ "U_CD542_MY2021_Tx" SG_ 1254 BalrRight3Prev1X_L_Actl 1;
BA_ "U_U55X_MY2022_Tx" SG_ 1254 BalrRight3Prev1X_L_Actl 1;
BA_ "U_CD764_MY2022_Tx" SG_ 1254 BalrRight3Prev1X_L_Actl 1;
BA_ "GenSigSendType" SG_ 1254 BalrRight3Fast_B_Stat 3;
BA_ "U_T6_MCA_MY2020_Tx" SG_ 1254 BalrRight3Fast_B_Stat 1;
BA_ "U_CD542_MY2021_Tx" SG_ 1254 BalrRight3Fast_B_Stat 1;
BA_ "U_U55X_MY2022_Tx" SG_ 1254 BalrRight3Fast_B_Stat 1;
BA_ "U_CD764_MY2022_Tx" SG_ 1254 BalrRight3Fast_B_Stat 1;
BA_ "GenSigSendType" SG_ 1254 BalrRight3Dsply_B_Stat 3;
BA_ "U_T6_MCA_MY2020_Tx" SG_ 1254 BalrRight3Dsply_B_Stat 1;
BA_ "U_CD542_MY2021_Tx" SG_ 1254 BalrRight3Dsply_B_Stat 1;
BA_ "U_U55X_MY2022_Tx" SG_ 1254 BalrRight3Dsply_B_Stat 1;
BA_ "U_CD764_MY2022_Tx" SG_ 1254 BalrRight3Dsply_B_Stat 1;
BA_ "GenSigStartValueInteger" SG_ 1254 BalrRight3CurntY_L_Actl 64;
BA_ "U_T6_MCA_MY2020_Tx" SG_ 1254 BalrRight3CurntY_L_Actl 1;
BA_ "U_CD542_MY2021_Tx" SG_ 1254 BalrRight3CurntY_L_Actl 1;
BA_ "U_U55X_MY2022_Tx" SG_ 1254 BalrRight3CurntY_L_Actl 1;
BA_ "U_CD764_MY2022_Tx" SG_ 1254 BalrRight3CurntY_L_Actl 1;
BA_ "GenSigStartValueInteger" SG_ 1254 BalrRight3CurntX_L_Actl 64;
BA_ "U_T6_MCA_MY2020_Tx" SG_ 1254 BalrRight3CurntX_L_Actl 1;
BA_ "U_CD542_MY2021_Tx" SG_ 1254 BalrRight3CurntX_L_Actl 1;
BA_ "U_U55X_MY2022_Tx" SG_ 1254 BalrRight3CurntX_L_Actl 1;
BA_ "U_CD764_MY2022_Tx" SG_ 1254 BalrRight3CurntX_L_Actl 1;
BA_ "GenSigStartValueInteger" SG_ 1253 BalrRight2Prev3Y_L_Actl 64;
BA_ "U_T6_MCA_MY2020_Tx" SG_ 1253 BalrRight2Prev3Y_L_Actl 1;
BA_ "U_CD542_MY2021_Tx" SG_ 1253 BalrRight2Prev3Y_L_Actl 1;
BA_ "U_U55X_MY2022_Tx" SG_ 1253 BalrRight2Prev3Y_L_Actl 1;
BA_ "U_CD764_MY2022_Tx" SG_ 1253 BalrRight2Prev3Y_L_Actl 1;
BA_ "GenSigStartValueInteger" SG_ 1253 BalrRight2Prev3X_L_Actl 64;
BA_ "U_T6_MCA_MY2020_Tx" SG_ 1253 BalrRight2Prev3X_L_Actl 1;
BA_ "U_CD542_MY2021_Tx" SG_ 1253 BalrRight2Prev3X_L_Actl 1;
BA_ "U_U55X_MY2022_Tx" SG_ 1253 BalrRight2Prev3X_L_Actl 1;
BA_ "U_CD764_MY2022_Tx" SG_ 1253 BalrRight2Prev3X_L_Actl 1;
BA_ "GenSigSendType" SG_ 1253 BalrRight2Threat_D_Stat 3;
BA_ "U_T6_MCA_MY2020_Tx" SG_ 1253 BalrRight2Threat_D_Stat 1;
BA_ "U_CD542_MY2021_Tx" SG_ 1253 BalrRight2Threat_D_Stat 1;
BA_ "U_U55X_MY2022_Tx" SG_ 1253 BalrRight2Threat_D_Stat 1;
BA_ "U_CD764_MY2022_Tx" SG_ 1253 BalrRight2Threat_D_Stat 1;
BA_ "GenSigStartValueInteger" SG_ 1253 BalrRight2Prev2Y_L_Actl 64;
BA_ "U_T6_MCA_MY2020_Tx" SG_ 1253 BalrRight2Prev2Y_L_Actl 1;
BA_ "U_CD542_MY2021_Tx" SG_ 1253 BalrRight2Prev2Y_L_Actl 1;
BA_ "U_U55X_MY2022_Tx" SG_ 1253 BalrRight2Prev2Y_L_Actl 1;
BA_ "U_CD764_MY2022_Tx" SG_ 1253 BalrRight2Prev2Y_L_Actl 1;
BA_ "GenSigStartValueInteger" SG_ 1253 BalrRight2Prev2X_L_Actl 64;
BA_ "U_T6_MCA_MY2020_Tx" SG_ 1253 BalrRight2Prev2X_L_Actl 1;
BA_ "U_CD542_MY2021_Tx" SG_ 1253 BalrRight2Prev2X_L_Actl 1;
BA_ "U_U55X_MY2022_Tx" SG_ 1253 BalrRight2Prev2X_L_Actl 1;
BA_ "U_CD764_MY2022_Tx" SG_ 1253 BalrRight2Prev2X_L_Actl 1;
BA_ "GenSigStartValueInteger" SG_ 1253 BalrRight2Prev1Y_L_Actl 64;
BA_ "U_T6_MCA_MY2020_Tx" SG_ 1253 BalrRight2Prev1Y_L_Actl 1;
BA_ "U_CD542_MY2021_Tx" SG_ 1253 BalrRight2Prev1Y_L_Actl 1;
BA_ "U_U55X_MY2022_Tx" SG_ 1253 BalrRight2Prev1Y_L_Actl 1;
BA_ "U_CD764_MY2022_Tx" SG_ 1253 BalrRight2Prev1Y_L_Actl 1;
BA_ "GenSigStartValueInteger" SG_ 1253 BalrRight2Prev1X_L_Actl 64;
BA_ "U_T6_MCA_MY2020_Tx" SG_ 1253 BalrRight2Prev1X_L_Actl 1;
BA_ "U_CD542_MY2021_Tx" SG_ 1253 BalrRight2Prev1X_L_Actl 1;
BA_ "U_U55X_MY2022_Tx" SG_ 1253 BalrRight2Prev1X_L_Actl 1;
BA_ "U_CD764_MY2022_Tx" SG_ 1253 BalrRight2Prev1X_L_Actl 1;
BA_ "GenSigSendType" SG_ 1253 BalrRight2Fast_B_Stat 3;
BA_ "U_T6_MCA_MY2020_Tx" SG_ 1253 BalrRight2Fast_B_Stat 1;
BA_ "U_CD542_MY2021_Tx" SG_ 1253 BalrRight2Fast_B_Stat 1;
BA_ "U_U55X_MY2022_Tx" SG_ 1253 BalrRight2Fast_B_Stat 1;
BA_ "U_CD764_MY2022_Tx" SG_ 1253 BalrRight2Fast_B_Stat 1;
BA_ "GenSigSendType" SG_ 1253 BalrRight2Dsply_B_Stat 3;
BA_ "U_T6_MCA_MY2020_Tx" SG_ 1253 BalrRight2Dsply_B_Stat 1;
BA_ "U_CD542_MY2021_Tx" SG_ 1253 BalrRight2Dsply_B_Stat 1;
BA_ "U_U55X_MY2022_Tx" SG_ 1253 BalrRight2Dsply_B_Stat 1;
BA_ "U_CD764_MY2022_Tx" SG_ 1253 BalrRight2Dsply_B_Stat 1;
BA_ "GenSigStartValueInteger" SG_ 1253 BalrRight2CurntY_L_Actl 64;
BA_ "U_T6_MCA_MY2020_Tx" SG_ 1253 BalrRight2CurntY_L_Actl 1;
BA_ "U_CD542_MY2021_Tx" SG_ 1253 BalrRight2CurntY_L_Actl 1;
BA_ "U_U55X_MY2022_Tx" SG_ 1253 BalrRight2CurntY_L_Actl 1;
BA_ "U_CD764_MY2022_Tx" SG_ 1253 BalrRight2CurntY_L_Actl 1;
BA_ "GenSigStartValueInteger" SG_ 1253 BalrRight2CurntX_L_Actl 64;
BA_ "U_T6_MCA_MY2020_Tx" SG_ 1253 BalrRight2CurntX_L_Actl 1;
BA_ "U_CD542_MY2021_Tx" SG_ 1253 BalrRight2CurntX_L_Actl 1;
BA_ "U_U55X_MY2022_Tx" SG_ 1253 BalrRight2CurntX_L_Actl 1;
BA_ "U_CD764_MY2022_Tx" SG_ 1253 BalrRight2CurntX_L_Actl 1;
BA_ "GenSigStartValueInteger" SG_ 1252 BalrRight1Prev3Y_L_Actl 64;
BA_ "U_T6_MCA_MY2020_Tx" SG_ 1252 BalrRight1Prev3Y_L_Actl 1;
BA_ "U_CD542_MY2021_Tx" SG_ 1252 BalrRight1Prev3Y_L_Actl 1;
BA_ "U_U55X_MY2022_Tx" SG_ 1252 BalrRight1Prev3Y_L_Actl 1;
BA_ "U_CD764_MY2022_Tx" SG_ 1252 BalrRight1Prev3Y_L_Actl 1;
BA_ "GenSigStartValueInteger" SG_ 1252 BalrRight1Prev3X_L_Actl 64;
BA_ "U_T6_MCA_MY2020_Tx" SG_ 1252 BalrRight1Prev3X_L_Actl 1;
BA_ "U_CD542_MY2021_Tx" SG_ 1252 BalrRight1Prev3X_L_Actl 1;
BA_ "U_U55X_MY2022_Tx" SG_ 1252 BalrRight1Prev3X_L_Actl 1;
BA_ "U_CD764_MY2022_Tx" SG_ 1252 BalrRight1Prev3X_L_Actl 1;
BA_ "GenSigSendType" SG_ 1252 BalrRight1Threat_D_Stat 3;
BA_ "U_T6_MCA_MY2020_Tx" SG_ 1252 BalrRight1Threat_D_Stat 1;
BA_ "U_CD542_MY2021_Tx" SG_ 1252 BalrRight1Threat_D_Stat 1;
BA_ "U_U55X_MY2022_Tx" SG_ 1252 BalrRight1Threat_D_Stat 1;
BA_ "U_CD764_MY2022_Tx" SG_ 1252 BalrRight1Threat_D_Stat 1;
BA_ "GenSigStartValueInteger" SG_ 1252 BalrRight1Prev2Y_L_Actl 64;
BA_ "U_T6_MCA_MY2020_Tx" SG_ 1252 BalrRight1Prev2Y_L_Actl 1;
BA_ "U_CD542_MY2021_Tx" SG_ 1252 BalrRight1Prev2Y_L_Actl 1;
BA_ "U_U55X_MY2022_Tx" SG_ 1252 BalrRight1Prev2Y_L_Actl 1;
BA_ "U_CD764_MY2022_Tx" SG_ 1252 BalrRight1Prev2Y_L_Actl 1;
BA_ "GenSigStartValueInteger" SG_ 1252 BalrRight1Prev2X_L_Actl 64;
BA_ "U_T6_MCA_MY2020_Tx" SG_ 1252 BalrRight1Prev2X_L_Actl 1;
BA_ "U_CD542_MY2021_Tx" SG_ 1252 BalrRight1Prev2X_L_Actl 1;
BA_ "U_U55X_MY2022_Tx" SG_ 1252 BalrRight1Prev2X_L_Actl 1;
BA_ "U_CD764_MY2022_Tx" SG_ 1252 BalrRight1Prev2X_L_Actl 1;
BA_ "GenSigStartValueInteger" SG_ 1252 BalrRight1Prev1Y_L_Actl 64;
BA_ "U_T6_MCA_MY2020_Tx" SG_ 1252 BalrRight1Prev1Y_L_Actl 1;
BA_ "U_CD542_MY2021_Tx" SG_ 1252 BalrRight1Prev1Y_L_Actl 1;
BA_ "U_U55X_MY2022_Tx" SG_ 1252 BalrRight1Prev1Y_L_Actl 1;
BA_ "U_CD764_MY2022_Tx" SG_ 1252 BalrRight1Prev1Y_L_Actl 1;
BA_ "GenSigStartValueInteger" SG_ 1252 BalrRight1Prev1X_L_Actl 64;
BA_ "U_T6_MCA_MY2020_Tx" SG_ 1252 BalrRight1Prev1X_L_Actl 1;
BA_ "U_CD542_MY2021_Tx" SG_ 1252 BalrRight1Prev1X_L_Actl 1;
BA_ "U_U55X_MY2022_Tx" SG_ 1252 BalrRight1Prev1X_L_Actl 1;
BA_ "U_CD764_MY2022_Tx" SG_ 1252 BalrRight1Prev1X_L_Actl 1;
BA_ "GenSigSendType" SG_ 1252 BalrRight1Fast_B_Stat 3;
BA_ "U_T6_MCA_MY2020_Tx" SG_ 1252 BalrRight1Fast_B_Stat 1;
BA_ "U_CD542_MY2021_Tx" SG_ 1252 BalrRight1Fast_B_Stat 1;
BA_ "U_U55X_MY2022_Tx" SG_ 1252 BalrRight1Fast_B_Stat 1;
BA_ "U_CD764_MY2022_Tx" SG_ 1252 BalrRight1Fast_B_Stat 1;
BA_ "GenSigSendType" SG_ 1252 BalrRight1Dsply_B_Stat 3;
BA_ "U_T6_MCA_MY2020_Tx" SG_ 1252 BalrRight1Dsply_B_Stat 1;
BA_ "U_CD542_MY2021_Tx" SG_ 1252 BalrRight1Dsply_B_Stat 1;
BA_ "U_U55X_MY2022_Tx" SG_ 1252 BalrRight1Dsply_B_Stat 1;
BA_ "U_CD764_MY2022_Tx" SG_ 1252 BalrRight1Dsply_B_Stat 1;
BA_ "GenSigStartValueInteger" SG_ 1252 BalrRight1CurntY_L_Actl 64;
BA_ "U_T6_MCA_MY2020_Tx" SG_ 1252 BalrRight1CurntY_L_Actl 1;
BA_ "U_CD542_MY2021_Tx" SG_ 1252 BalrRight1CurntY_L_Actl 1;
BA_ "U_U55X_MY2022_Tx" SG_ 1252 BalrRight1CurntY_L_Actl 1;
BA_ "U_CD764_MY2022_Tx" SG_ 1252 BalrRight1CurntY_L_Actl 1;
BA_ "GenSigStartValueInteger" SG_ 1252 BalrRight1CurntX_L_Actl 64;
BA_ "U_T6_MCA_MY2020_Tx" SG_ 1252 BalrRight1CurntX_L_Actl 1;
BA_ "U_CD542_MY2021_Tx" SG_ 1252 BalrRight1CurntX_L_Actl 1;
BA_ "U_U55X_MY2022_Tx" SG_ 1252 BalrRight1CurntX_L_Actl 1;
BA_ "U_CD764_MY2022_Tx" SG_ 1252 BalrRight1CurntX_L_Actl 1;
BA_ "U_T6_MCA_MY2020_Tx" SG_ 1251 BalrLeft4Threat_D_Stat 1;
BA_ "U_CD542_MY2021_Tx" SG_ 1251 BalrLeft4Threat_D_Stat 1;
BA_ "U_U55X_MY2022_Tx" SG_ 1251 BalrLeft4Threat_D_Stat 1;
BA_ "U_CD764_MY2022_Tx" SG_ 1251 BalrLeft4Threat_D_Stat 1;
BA_ "GenSigStartValueInteger" SG_ 1251 BalrLeft4Prev3Y_L_Actl 64;
BA_ "U_T6_MCA_MY2020_Tx" SG_ 1251 BalrLeft4Prev3Y_L_Actl 1;
BA_ "U_CD542_MY2021_Tx" SG_ 1251 BalrLeft4Prev3Y_L_Actl 1;
BA_ "U_U55X_MY2022_Tx" SG_ 1251 BalrLeft4Prev3Y_L_Actl 1;
BA_ "U_CD764_MY2022_Tx" SG_ 1251 BalrLeft4Prev3Y_L_Actl 1;
BA_ "GenSigStartValueInteger" SG_ 1251 BalrLeft4Prev3X_L_Actl 64;
BA_ "U_T6_MCA_MY2020_Tx" SG_ 1251 BalrLeft4Prev3X_L_Actl 1;
BA_ "U_CD542_MY2021_Tx" SG_ 1251 BalrLeft4Prev3X_L_Actl 1;
BA_ "U_U55X_MY2022_Tx" SG_ 1251 BalrLeft4Prev3X_L_Actl 1;
BA_ "U_CD764_MY2022_Tx" SG_ 1251 BalrLeft4Prev3X_L_Actl 1;
BA_ "GenSigStartValueInteger" SG_ 1251 BalrLeft4Prev2Y_L_Actl 64;
BA_ "U_T6_MCA_MY2020_Tx" SG_ 1251 BalrLeft4Prev2Y_L_Actl 1;
BA_ "U_CD542_MY2021_Tx" SG_ 1251 BalrLeft4Prev2Y_L_Actl 1;
BA_ "U_U55X_MY2022_Tx" SG_ 1251 BalrLeft4Prev2Y_L_Actl 1;
BA_ "U_CD764_MY2022_Tx" SG_ 1251 BalrLeft4Prev2Y_L_Actl 1;
BA_ "GenSigStartValueInteger" SG_ 1251 BalrLeft4Prev2X_L_Actl 64;
BA_ "U_T6_MCA_MY2020_Tx" SG_ 1251 BalrLeft4Prev2X_L_Actl 1;
BA_ "U_CD542_MY2021_Tx" SG_ 1251 BalrLeft4Prev2X_L_Actl 1;
BA_ "U_U55X_MY2022_Tx" SG_ 1251 BalrLeft4Prev2X_L_Actl 1;
BA_ "U_CD764_MY2022_Tx" SG_ 1251 BalrLeft4Prev2X_L_Actl 1;
BA_ "GenSigStartValueInteger" SG_ 1251 BalrLeft4Prev1Y_L_Actl 64;
BA_ "U_T6_MCA_MY2020_Tx" SG_ 1251 BalrLeft4Prev1Y_L_Actl 1;
BA_ "U_CD542_MY2021_Tx" SG_ 1251 BalrLeft4Prev1Y_L_Actl 1;
BA_ "U_U55X_MY2022_Tx" SG_ 1251 BalrLeft4Prev1Y_L_Actl 1;
BA_ "U_CD764_MY2022_Tx" SG_ 1251 BalrLeft4Prev1Y_L_Actl 1;
BA_ "GenSigStartValueInteger" SG_ 1251 BalrLeft4Prev1X_L_Actl 64;
BA_ "U_T6_MCA_MY2020_Tx" SG_ 1251 BalrLeft4Prev1X_L_Actl 1;
BA_ "U_CD542_MY2021_Tx" SG_ 1251 BalrLeft4Prev1X_L_Actl 1;
BA_ "U_U55X_MY2022_Tx" SG_ 1251 BalrLeft4Prev1X_L_Actl 1;
BA_ "U_CD764_MY2022_Tx" SG_ 1251 BalrLeft4Prev1X_L_Actl 1;
BA_ "U_T6_MCA_MY2020_Tx" SG_ 1251 BalrLeft4Fast_B_Stat 1;
BA_ "U_CD542_MY2021_Tx" SG_ 1251 BalrLeft4Fast_B_Stat 1;
BA_ "U_U55X_MY2022_Tx" SG_ 1251 BalrLeft4Fast_B_Stat 1;
BA_ "U_CD764_MY2022_Tx" SG_ 1251 BalrLeft4Fast_B_Stat 1;
BA_ "U_T6_MCA_MY2020_Tx" SG_ 1251 BalrLeft4Dsply_B_Stat 1;
BA_ "U_CD542_MY2021_Tx" SG_ 1251 BalrLeft4Dsply_B_Stat 1;
BA_ "U_U55X_MY2022_Tx" SG_ 1251 BalrLeft4Dsply_B_Stat 1;
BA_ "U_CD764_MY2022_Tx" SG_ 1251 BalrLeft4Dsply_B_Stat 1;
BA_ "GenSigStartValueInteger" SG_ 1251 BalrLeft4CurntY_L_Actl 64;
BA_ "U_T6_MCA_MY2020_Tx" SG_ 1251 BalrLeft4CurntY_L_Actl 1;
BA_ "U_CD542_MY2021_Tx" SG_ 1251 BalrLeft4CurntY_L_Actl 1;
BA_ "U_U55X_MY2022_Tx" SG_ 1251 BalrLeft4CurntY_L_Actl 1;
BA_ "U_CD764_MY2022_Tx" SG_ 1251 BalrLeft4CurntY_L_Actl 1;
BA_ "GenSigStartValueInteger" SG_ 1251 BalrLeft4CurntX_L_Actl 64;
BA_ "U_T6_MCA_MY2020_Tx" SG_ 1251 BalrLeft4CurntX_L_Actl 1;
BA_ "U_CD542_MY2021_Tx" SG_ 1251 BalrLeft4CurntX_L_Actl 1;
BA_ "U_U55X_MY2022_Tx" SG_ 1251 BalrLeft4CurntX_L_Actl 1;
BA_ "U_CD764_MY2022_Tx" SG_ 1251 BalrLeft4CurntX_L_Actl 1;
BA_ "U_T6_MCA_MY2020_Tx" SG_ 1250 BalrLeft3Threat_D_Stat 1;
BA_ "U_CD542_MY2021_Tx" SG_ 1250 BalrLeft3Threat_D_Stat 1;
BA_ "U_U55X_MY2022_Tx" SG_ 1250 BalrLeft3Threat_D_Stat 1;
BA_ "U_CD764_MY2022_Tx" SG_ 1250 BalrLeft3Threat_D_Stat 1;
BA_ "GenSigStartValueInteger" SG_ 1250 BalrLeft3Prev3Y_L_Actl 64;
BA_ "U_T6_MCA_MY2020_Tx" SG_ 1250 BalrLeft3Prev3Y_L_Actl 1;
BA_ "U_CD542_MY2021_Tx" SG_ 1250 BalrLeft3Prev3Y_L_Actl 1;
BA_ "U_U55X_MY2022_Tx" SG_ 1250 BalrLeft3Prev3Y_L_Actl 1;
BA_ "U_CD764_MY2022_Tx" SG_ 1250 BalrLeft3Prev3Y_L_Actl 1;
BA_ "GenSigStartValueInteger" SG_ 1250 BalrLeft3Prev3X_L_Actl 64;
BA_ "U_T6_MCA_MY2020_Tx" SG_ 1250 BalrLeft3Prev3X_L_Actl 1;
BA_ "U_CD542_MY2021_Tx" SG_ 1250 BalrLeft3Prev3X_L_Actl 1;
BA_ "U_U55X_MY2022_Tx" SG_ 1250 BalrLeft3Prev3X_L_Actl 1;
BA_ "U_CD764_MY2022_Tx" SG_ 1250 BalrLeft3Prev3X_L_Actl 1;
BA_ "GenSigStartValueInteger" SG_ 1250 BalrLeft3Prev2Y_L_Actl 64;
BA_ "U_T6_MCA_MY2020_Tx" SG_ 1250 BalrLeft3Prev2Y_L_Actl 1;
BA_ "U_CD542_MY2021_Tx" SG_ 1250 BalrLeft3Prev2Y_L_Actl 1;
BA_ "U_U55X_MY2022_Tx" SG_ 1250 BalrLeft3Prev2Y_L_Actl 1;
BA_ "U_CD764_MY2022_Tx" SG_ 1250 BalrLeft3Prev2Y_L_Actl 1;
BA_ "GenSigStartValueInteger" SG_ 1250 BalrLeft3Prev2X_L_Actl 64;
BA_ "U_T6_MCA_MY2020_Tx" SG_ 1250 BalrLeft3Prev2X_L_Actl 1;
BA_ "U_CD542_MY2021_Tx" SG_ 1250 BalrLeft3Prev2X_L_Actl 1;
BA_ "U_U55X_MY2022_Tx" SG_ 1250 BalrLeft3Prev2X_L_Actl 1;
BA_ "U_CD764_MY2022_Tx" SG_ 1250 BalrLeft3Prev2X_L_Actl 1;
BA_ "GenSigStartValueInteger" SG_ 1250 BalrLeft3Prev1Y_L_Actl 64;
BA_ "U_T6_MCA_MY2020_Tx" SG_ 1250 BalrLeft3Prev1Y_L_Actl 1;
BA_ "U_CD542_MY2021_Tx" SG_ 1250 BalrLeft3Prev1Y_L_Actl 1;
BA_ "U_U55X_MY2022_Tx" SG_ 1250 BalrLeft3Prev1Y_L_Actl 1;
BA_ "U_CD764_MY2022_Tx" SG_ 1250 BalrLeft3Prev1Y_L_Actl 1;
BA_ "GenSigStartValueInteger" SG_ 1250 BalrLeft3Prev1X_L_Actl 64;
BA_ "U_T6_MCA_MY2020_Tx" SG_ 1250 BalrLeft3Prev1X_L_Actl 1;
BA_ "U_CD542_MY2021_Tx" SG_ 1250 BalrLeft3Prev1X_L_Actl 1;
BA_ "U_U55X_MY2022_Tx" SG_ 1250 BalrLeft3Prev1X_L_Actl 1;
BA_ "U_CD764_MY2022_Tx" SG_ 1250 BalrLeft3Prev1X_L_Actl 1;
BA_ "U_T6_MCA_MY2020_Tx" SG_ 1250 BalrLeft3Fast_B_Stat 1;
BA_ "U_CD542_MY2021_Tx" SG_ 1250 BalrLeft3Fast_B_Stat 1;
BA_ "U_U55X_MY2022_Tx" SG_ 1250 BalrLeft3Fast_B_Stat 1;
BA_ "U_CD764_MY2022_Tx" SG_ 1250 BalrLeft3Fast_B_Stat 1;
BA_ "U_T6_MCA_MY2020_Tx" SG_ 1250 BalrLeft3Dsply_B_Stat 1;
BA_ "U_CD542_MY2021_Tx" SG_ 1250 BalrLeft3Dsply_B_Stat 1;
BA_ "U_U55X_MY2022_Tx" SG_ 1250 BalrLeft3Dsply_B_Stat 1;
BA_ "U_CD764_MY2022_Tx" SG_ 1250 BalrLeft3Dsply_B_Stat 1;
BA_ "GenSigStartValueInteger" SG_ 1250 BalrLeft3CurntY_L_Actl 64;
BA_ "U_T6_MCA_MY2020_Tx" SG_ 1250 BalrLeft3CurntY_L_Actl 1;
BA_ "U_CD542_MY2021_Tx" SG_ 1250 BalrLeft3CurntY_L_Actl 1;
BA_ "U_U55X_MY2022_Tx" SG_ 1250 BalrLeft3CurntY_L_Actl 1;
BA_ "U_CD764_MY2022_Tx" SG_ 1250 BalrLeft3CurntY_L_Actl 1;
BA_ "GenSigStartValueInteger" SG_ 1250 BalrLeft3CurntX_L_Actl 64;
BA_ "U_T6_MCA_MY2020_Tx" SG_ 1250 BalrLeft3CurntX_L_Actl 1;
BA_ "U_CD542_MY2021_Tx" SG_ 1250 BalrLeft3CurntX_L_Actl 1;
BA_ "U_U55X_MY2022_Tx" SG_ 1250 BalrLeft3CurntX_L_Actl 1;
BA_ "U_CD764_MY2022_Tx" SG_ 1250 BalrLeft3CurntX_L_Actl 1;
BA_ "GenSigStartValueInteger" SG_ 1249 BalrLeft2Prev3Y_L_Actl 64;
BA_ "U_T6_MCA_MY2020_Tx" SG_ 1249 BalrLeft2Prev3Y_L_Actl 1;
BA_ "U_CD542_MY2021_Tx" SG_ 1249 BalrLeft2Prev3Y_L_Actl 1;
BA_ "U_U55X_MY2022_Tx" SG_ 1249 BalrLeft2Prev3Y_L_Actl 1;
BA_ "U_CD764_MY2022_Tx" SG_ 1249 BalrLeft2Prev3Y_L_Actl 1;
BA_ "GenSigStartValueInteger" SG_ 1249 BalrLeft2Prev3X_L_Actl 64;
BA_ "U_T6_MCA_MY2020_Tx" SG_ 1249 BalrLeft2Prev3X_L_Actl 1;
BA_ "U_CD542_MY2021_Tx" SG_ 1249 BalrLeft2Prev3X_L_Actl 1;
BA_ "U_U55X_MY2022_Tx" SG_ 1249 BalrLeft2Prev3X_L_Actl 1;
BA_ "U_CD764_MY2022_Tx" SG_ 1249 BalrLeft2Prev3X_L_Actl 1;
BA_ "U_T6_MCA_MY2020_Tx" SG_ 1249 BalrLeft2Threat_D_Stat 1;
BA_ "U_CD542_MY2021_Tx" SG_ 1249 BalrLeft2Threat_D_Stat 1;
BA_ "U_U55X_MY2022_Tx" SG_ 1249 BalrLeft2Threat_D_Stat 1;
BA_ "U_CD764_MY2022_Tx" SG_ 1249 BalrLeft2Threat_D_Stat 1;
BA_ "GenSigStartValueInteger" SG_ 1249 BalrLeft2Prev2Y_L_Actl 64;
BA_ "U_T6_MCA_MY2020_Tx" SG_ 1249 BalrLeft2Prev2Y_L_Actl 1;
BA_ "U_CD542_MY2021_Tx" SG_ 1249 BalrLeft2Prev2Y_L_Actl 1;
BA_ "U_U55X_MY2022_Tx" SG_ 1249 BalrLeft2Prev2Y_L_Actl 1;
BA_ "U_CD764_MY2022_Tx" SG_ 1249 BalrLeft2Prev2Y_L_Actl 1;
BA_ "GenSigStartValueInteger" SG_ 1249 BalrLeft2Prev2X_L_Actl 64;
BA_ "U_T6_MCA_MY2020_Tx" SG_ 1249 BalrLeft2Prev2X_L_Actl 1;
BA_ "U_CD542_MY2021_Tx" SG_ 1249 BalrLeft2Prev2X_L_Actl 1;
BA_ "U_U55X_MY2022_Tx" SG_ 1249 BalrLeft2Prev2X_L_Actl 1;
BA_ "U_CD764_MY2022_Tx" SG_ 1249 BalrLeft2Prev2X_L_Actl 1;
BA_ "GenSigStartValueInteger" SG_ 1249 BalrLeft2Prev1Y_L_Actl 64;
BA_ "U_T6_MCA_MY2020_Tx" SG_ 1249 BalrLeft2Prev1Y_L_Actl 1;
BA_ "U_CD542_MY2021_Tx" SG_ 1249 BalrLeft2Prev1Y_L_Actl 1;
BA_ "U_U55X_MY2022_Tx" SG_ 1249 BalrLeft2Prev1Y_L_Actl 1;
BA_ "U_CD764_MY2022_Tx" SG_ 1249 BalrLeft2Prev1Y_L_Actl 1;
BA_ "GenSigStartValueInteger" SG_ 1249 BalrLeft2Prev1X_L_Actl 64;
BA_ "U_T6_MCA_MY2020_Tx" SG_ 1249 BalrLeft2Prev1X_L_Actl 1;
BA_ "U_CD542_MY2021_Tx" SG_ 1249 BalrLeft2Prev1X_L_Actl 1;
BA_ "U_U55X_MY2022_Tx" SG_ 1249 BalrLeft2Prev1X_L_Actl 1;
BA_ "U_CD764_MY2022_Tx" SG_ 1249 BalrLeft2Prev1X_L_Actl 1;
BA_ "U_T6_MCA_MY2020_Tx" SG_ 1249 BalrLeft2Fast_B_Stat 1;
BA_ "U_CD542_MY2021_Tx" SG_ 1249 BalrLeft2Fast_B_Stat 1;
BA_ "U_U55X_MY2022_Tx" SG_ 1249 BalrLeft2Fast_B_Stat 1;
BA_ "U_CD764_MY2022_Tx" SG_ 1249 BalrLeft2Fast_B_Stat 1;
BA_ "U_T6_MCA_MY2020_Tx" SG_ 1249 BalrLeft2Dsply_B_Stat 1;
BA_ "U_CD542_MY2021_Tx" SG_ 1249 BalrLeft2Dsply_B_Stat 1;
BA_ "U_U55X_MY2022_Tx" SG_ 1249 BalrLeft2Dsply_B_Stat 1;
BA_ "U_CD764_MY2022_Tx" SG_ 1249 BalrLeft2Dsply_B_Stat 1;
BA_ "GenSigStartValueInteger" SG_ 1249 BalrLeft2CurntY_L_Actl 64;
BA_ "U_T6_MCA_MY2020_Tx" SG_ 1249 BalrLeft2CurntY_L_Actl 1;
BA_ "U_CD542_MY2021_Tx" SG_ 1249 BalrLeft2CurntY_L_Actl 1;
BA_ "U_U55X_MY2022_Tx" SG_ 1249 BalrLeft2CurntY_L_Actl 1;
BA_ "U_CD764_MY2022_Tx" SG_ 1249 BalrLeft2CurntY_L_Actl 1;
BA_ "GenSigStartValueInteger" SG_ 1249 BalrLeft2CurntX_L_Actl 64;
BA_ "U_T6_MCA_MY2020_Tx" SG_ 1249 BalrLeft2CurntX_L_Actl 1;
BA_ "U_CD542_MY2021_Tx" SG_ 1249 BalrLeft2CurntX_L_Actl 1;
BA_ "U_U55X_MY2022_Tx" SG_ 1249 BalrLeft2CurntX_L_Actl 1;
BA_ "U_CD764_MY2022_Tx" SG_ 1249 BalrLeft2CurntX_L_Actl 1;
BA_ "GenSigSendType" SG_ 1248 BalrLeft1Threat_D_Stat 3;
BA_ "U_T6_MCA_MY2020_Tx" SG_ 1248 BalrLeft1Threat_D_Stat 1;
BA_ "U_CD542_MY2021_Tx" SG_ 1248 BalrLeft1Threat_D_Stat 1;
BA_ "U_U55X_MY2022_Tx" SG_ 1248 BalrLeft1Threat_D_Stat 1;
BA_ "U_CD764_MY2022_Tx" SG_ 1248 BalrLeft1Threat_D_Stat 1;
BA_ "GenSigStartValueInteger" SG_ 1248 BalrLeft1Prev3Y_L_Actl 64;
BA_ "U_T6_MCA_MY2020_Tx" SG_ 1248 BalrLeft1Prev3Y_L_Actl 1;
BA_ "U_CD542_MY2021_Tx" SG_ 1248 BalrLeft1Prev3Y_L_Actl 1;
BA_ "U_U55X_MY2022_Tx" SG_ 1248 BalrLeft1Prev3Y_L_Actl 1;
BA_ "U_CD764_MY2022_Tx" SG_ 1248 BalrLeft1Prev3Y_L_Actl 1;
BA_ "GenSigStartValueInteger" SG_ 1248 BalrLeft1Prev3X_L_Actl 64;
BA_ "U_T6_MCA_MY2020_Tx" SG_ 1248 BalrLeft1Prev3X_L_Actl 1;
BA_ "U_CD542_MY2021_Tx" SG_ 1248 BalrLeft1Prev3X_L_Actl 1;
BA_ "U_U55X_MY2022_Tx" SG_ 1248 BalrLeft1Prev3X_L_Actl 1;
BA_ "U_CD764_MY2022_Tx" SG_ 1248 BalrLeft1Prev3X_L_Actl 1;
BA_ "GenSigStartValueInteger" SG_ 1248 BalrLeft1Prev2Y_L_Actl 64;
BA_ "U_T6_MCA_MY2020_Tx" SG_ 1248 BalrLeft1Prev2Y_L_Actl 1;
BA_ "U_CD542_MY2021_Tx" SG_ 1248 BalrLeft1Prev2Y_L_Actl 1;
BA_ "U_U55X_MY2022_Tx" SG_ 1248 BalrLeft1Prev2Y_L_Actl 1;
BA_ "U_CD764_MY2022_Tx" SG_ 1248 BalrLeft1Prev2Y_L_Actl 1;
BA_ "GenSigStartValueInteger" SG_ 1248 BalrLeft1Prev2X_L_Actl 64;
BA_ "U_T6_MCA_MY2020_Tx" SG_ 1248 BalrLeft1Prev2X_L_Actl 1;
BA_ "U_CD542_MY2021_Tx" SG_ 1248 BalrLeft1Prev2X_L_Actl 1;
BA_ "U_U55X_MY2022_Tx" SG_ 1248 BalrLeft1Prev2X_L_Actl 1;
BA_ "U_CD764_MY2022_Tx" SG_ 1248 BalrLeft1Prev2X_L_Actl 1;
BA_ "GenSigStartValueInteger" SG_ 1248 BalrLeft1Prev1Y_L_Actl 64;
BA_ "U_T6_MCA_MY2020_Tx" SG_ 1248 BalrLeft1Prev1Y_L_Actl 1;
BA_ "U_CD542_MY2021_Tx" SG_ 1248 BalrLeft1Prev1Y_L_Actl 1;
BA_ "U_U55X_MY2022_Tx" SG_ 1248 BalrLeft1Prev1Y_L_Actl 1;
BA_ "U_CD764_MY2022_Tx" SG_ 1248 BalrLeft1Prev1Y_L_Actl 1;
BA_ "GenSigStartValueInteger" SG_ 1248 BalrLeft1Prev1X_L_Actl 64;
BA_ "U_T6_MCA_MY2020_Tx" SG_ 1248 BalrLeft1Prev1X_L_Actl 1;
BA_ "U_CD542_MY2021_Tx" SG_ 1248 BalrLeft1Prev1X_L_Actl 1;
BA_ "U_U55X_MY2022_Tx" SG_ 1248 BalrLeft1Prev1X_L_Actl 1;
BA_ "U_CD764_MY2022_Tx" SG_ 1248 BalrLeft1Prev1X_L_Actl 1;
BA_ "GenSigSendType" SG_ 1248 BalrLeft1Fast_B_Stat 3;
BA_ "U_T6_MCA_MY2020_Tx" SG_ 1248 BalrLeft1Fast_B_Stat 1;
BA_ "U_CD542_MY2021_Tx" SG_ 1248 BalrLeft1Fast_B_Stat 1;
BA_ "U_U55X_MY2022_Tx" SG_ 1248 BalrLeft1Fast_B_Stat 1;
BA_ "U_CD764_MY2022_Tx" SG_ 1248 BalrLeft1Fast_B_Stat 1;
BA_ "GenSigSendType" SG_ 1248 BalrLeft1Dsply_B_Stat 3;
BA_ "U_T6_MCA_MY2020_Tx" SG_ 1248 BalrLeft1Dsply_B_Stat 1;
BA_ "U_CD542_MY2021_Tx" SG_ 1248 BalrLeft1Dsply_B_Stat 1;
BA_ "U_U55X_MY2022_Tx" SG_ 1248 BalrLeft1Dsply_B_Stat 1;
BA_ "U_CD764_MY2022_Tx" SG_ 1248 BalrLeft1Dsply_B_Stat 1;
BA_ "GenSigStartValueInteger" SG_ 1248 BalrLeft1CurntY_L_Actl 64;
BA_ "U_T6_MCA_MY2020_Tx" SG_ 1248 BalrLeft1CurntY_L_Actl 1;
BA_ "U_CD542_MY2021_Tx" SG_ 1248 BalrLeft1CurntY_L_Actl 1;
BA_ "U_U55X_MY2022_Tx" SG_ 1248 BalrLeft1CurntY_L_Actl 1;
BA_ "U_CD764_MY2022_Tx" SG_ 1248 BalrLeft1CurntY_L_Actl 1;
BA_ "GenSigStartValueInteger" SG_ 1248 BalrLeft1CurntX_L_Actl 64;
BA_ "U_T6_MCA_MY2020_Tx" SG_ 1248 BalrLeft1CurntX_L_Actl 1;
BA_ "U_CD542_MY2021_Tx" SG_ 1248 BalrLeft1CurntX_L_Actl 1;
BA_ "U_U55X_MY2022_Tx" SG_ 1248 BalrLeft1CurntX_L_Actl 1;
BA_ "U_CD764_MY2022_Tx" SG_ 1248 BalrLeft1CurntX_L_Actl 1;
BA_ "GenSigSendType" SG_ 2610988248 PARSEDPhysGWM_ECGtoIPMA 3;
BA_ "U_T6_MCA_MY2020_Rx" SG_ 2610988248 PARSEDPhysGWM_ECGtoIPMA 1;
BA_ "U_CD542_MY2021_Rx" SG_ 2610988248 PARSEDPhysGWM_ECGtoIPMA 1;
BA_ "U_U55X_MY2022_Rx" SG_ 2610988248 PARSEDPhysGWM_ECGtoIPMA 1;
BA_ "U_CD764_MY2022_Rx" SG_ 2610988248 PARSEDPhysGWM_ECGtoIPMA 1;
BA_ "U_T6_MCA_MY2020_Tx" SG_ 2610988248 PARSEDPhysGWM_ECGtoIPMA 1;
BA_ "ECGUsedTxSignal" SG_ 2610988248 PARSEDPhysGWM_ECGtoIPMA 1;
BA_ "U_CD542_MY2021_Tx" SG_ 2610988248 PARSEDPhysGWM_ECGtoIPMA 1;
BA_ "U_U55X_MY2022_Tx" SG_ 2610988248 PARSEDPhysGWM_ECGtoIPMA 1;
BA_ "U_CD764_MY2022_Tx" SG_ 2610988248 PARSEDPhysGWM_ECGtoIPMA 1;
BA_ "U_P702_MY2021_Rx" SG_ 1113 TrlrTrgtAcquire_D_Stat 1;
BA_ "U_T6_MCA_MY2020_Rx" SG_ 1113 TrlrTrgtAcquire_D_Stat 1;
BA_ "U_U55X_MY2022_Rx" SG_ 1113 TrlrTrgtAcquire_D_Stat 1;
BA_ "U_T6_MCA_MY2020_Tx" SG_ 1113 TrlrTrgtAcquire_D_Stat 1;
BA_ "U_CD542_MY2021_Tx" SG_ 1113 TrlrTrgtAcquire_D_Stat 1;
BA_ "U_U55X_MY2022_Tx" SG_ 1113 TrlrTrgtAcquire_D_Stat 1;
BA_ "U_CD764_MY2022_Tx" SG_ 1113 TrlrTrgtAcquire_D_Stat 1;
BA_ "U_T6_MCA_MY2020_Tx" SG_ 1113 TrlrAnOffst_An_Calc 1;
BA_ "U_CD542_MY2021_Tx" SG_ 1113 TrlrAnOffst_An_Calc 1;
BA_ "U_U55X_MY2022_Tx" SG_ 1113 TrlrAnOffst_An_Calc 1;
BA_ "U_CD764_MY2022_Tx" SG_ 1113 TrlrAnOffst_An_Calc 1;
BA_ "U_T6_MCA_MY2020_Tx" SG_ 1113 TrlrAnOffstDir_D_Calc 1;
BA_ "U_CD542_MY2021_Tx" SG_ 1113 TrlrAnOffstDir_D_Calc 1;
BA_ "U_U55X_MY2022_Tx" SG_ 1113 TrlrAnOffstDir_D_Calc 1;
BA_ "U_CD764_MY2022_Tx" SG_ 1113 TrlrAnOffstDir_D_Calc 1;
BA_ "U_T6_MCA_MY2020_Tx" SG_ 1113 TrlrAnCalib_B_Complt 1;
BA_ "U_CD542_MY2021_Tx" SG_ 1113 TrlrAnCalib_B_Complt 1;
BA_ "U_U55X_MY2022_Tx" SG_ 1113 TrlrAnCalib_B_Complt 1;
BA_ "U_CD764_MY2022_Tx" SG_ 1113 TrlrAnCalib_B_Complt 1;
BA_ "U_P702_MY2021_Rx" SG_ 1113 TrlrRvrse_D_Stat 1;
BA_ "U_T6_MCA_MY2020_Rx" SG_ 1113 TrlrRvrse_D_Stat 1;
BA_ "U_U55X_MY2022_Rx" SG_ 1113 TrlrRvrse_D_Stat 1;
BA_ "U_T6_MCA_MY2020_Tx" SG_ 1113 TrlrRvrse_D_Stat 1;
BA_ "U_CD542_MY2021_Tx" SG_ 1113 TrlrRvrse_D_Stat 1;
BA_ "U_U55X_MY2022_Tx" SG_ 1113 TrlrRvrse_D_Stat 1;
BA_ "U_CD764_MY2022_Tx" SG_ 1113 TrlrRvrse_D_Stat 1;
BA_ "U_P702_MY2021_Rx" SG_ 1113 TrlrAid_D2_Stat 1;
BA_ "U_T6_MCA_MY2020_Rx" SG_ 1113 TrlrAid_D2_Stat 1;
BA_ "U_U55X_MY2022_Rx" SG_ 1113 TrlrAid_D2_Stat 1;
BA_ "U_T6_MCA_MY2020_Tx" SG_ 1113 TrlrAid_D2_Stat 1;
BA_ "U_CD542_MY2021_Tx" SG_ 1113 TrlrAid_D2_Stat 1;
BA_ "U_U55X_MY2022_Tx" SG_ 1113 TrlrAid_D2_Stat 1;
BA_ "U_CD764_MY2022_Tx" SG_ 1113 TrlrAid_D2_Stat 1;
BA_ "U_P702_MY2021_Rx" SG_ 1113 TrlrAidTrgtId_No_Actl 1;
BA_ "U_T6_MCA_MY2020_Rx" SG_ 1113 TrlrAidTrgtId_No_Actl 1;
BA_ "U_U55X_MY2022_Rx" SG_ 1113 TrlrAidTrgtId_No_Actl 1;
BA_ "U_T6_MCA_MY2020_Tx" SG_ 1113 TrlrAidTrgtId_No_Actl 1;
BA_ "U_CD542_MY2021_Tx" SG_ 1113 TrlrAidTrgtId_No_Actl 1;
BA_ "U_U55X_MY2022_Tx" SG_ 1113 TrlrAidTrgtId_No_Actl 1;
BA_ "U_CD764_MY2022_Tx" SG_ 1113 TrlrAidTrgtId_No_Actl 1;
BA_ "GenSigStartValueInteger" SG_ 1113 TrlrAid_An3_Actl 720;
BA_ "U_P702_MY2021_Rx" SG_ 1113 TrlrAid_An3_Actl 1;
BA_ "U_T6_MCA_MY2020_Rx" SG_ 1113 TrlrAid_An3_Actl 1;
BA_ "U_U55X_MY2022_Rx" SG_ 1113 TrlrAid_An3_Actl 1;
BA_ "U_T6_MCA_MY2020_Tx" SG_ 1113 TrlrAid_An3_Actl 1;
BA_ "U_CD542_MY2021_Tx" SG_ 1113 TrlrAid_An3_Actl 1;
BA_ "U_U55X_MY2022_Tx" SG_ 1113 TrlrAid_An3_Actl 1;
BA_ "U_CD764_MY2022_Tx" SG_ 1113 TrlrAid_An3_Actl 1;
BA_ "GenSigStartValueInteger" SG_ 1113 TrlrAid_AnRate2_Actl 400;
BA_ "U_P702_MY2021_Rx" SG_ 1113 TrlrAid_AnRate2_Actl 1;
BA_ "U_T6_MCA_MY2020_Rx" SG_ 1113 TrlrAid_AnRate2_Actl 1;
BA_ "U_U55X_MY2022_Rx" SG_ 1113 TrlrAid_AnRate2_Actl 1;
BA_ "U_T6_MCA_MY2020_Tx" SG_ 1113 TrlrAid_AnRate2_Actl 1;
BA_ "U_CD542_MY2021_Tx" SG_ 1113 TrlrAid_AnRate2_Actl 1;
BA_ "U_U55X_MY2022_Tx" SG_ 1113 TrlrAid_AnRate2_Actl 1;
BA_ "U_CD764_MY2022_Tx" SG_ 1113 TrlrAid_AnRate2_Actl 1;
BA_ "GenSigStartValueInteger" SG_ 1113 HitchToVehAxle_L_Calc 255;
BA_ "GenSigStartValue" SG_ 1113 HitchToVehAxle_L_Calc 255;
BA_ "U_P702_MY2021_Rx" SG_ 1113 HitchToVehAxle_L_Calc 1;
BA_ "U_T6_MCA_MY2020_Rx" SG_ 1113 HitchToVehAxle_L_Calc 1;
BA_ "U_U55X_MY2022_Rx" SG_ 1113 HitchToVehAxle_L_Calc 1;
BA_ "U_T6_MCA_MY2020_Tx" SG_ 1113 HitchToVehAxle_L_Calc 1;
BA_ "U_CD542_MY2021_Tx" SG_ 1113 HitchToVehAxle_L_Calc 1;
BA_ "U_U55X_MY2022_Tx" SG_ 1113 HitchToVehAxle_L_Calc 1;
BA_ "U_CD764_MY2022_Tx" SG_ 1113 HitchToVehAxle_L_Calc 1;
BA_ "U_T6_MCA_MY2020_Tx" SG_ 1113 HitchToTrlrAxle_L_Calc2 1;
BA_ "U_CD542_MY2021_Tx" SG_ 1113 HitchToTrlrAxle_L_Calc2 1;
BA_ "U_U55X_MY2022_Tx" SG_ 1113 HitchToTrlrAxle_L_Calc2 1;
BA_ "U_CD764_MY2022_Tx" SG_ 1113 HitchToTrlrAxle_L_Calc2 1;
BA_ "GenSigSendType" SG_ 1105 ClrExitAsstMsgTxt2_D_Rq 3;
BA_ "U_U55X_MY2022_Tx" SG_ 1105 ClrExitAsstMsgTxt2_D_Rq 1;
BA_ "U_CD764_MY2022_Tx" SG_ 1105 ClrExitAsstMsgTxt2_D_Rq 1;
BA_ "GenSigSendType" SG_ 1105 ClrExitAsstActv_B_Rq 3;
BA_ "U_U55X_MY2022_Tx" SG_ 1105 ClrExitAsstActv_B_Rq 1;
BA_ "U_CD764_MY2022_Tx" SG_ 1105 ClrExitAsstActv_B_Rq 1;
BA_ "GenSigSendType" SG_ 1105 TrlrRvrseMsgTxt_D2_Rq 3;
BA_ "U_P702_MY2021_Rx" SG_ 1105 TrlrRvrseMsgTxt_D2_Rq 1;
BA_ "U_T6_MCA_MY2020_Rx" SG_ 1105 TrlrRvrseMsgTxt_D2_Rq 1;
BA_ "U_U55X_MY2022_Rx" SG_ 1105 TrlrRvrseMsgTxt_D2_Rq 1;
BA_ "U_T6_MCA_MY2020_Tx" SG_ 1105 TrlrRvrseMsgTxt_D2_Rq 1;
BA_ "U_CD542_MY2021_Tx" SG_ 1105 TrlrRvrseMsgTxt_D2_Rq 1;
BA_ "U_U55X_MY2022_Tx" SG_ 1105 TrlrRvrseMsgTxt_D2_Rq 1;
BA_ "U_CD764_MY2022_Tx" SG_ 1105 TrlrRvrseMsgTxt_D2_Rq 1;
BA_ "GenSigSendType" SG_ 1105 TrlrRvrseEnbl_D2_Stat 3;
BA_ "U_P702_MY2021_Rx" SG_ 1105 TrlrRvrseEnbl_D2_Stat 1;
BA_ "U_T6_MCA_MY2020_Rx" SG_ 1105 TrlrRvrseEnbl_D2_Stat 1;
BA_ "U_U55X_MY2022_Rx" SG_ 1105 TrlrRvrseEnbl_D2_Stat 1;
BA_ "U_T6_MCA_MY2020_Tx" SG_ 1105 TrlrRvrseEnbl_D2_Stat 1;
BA_ "U_CD542_MY2021_Tx" SG_ 1105 TrlrRvrseEnbl_D2_Stat 1;
BA_ "U_U55X_MY2022_Tx" SG_ 1105 TrlrRvrseEnbl_D2_Stat 1;
BA_ "U_CD764_MY2022_Tx" SG_ 1105 TrlrRvrseEnbl_D2_Stat 1;
BA_ "GenSigSendType" SG_ 1105 RbaMsg_D_Rq 3;
BA_ "U_T6_MCA_MY2020_Tx" SG_ 1105 RbaMsg_D_Rq 1;
BA_ "U_CD542_MY2021_Tx" SG_ 1105 RbaMsg_D_Rq 1;
BA_ "U_U55X_MY2022_Tx" SG_ 1105 RbaMsg_D_Rq 1;
BA_ "U_CD764_MY2022_Tx" SG_ 1105 RbaMsg_D_Rq 1;
BA_ "GenSigSendType" SG_ 1105 BrkDecel_B_RqRba 3;
BA_ "WakeupSignal" SG_ 1105 BrkDecel_B_RqRba 1;
BA_ "U_P702_MY2021_Rx" SG_ 1105 BrkDecel_B_RqRba 1;
BA_ "U_T6_MCA_MY2020_Rx" SG_ 1105 BrkDecel_B_RqRba 1;
BA_ "U_CD542_MY2021_Rx" SG_ 1105 BrkDecel_B_RqRba 1;
BA_ "U_U55X_MY2022_Rx" SG_ 1105 BrkDecel_B_RqRba 1;
BA_ "U_CD764_MY2022_Rx" SG_ 1105 BrkDecel_B_RqRba 1;
BA_ "U_T6_MCA_MY2020_Tx" SG_ 1105 BrkDecel_B_RqRba 1;
BA_ "U_CD542_MY2021_Tx" SG_ 1105 BrkDecel_B_RqRba 1;
BA_ "U_U55X_MY2022_Tx" SG_ 1105 BrkDecel_B_RqRba 1;
BA_ "U_CD764_MY2022_Tx" SG_ 1105 BrkDecel_B_RqRba 1;
BA_ "GenSigSendType" SG_ 1105 BrkEnbl_B_RqRba 3;
BA_ "WakeupSignal" SG_ 1105 BrkEnbl_B_RqRba 1;
BA_ "U_P702_MY2021_Rx" SG_ 1105 BrkEnbl_B_RqRba 1;
BA_ "U_T6_MCA_MY2020_Rx" SG_ 1105 BrkEnbl_B_RqRba 1;
BA_ "U_CD542_MY2021_Rx" SG_ 1105 BrkEnbl_B_RqRba 1;
BA_ "U_U55X_MY2022_Rx" SG_ 1105 BrkEnbl_B_RqRba 1;
BA_ "U_CD764_MY2022_Rx" SG_ 1105 BrkEnbl_B_RqRba 1;
BA_ "U_T6_MCA_MY2020_Tx" SG_ 1105 BrkEnbl_B_RqRba 1;
BA_ "U_CD542_MY2021_Tx" SG_ 1105 BrkEnbl_B_RqRba 1;
BA_ "U_U55X_MY2022_Tx" SG_ 1105 BrkEnbl_B_RqRba 1;
BA_ "U_CD764_MY2022_Tx" SG_ 1105 BrkEnbl_B_RqRba 1;
BA_ "GenSigSendType" SG_ 1105 Rba_D_Stat 3;
BA_ "GenSigStartValueInteger" SG_ 1105 Rba_D_Stat 1;
BA_ "GenSigStartValue" SG_ 1105 Rba_D_Stat 1;
BA_ "U_T6_MCA_MY2020_Tx" SG_ 1105 Rba_D_Stat 1;
BA_ "U_CD542_MY2021_Tx" SG_ 1105 Rba_D_Stat 1;
BA_ "U_U55X_MY2022_Tx" SG_ 1105 Rba_D_Stat 1;
BA_ "U_CD764_MY2022_Tx" SG_ 1105 Rba_D_Stat 1;
BA_ "GenSigSendType" SG_ 1105 RbaAlrt_D_Dsply 3;
BA_ "U_T6_MCA_MY2020_Tx" SG_ 1105 RbaAlrt_D_Dsply 1;
BA_ "U_CD542_MY2021_Tx" SG_ 1105 RbaAlrt_D_Dsply 1;
BA_ "U_U55X_MY2022_Tx" SG_ 1105 RbaAlrt_D_Dsply 1;
BA_ "U_CD764_MY2022_Tx" SG_ 1105 RbaAlrt_D_Dsply 1;
BA_ "GenSigSendType" SG_ 1105 RbaMnu_D_Rq 3;
BA_ "U_T6_MCA_MY2020_Tx" SG_ 1105 RbaMnu_D_Rq 1;
BA_ "U_CD542_MY2021_Tx" SG_ 1105 RbaMnu_D_Rq 1;
BA_ "U_U55X_MY2022_Tx" SG_ 1105 RbaMnu_D_Rq 1;
BA_ "U_CD764_MY2022_Tx" SG_ 1105 RbaMnu_D_Rq 1;
BA_ "GenSigSendType" SG_ 1105 CamraFrntStat_D_Stat 3;
BA_ "U_T6_MCA_MY2020_Tx" SG_ 1105 CamraFrntStat_D_Stat 1;
BA_ "U_CD542_MY2021_Tx" SG_ 1105 CamraFrntStat_D_Stat 1;
BA_ "U_U55X_MY2022_Tx" SG_ 1105 CamraFrntStat_D_Stat 1;
BA_ "U_CD764_MY2022_Tx" SG_ 1105 CamraFrntStat_D_Stat 1;
BA_ "GenSigSendType" SG_ 1105 TrlrHitchLamp_D_Rq2 3;
BA_ "U_T6_MCA_MY2020_Tx" SG_ 1105 TrlrHitchLamp_D_Rq2 1;
BA_ "U_CD542_MY2021_Tx" SG_ 1105 TrlrHitchLamp_D_Rq2 1;
BA_ "U_U55X_MY2022_Tx" SG_ 1105 TrlrHitchLamp_D_Rq2 1;
BA_ "U_CD764_MY2022_Tx" SG_ 1105 TrlrHitchLamp_D_Rq2 1;
BA_ "GenSigSendType" SG_ 1105 CamraFrntOffRd_B_Stat 3;
BA_ "U_T6_MCA_MY2020_Tx" SG_ 1105 CamraFrntOffRd_B_Stat 1;
BA_ "U_U55X_MY2022_Tx" SG_ 1105 CamraFrntOffRd_B_Stat 1;
BA_ "GenSigSendType" SG_ 1105 TrlrAidSwtchLamp_B_Rq 3;
BA_ "U_T6_MCA_MY2020_Tx" SG_ 1105 TrlrAidSwtchLamp_B_Rq 1;
BA_ "U_CD542_MY2021_Tx" SG_ 1105 TrlrAidSwtchLamp_B_Rq 1;
BA_ "U_U55X_MY2022_Tx" SG_ 1105 TrlrAidSwtchLamp_B_Rq 1;
BA_ "U_CD764_MY2022_Tx" SG_ 1105 TrlrAidSwtchLamp_B_Rq 1;
BA_ "GenSigSendType" SG_ 1105 TrlrAidEnbl_D_RqAdas 3;
BA_ "U_P702_MY2021_Rx" SG_ 1105 TrlrAidEnbl_D_RqAdas 1;
BA_ "U_T6_MCA_MY2020_Rx" SG_ 1105 TrlrAidEnbl_D_RqAdas 1;
BA_ "U_U55X_MY2022_Rx" SG_ 1105 TrlrAidEnbl_D_RqAdas 1;
BA_ "U_T6_MCA_MY2020_Tx" SG_ 1105 TrlrAidEnbl_D_RqAdas 1;
BA_ "U_CD542_MY2021_Tx" SG_ 1105 TrlrAidEnbl_D_RqAdas 1;
BA_ "U_U55X_MY2022_Tx" SG_ 1105 TrlrAidEnbl_D_RqAdas 1;
BA_ "U_CD764_MY2022_Tx" SG_ 1105 TrlrAidEnbl_D_RqAdas 1;
BA_ "GenSigSendType" SG_ 1105 TrlrHitchMsgTxt_D_Rq 3;
BA_ "U_T6_MCA_MY2020_Tx" SG_ 1105 TrlrHitchMsgTxt_D_Rq 1;
BA_ "U_CD542_MY2021_Tx" SG_ 1105 TrlrHitchMsgTxt_D_Rq 1;
BA_ "U_U55X_MY2022_Tx" SG_ 1105 TrlrHitchMsgTxt_D_Rq 1;
BA_ "U_CD764_MY2022_Tx" SG_ 1105 TrlrHitchMsgTxt_D_Rq 1;
BA_ "GenSigSendType" SG_ 1105 TrlrHitchIcon_D_Rq 3;
BA_ "U_T6_MCA_MY2020_Tx" SG_ 1105 TrlrHitchIcon_D_Rq 1;
BA_ "U_CD542_MY2021_Tx" SG_ 1105 TrlrHitchIcon_D_Rq 1;
BA_ "U_U55X_MY2022_Tx" SG_ 1105 TrlrHitchIcon_D_Rq 1;
BA_ "U_CD764_MY2022_Tx" SG_ 1105 TrlrHitchIcon_D_Rq 1;
BA_ "GenSigSendType" SG_ 1105 TrlrHitchChime_D_Rq 3;
BA_ "U_T6_MCA_MY2020_Tx" SG_ 1105 TrlrHitchChime_D_Rq 1;
BA_ "U_CD542_MY2021_Tx" SG_ 1105 TrlrHitchChime_D_Rq 1;
BA_ "U_U55X_MY2022_Tx" SG_ 1105 TrlrHitchChime_D_Rq 1;
BA_ "U_CD764_MY2022_Tx" SG_ 1105 TrlrHitchChime_D_Rq 1;
BA_ "GenSigSendType" SG_ 938 SidePrkSnsR2_D_Stat 3;
BA_ "U_T6_MCA_MY2020_Tx" SG_ 938 SidePrkSnsR2_D_Stat 1;
BA_ "U_CD542_MY2021_Tx" SG_ 938 SidePrkSnsR2_D_Stat 1;
BA_ "U_U55X_MY2022_Tx" SG_ 938 SidePrkSnsR2_D_Stat 1;
BA_ "U_CD764_MY2022_Tx" SG_ 938 SidePrkSnsR2_D_Stat 1;
BA_ "GenSigSendType" SG_ 938 SidePrkSnsR1_D_Stat 3;
BA_ "U_T6_MCA_MY2020_Tx" SG_ 938 SidePrkSnsR1_D_Stat 1;
BA_ "U_CD542_MY2021_Tx" SG_ 938 SidePrkSnsR1_D_Stat 1;
BA_ "U_U55X_MY2022_Tx" SG_ 938 SidePrkSnsR1_D_Stat 1;
BA_ "U_CD764_MY2022_Tx" SG_ 938 SidePrkSnsR1_D_Stat 1;
BA_ "GenSigSendType" SG_ 938 SidePrkSnsL2_D_Stat 3;
BA_ "U_T6_MCA_MY2020_Tx" SG_ 938 SidePrkSnsL2_D_Stat 1;
BA_ "U_CD542_MY2021_Tx" SG_ 938 SidePrkSnsL2_D_Stat 1;
BA_ "U_U55X_MY2022_Tx" SG_ 938 SidePrkSnsL2_D_Stat 1;
BA_ "U_CD764_MY2022_Tx" SG_ 938 SidePrkSnsL2_D_Stat 1;
BA_ "GenSigSendType" SG_ 938 ApaMde_D_Stat 3;
BA_ "U_T6_MCA_MY2020_Tx" SG_ 938 ApaMde_D_Stat 1;
BA_ "U_CD542_MY2021_Tx" SG_ 938 ApaMde_D_Stat 1;
BA_ "U_U55X_MY2022_Tx" SG_ 938 ApaMde_D_Stat 1;
BA_ "U_CD764_MY2022_Tx" SG_ 938 ApaMde_D_Stat 1;
BA_ "GenSigSendType" SG_ 938 ApaActvSd_D_Actl 3;
BA_ "GenSigStartValueInteger" SG_ 938 ApaActvSd_D_Actl 1;
BA_ "GenSigStartValue" SG_ 938 ApaActvSd_D_Actl 1;
BA_ "U_T6_MCA_MY2020_Tx" SG_ 938 ApaActvSd_D_Actl 1;
BA_ "U_CD542_MY2021_Tx" SG_ 938 ApaActvSd_D_Actl 1;
BA_ "U_U55X_MY2022_Tx" SG_ 938 ApaActvSd_D_Actl 1;
BA_ "U_CD764_MY2022_Tx" SG_ 938 ApaActvSd_D_Actl 1;
BA_ "GenSigSendType" SG_ 938 PrkAidSwtch_B_Stat 3;
BA_ "U_T6_MCA_MY2020_Tx" SG_ 938 PrkAidSwtch_B_Stat 1;
BA_ "U_CD542_MY2021_Tx" SG_ 938 PrkAidSwtch_B_Stat 1;
BA_ "U_U55X_MY2022_Tx" SG_ 938 PrkAidSwtch_B_Stat 1;
BA_ "U_CD764_MY2022_Tx" SG_ 938 PrkAidSwtch_B_Stat 1;
BA_ "GenSigSendType" SG_ 938 ApaMde_D_Avail 3;
BA_ "U_T6_MCA_MY2020_Tx" SG_ 938 ApaMde_D_Avail 1;
BA_ "U_CD542_MY2021_Tx" SG_ 938 ApaMde_D_Avail 1;
BA_ "U_U55X_MY2022_Tx" SG_ 938 ApaMde_D_Avail 1;
BA_ "U_CD764_MY2022_Tx" SG_ 938 ApaMde_D_Avail 1;
BA_ "GenSigSendType" SG_ 938 PrkAidSnsFrCrnr_D_Stat 3;
BA_ "U_T6_MCA_MY2020_Tx" SG_ 938 PrkAidSnsFrCrnr_D_Stat 1;
BA_ "U_CD542_MY2021_Tx" SG_ 938 PrkAidSnsFrCrnr_D_Stat 1;
BA_ "U_U55X_MY2022_Tx" SG_ 938 PrkAidSnsFrCrnr_D_Stat 1;
BA_ "U_CD764_MY2022_Tx" SG_ 938 PrkAidSnsFrCrnr_D_Stat 1;
BA_ "GenSigSendType" SG_ 938 PrkAidSnsFrCntr_D_Stat 3;
BA_ "U_T6_MCA_MY2020_Tx" SG_ 938 PrkAidSnsFrCntr_D_Stat 1;
BA_ "U_CD542_MY2021_Tx" SG_ 938 PrkAidSnsFrCntr_D_Stat 1;
BA_ "U_U55X_MY2022_Tx" SG_ 938 PrkAidSnsFrCntr_D_Stat 1;
BA_ "U_CD764_MY2022_Tx" SG_ 938 PrkAidSnsFrCntr_D_Stat 1;
BA_ "GenSigSendType" SG_ 938 PrkAidSnsFlCrnr_D_Stat 3;
BA_ "U_T6_MCA_MY2020_Tx" SG_ 938 PrkAidSnsFlCrnr_D_Stat 1;
BA_ "U_CD542_MY2021_Tx" SG_ 938 PrkAidSnsFlCrnr_D_Stat 1;
BA_ "U_U55X_MY2022_Tx" SG_ 938 PrkAidSnsFlCrnr_D_Stat 1;
BA_ "U_CD764_MY2022_Tx" SG_ 938 PrkAidSnsFlCrnr_D_Stat 1;
BA_ "GenSigSendType" SG_ 938 PrkAidSnsFlCntr_D_Stat 3;
BA_ "U_T6_MCA_MY2020_Tx" SG_ 938 PrkAidSnsFlCntr_D_Stat 1;
BA_ "U_CD542_MY2021_Tx" SG_ 938 PrkAidSnsFlCntr_D_Stat 1;
BA_ "U_U55X_MY2022_Tx" SG_ 938 PrkAidSnsFlCntr_D_Stat 1;
BA_ "U_CD764_MY2022_Tx" SG_ 938 PrkAidSnsFlCntr_D_Stat 1;
BA_ "GenSigSendType" SG_ 938 PrkBrkEl_B_RqFap 3;
BA_ "U_CX727_MY2021_Rx" SG_ 938 PrkBrkEl_B_RqFap 1;
BA_ "U_P702_MY2021_Rx" SG_ 938 PrkBrkEl_B_RqFap 1;
BA_ "U_T6_MCA_MY2020_Rx" SG_ 938 PrkBrkEl_B_RqFap 1;
BA_ "U_CD542_MY2021_Rx" SG_ 938 PrkBrkEl_B_RqFap 1;
BA_ "U_U55X_MY2022_Rx" SG_ 938 PrkBrkEl_B_RqFap 1;
BA_ "U_CD764_MY2022_Rx" SG_ 938 PrkBrkEl_B_RqFap 1;
BA_ "U_T6_MCA_MY2020_Tx" SG_ 938 PrkBrkEl_B_RqFap 1;
BA_ "U_CD542_MY2021_Tx" SG_ 938 PrkBrkEl_B_RqFap 1;
BA_ "U_U55X_MY2022_Tx" SG_ 938 PrkBrkEl_B_RqFap 1;
BA_ "U_CD764_MY2022_Tx" SG_ 938 PrkBrkEl_B_RqFap 1;
BA_ "GenSigSendType" SG_ 938 RpaChime_D_Rq 3;
BA_ "U_T6_MCA_MY2020_Tx" SG_ 938 RpaChime_D_Rq 1;
BA_ "U_CD542_MY2021_Tx" SG_ 938 RpaChime_D_Rq 1;
BA_ "U_U55X_MY2022_Tx" SG_ 938 RpaChime_D_Rq 1;
BA_ "U_CD764_MY2022_Tx" SG_ 938 RpaChime_D_Rq 1;
BA_ "GenSigSendType" SG_ 938 FpaChime_D_Rq 3;
BA_ "U_T6_MCA_MY2020_Tx" SG_ 938 FpaChime_D_Rq 1;
BA_ "U_CD542_MY2021_Tx" SG_ 938 FpaChime_D_Rq 1;
BA_ "U_U55X_MY2022_Tx" SG_ 938 FpaChime_D_Rq 1;
BA_ "U_CD764_MY2022_Tx" SG_ 938 FpaChime_D_Rq 1;
BA_ "GenSigSendType" SG_ 938 PrkAidMsgTxt_D_Rq 3;
BA_ "U_P702_MY2021_Rx" SG_ 938 PrkAidMsgTxt_D_Rq 1;
BA_ "U_T6_MCA_MY2020_Rx" SG_ 938 PrkAidMsgTxt_D_Rq 1;
BA_ "U_U55X_MY2022_Rx" SG_ 938 PrkAidMsgTxt_D_Rq 1;
BA_ "U_T6_MCA_MY2020_Tx" SG_ 938 PrkAidMsgTxt_D_Rq 1;
BA_ "U_CD542_MY2021_Tx" SG_ 938 PrkAidMsgTxt_D_Rq 1;
BA_ "U_U55X_MY2022_Tx" SG_ 938 PrkAidMsgTxt_D_Rq 1;
BA_ "U_CD764_MY2022_Tx" SG_ 938 PrkAidMsgTxt_D_Rq 1;
BA_ "GenSigSendType" SG_ 938 SidePrkSnsL1_D_Stat 3;
BA_ "U_T6_MCA_MY2020_Tx" SG_ 938 SidePrkSnsL1_D_Stat 1;
BA_ "U_CD542_MY2021_Tx" SG_ 938 SidePrkSnsL1_D_Stat 1;
BA_ "U_U55X_MY2022_Tx" SG_ 938 SidePrkSnsL1_D_Stat 1;
BA_ "U_CD764_MY2022_Tx" SG_ 938 SidePrkSnsL1_D_Stat 1;
BA_ "GenSigSendType" SG_ 938 PrkAidAudioMute_B_Rq 3;
BA_ "U_T6_MCA_MY2020_Tx" SG_ 938 PrkAidAudioMute_B_Rq 1;
BA_ "U_CD542_MY2021_Tx" SG_ 938 PrkAidAudioMute_B_Rq 1;
BA_ "U_U55X_MY2022_Tx" SG_ 938 PrkAidAudioMute_B_Rq 1;
BA_ "U_CD764_MY2022_Tx" SG_ 938 PrkAidAudioMute_B_Rq 1;
BA_ "GenSigSendType" SG_ 939 SidePrkSnsR4_D_Stat 3;
BA_ "U_T6_MCA_MY2020_Tx" SG_ 939 SidePrkSnsR4_D_Stat 1;
BA_ "U_CD542_MY2021_Tx" SG_ 939 SidePrkSnsR4_D_Stat 1;
BA_ "U_U55X_MY2022_Tx" SG_ 939 SidePrkSnsR4_D_Stat 1;
BA_ "U_CD764_MY2022_Tx" SG_ 939 SidePrkSnsR4_D_Stat 1;
BA_ "GenSigSendType" SG_ 939 SidePrkSnsR3_D_Stat 3;
BA_ "U_T6_MCA_MY2020_Tx" SG_ 939 SidePrkSnsR3_D_Stat 1;
BA_ "U_CD542_MY2021_Tx" SG_ 939 SidePrkSnsR3_D_Stat 1;
BA_ "U_U55X_MY2022_Tx" SG_ 939 SidePrkSnsR3_D_Stat 1;
BA_ "U_CD764_MY2022_Tx" SG_ 939 SidePrkSnsR3_D_Stat 1;
BA_ "GenSigSendType" SG_ 939 SidePrkSnsL4_D_Stat 3;
BA_ "U_T6_MCA_MY2020_Tx" SG_ 939 SidePrkSnsL4_D_Stat 1;
BA_ "U_CD542_MY2021_Tx" SG_ 939 SidePrkSnsL4_D_Stat 1;
BA_ "U_U55X_MY2022_Tx" SG_ 939 SidePrkSnsL4_D_Stat 1;
BA_ "U_CD764_MY2022_Tx" SG_ 939 SidePrkSnsL4_D_Stat 1;
BA_ "GenSigSendType" SG_ 939 SidePrkSnsL3_D_Stat 3;
BA_ "U_T6_MCA_MY2020_Tx" SG_ 939 SidePrkSnsL3_D_Stat 1;
BA_ "U_CD542_MY2021_Tx" SG_ 939 SidePrkSnsL3_D_Stat 1;
BA_ "U_U55X_MY2022_Tx" SG_ 939 SidePrkSnsL3_D_Stat 1;
BA_ "U_CD764_MY2022_Tx" SG_ 939 SidePrkSnsL3_D_Stat 1;
BA_ "GenSigSendType" SG_ 939 PrkAidChime_D_Stat 3;
BA_ "U_T6_MCA_MY2020_Tx" SG_ 939 PrkAidChime_D_Stat 1;
BA_ "U_CD542_MY2021_Tx" SG_ 939 PrkAidChime_D_Stat 1;
BA_ "U_U55X_MY2022_Tx" SG_ 939 PrkAidChime_D_Stat 1;
BA_ "U_CD764_MY2022_Tx" SG_ 939 PrkAidChime_D_Stat 1;
BA_ "GenSigSendType" SG_ 939 PrkAidSnsRlCntr_D_Stat 3;
BA_ "U_T6_MCA_MY2020_Tx" SG_ 939 PrkAidSnsRlCntr_D_Stat 1;
BA_ "U_CD542_MY2021_Tx" SG_ 939 PrkAidSnsRlCntr_D_Stat 1;
BA_ "U_U55X_MY2022_Tx" SG_ 939 PrkAidSnsRlCntr_D_Stat 1;
BA_ "U_CD764_MY2022_Tx" SG_ 939 PrkAidSnsRlCntr_D_Stat 1;
BA_ "GenSigSendType" SG_ 939 PrkAidSnsRrCrnr_D_Stat 3;
BA_ "U_T6_MCA_MY2020_Tx" SG_ 939 PrkAidSnsRrCrnr_D_Stat 1;
BA_ "U_CD542_MY2021_Tx" SG_ 939 PrkAidSnsRrCrnr_D_Stat 1;
BA_ "U_U55X_MY2022_Tx" SG_ 939 PrkAidSnsRrCrnr_D_Stat 1;
BA_ "U_CD764_MY2022_Tx" SG_ 939 PrkAidSnsRrCrnr_D_Stat 1;
BA_ "GenSigSendType" SG_ 939 PrkAidSnsRrCntr_D_Stat 3;
BA_ "U_T6_MCA_MY2020_Tx" SG_ 939 PrkAidSnsRrCntr_D_Stat 1;
BA_ "U_CD542_MY2021_Tx" SG_ 939 PrkAidSnsRrCntr_D_Stat 1;
BA_ "U_U55X_MY2022_Tx" SG_ 939 PrkAidSnsRrCntr_D_Stat 1;
BA_ "U_CD764_MY2022_Tx" SG_ 939 PrkAidSnsRrCntr_D_Stat 1;
BA_ "GenSigSendType" SG_ 939 PrkAidSnsRlCrnr_D_Stat 3;
BA_ "U_T6_MCA_MY2020_Tx" SG_ 939 PrkAidSnsRlCrnr_D_Stat 1;
BA_ "U_CD542_MY2021_Tx" SG_ 939 PrkAidSnsRlCrnr_D_Stat 1;
BA_ "U_U55X_MY2022_Tx" SG_ 939 PrkAidSnsRlCrnr_D_Stat 1;
BA_ "U_CD764_MY2022_Tx" SG_ 939 PrkAidSnsRlCrnr_D_Stat 1;
BA_ "GenSigSendType" SG_ 939 PrkAidRear_D_Stat 3;
BA_ "U_T6_MCA_MY2020_Tx" SG_ 939 PrkAidRear_D_Stat 1;
BA_ "U_CD542_MY2021_Tx" SG_ 939 PrkAidRear_D_Stat 1;
BA_ "U_U55X_MY2022_Tx" SG_ 939 PrkAidRear_D_Stat 1;
BA_ "U_CD764_MY2022_Tx" SG_ 939 PrkAidRear_D_Stat 1;
BA_ "GenSigSendType" SG_ 939 PrkAidFront_D_Stat 3;
BA_ "U_T6_MCA_MY2020_Tx" SG_ 939 PrkAidFront_D_Stat 1;
BA_ "U_CD542_MY2021_Tx" SG_ 939 PrkAidFront_D_Stat 1;
BA_ "U_U55X_MY2022_Tx" SG_ 939 PrkAidFront_D_Stat 1;
BA_ "U_CD764_MY2022_Tx" SG_ 939 PrkAidFront_D_Stat 1;
BA_ "GenSigSendType" SG_ 939 PrkAid_D_Falt 3;
BA_ "U_T6_MCA_MY2020_Tx" SG_ 939 PrkAid_D_Falt 1;
BA_ "U_CD542_MY2021_Tx" SG_ 939 PrkAid_D_Falt 1;
BA_ "U_U55X_MY2022_Tx" SG_ 939 PrkAid_D_Falt 1;
BA_ "U_CD764_MY2022_Tx" SG_ 939 PrkAid_D_Falt 1;
BA_ "GenSigSendType" SG_ 939 ApaLongCtrlEnbl_D_Rq 3;
BA_ "U_CX727_MY2021_Rx" SG_ 939 ApaLongCtrlEnbl_D_Rq 1;
BA_ "U_P702_MY2021_Rx" SG_ 939 ApaLongCtrlEnbl_D_Rq 1;
BA_ "U_T6_MCA_MY2020_Rx" SG_ 939 ApaLongCtrlEnbl_D_Rq 1;
BA_ "U_CD542_MY2021_Rx" SG_ 939 ApaLongCtrlEnbl_D_Rq 1;
BA_ "U_U55X_MY2022_Rx" SG_ 939 ApaLongCtrlEnbl_D_Rq 1;
BA_ "U_CD764_MY2022_Rx" SG_ 939 ApaLongCtrlEnbl_D_Rq 1;
BA_ "U_T6_MCA_MY2020_Tx" SG_ 939 ApaLongCtrlEnbl_D_Rq 1;
BA_ "U_CD542_MY2021_Tx" SG_ 939 ApaLongCtrlEnbl_D_Rq 1;
BA_ "U_U55X_MY2022_Tx" SG_ 939 ApaLongCtrlEnbl_D_Rq 1;
BA_ "U_CD764_MY2022_Tx" SG_ 939 ApaLongCtrlEnbl_D_Rq 1;
BA_ "GenSigStartValueInteger" SG_ 939 ApaBrk_A_Rq 255;
BA_ "GenSigStartValue" SG_ 939 ApaBrk_A_Rq 255;
BA_ "U_CX727_MY2021_Rx" SG_ 939 ApaBrk_A_Rq 1;
BA_ "U_P702_MY2021_Rx" SG_ 939 ApaBrk_A_Rq 1;
BA_ "U_T6_MCA_MY2020_Rx" SG_ 939 ApaBrk_A_Rq 1;
BA_ "U_CD542_MY2021_Rx" SG_ 939 ApaBrk_A_Rq 1;
BA_ "U_U55X_MY2022_Rx" SG_ 939 ApaBrk_A_Rq 1;
BA_ "U_CD764_MY2022_Rx" SG_ 939 ApaBrk_A_Rq 1;
BA_ "U_T6_MCA_MY2020_Tx" SG_ 939 ApaBrk_A_Rq 1;
BA_ "U_CD542_MY2021_Tx" SG_ 939 ApaBrk_A_Rq 1;
BA_ "U_U55X_MY2022_Tx" SG_ 939 ApaBrk_A_Rq 1;
BA_ "U_CD764_MY2022_Tx" SG_ 939 ApaBrk_A_Rq 1;
BA_ "GenSigSendType" SG_ 939 PrkAidLamp_D_Rq 3;
BA_ "U_T6_MCA_MY2020_Tx" SG_ 939 PrkAidLamp_D_Rq 1;
BA_ "U_CD542_MY2021_Tx" SG_ 939 PrkAidLamp_D_Rq 1;
BA_ "U_U55X_MY2022_Tx" SG_ 939 PrkAidLamp_D_Rq 1;
BA_ "U_CD764_MY2022_Tx" SG_ 939 PrkAidLamp_D_Rq 1;
BA_ "GenSigSendType" SG_ 939 ApaBrk_D_Rq 3;
BA_ "U_T6_MCA_MY2020_Tx" SG_ 939 ApaBrk_D_Rq 1;
BA_ "U_CD542_MY2021_Tx" SG_ 939 ApaBrk_D_Rq 1;
BA_ "U_U55X_MY2022_Tx" SG_ 939 ApaBrk_D_Rq 1;
BA_ "U_CD764_MY2022_Tx" SG_ 939 ApaBrk_D_Rq 1;
BA_ "U_CX727_MY2021_Rx" SG_ 937 Veh_V_RqFap 1;
BA_ "U_P702_MY2021_Rx" SG_ 937 Veh_V_RqFap 1;
BA_ "U_T6_MCA_MY2020_Rx" SG_ 937 Veh_V_RqFap 1;
BA_ "U_CD542_MY2021_Rx" SG_ 937 Veh_V_RqFap 1;
BA_ "U_CD764_MY2022_Rx" SG_ 937 Veh_V_RqFap 1;
BA_ "U_T6_MCA_MY2020_Tx" SG_ 937 Veh_V_RqFap 1;
BA_ "U_CD542_MY2021_Tx" SG_ 937 Veh_V_RqFap 1;
BA_ "U_U55X_MY2022_Tx" SG_ 937 Veh_V_RqFap 1;
BA_ "U_CD764_MY2022_Tx" SG_ 937 Veh_V_RqFap 1;
BA_ "MetaData" SG_ 937 TrnRngDRqFap_No_Cs 1;
BA_ "U_CX727_MY2021_Rx" SG_ 937 TrnRngDRqFap_No_Cs 1;
BA_ "U_P702_MY2021_Rx" SG_ 937 TrnRngDRqFap_No_Cs 1;
BA_ "U_T6_MCA_MY2020_Rx" SG_ 937 TrnRngDRqFap_No_Cs 1;
BA_ "U_CD542_MY2021_Rx" SG_ 937 TrnRngDRqFap_No_Cs 1;
BA_ "U_CD764_MY2022_Rx" SG_ 937 TrnRngDRqFap_No_Cs 1;
BA_ "U_T6_MCA_MY2020_Tx" SG_ 937 TrnRngDRqFap_No_Cs 1;
BA_ "U_CD542_MY2021_Tx" SG_ 937 TrnRngDRqFap_No_Cs 1;
BA_ "U_U55X_MY2022_Tx" SG_ 937 TrnRngDRqFap_No_Cs 1;
BA_ "U_CD764_MY2022_Tx" SG_ 937 TrnRngDRqFap_No_Cs 1;
BA_ "MetaData" SG_ 937 TrnRngDRqFap_No_Cnt 1;
BA_ "U_CX727_MY2021_Rx" SG_ 937 TrnRngDRqFap_No_Cnt 1;
BA_ "U_P702_MY2021_Rx" SG_ 937 TrnRngDRqFap_No_Cnt 1;
BA_ "U_T6_MCA_MY2020_Rx" SG_ 937 TrnRngDRqFap_No_Cnt 1;
BA_ "U_CD542_MY2021_Rx" SG_ 937 TrnRngDRqFap_No_Cnt 1;
BA_ "U_CD764_MY2022_Rx" SG_ 937 TrnRngDRqFap_No_Cnt 1;
BA_ "U_T6_MCA_MY2020_Tx" SG_ 937 TrnRngDRqFap_No_Cnt 1;
BA_ "U_CD542_MY2021_Tx" SG_ 937 TrnRngDRqFap_No_Cnt 1;
BA_ "U_U55X_MY2022_Tx" SG_ 937 TrnRngDRqFap_No_Cnt 1;
BA_ "U_CD764_MY2022_Tx" SG_ 937 TrnRngDRqFap_No_Cnt 1;
BA_ "U_CX727_MY2021_Rx" SG_ 937 TrnRng_D_RqFap 1;
BA_ "U_P702_MY2021_Rx" SG_ 937 TrnRng_D_RqFap 1;
BA_ "U_T6_MCA_MY2020_Rx" SG_ 937 TrnRng_D_RqFap 1;
BA_ "U_CD542_MY2021_Rx" SG_ 937 TrnRng_D_RqFap 1;
BA_ "U_CD764_MY2022_Rx" SG_ 937 TrnRng_D_RqFap 1;
BA_ "U_T6_MCA_MY2020_Tx" SG_ 937 TrnRng_D_RqFap 1;
BA_ "U_CD542_MY2021_Tx" SG_ 937 TrnRng_D_RqFap 1;
BA_ "U_U55X_MY2022_Tx" SG_ 937 TrnRng_D_RqFap 1;
BA_ "U_CD764_MY2022_Tx" SG_ 937 TrnRng_D_RqFap 1;
BA_ "GenSigStartValueInteger" SG_ 937 FapLcDistToObj_L_Actl 254;
BA_ "GenSigStartValue" SG_ 937 FapLcDistToObj_L_Actl 254;
BA_ "U_CX727_MY2021_Rx" SG_ 937 FapLcDistToObj_L_Actl 1;
BA_ "U_P702_MY2021_Rx" SG_ 937 FapLcDistToObj_L_Actl 1;
BA_ "U_T6_MCA_MY2020_Rx" SG_ 937 FapLcDistToObj_L_Actl 1;
BA_ "U_CD542_MY2021_Rx" SG_ 937 FapLcDistToObj_L_Actl 1;
BA_ "U_CD764_MY2022_Rx" SG_ 937 FapLcDistToObj_L_Actl 1;
BA_ "U_T6_MCA_MY2020_Tx" SG_ 937 FapLcDistToObj_L_Actl 1;
BA_ "U_CD542_MY2021_Tx" SG_ 937 FapLcDistToObj_L_Actl 1;
BA_ "U_U55X_MY2022_Tx" SG_ 937 FapLcDistToObj_L_Actl 1;
BA_ "U_CD764_MY2022_Tx" SG_ 937 FapLcDistToObj_L_Actl 1;
BA_ "U_CX727_MY2021_Rx" SG_ 936 ApaSys_D_Stat 1;
BA_ "U_P702_MY2021_Rx" SG_ 936 ApaSys_D_Stat 1;
BA_ "U_T6_MCA_MY2020_Rx" SG_ 936 ApaSys_D_Stat 1;
BA_ "U_CD542_MY2021_Rx" SG_ 936 ApaSys_D_Stat 1;
BA_ "U_U55X_MY2022_Rx" SG_ 936 ApaSys_D_Stat 1;
BA_ "U_CD764_MY2022_Rx" SG_ 936 ApaSys_D_Stat 1;
BA_ "U_T6_MCA_MY2020_Tx" SG_ 936 ApaSys_D_Stat 1;
BA_ "U_CD542_MY2021_Tx" SG_ 936 ApaSys_D_Stat 1;
BA_ "U_U55X_MY2022_Tx" SG_ 936 ApaSys_D_Stat 1;
BA_ "U_CD764_MY2022_Tx" SG_ 936 ApaSys_D_Stat 1;
BA_ "U_T6_MCA_MY2020_Tx" SG_ 936 ApaSteWhl_D_RqDrv 1;
BA_ "U_CD542_MY2021_Tx" SG_ 936 ApaSteWhl_D_RqDrv 1;
BA_ "U_U55X_MY2022_Tx" SG_ 936 ApaSteWhl_D_RqDrv 1;
BA_ "U_CD764_MY2022_Tx" SG_ 936 ApaSteWhl_D_RqDrv 1;
BA_ "U_T6_MCA_MY2020_Tx" SG_ 936 ApaSteScanMde_D_Stat 1;
BA_ "U_CD542_MY2021_Tx" SG_ 936 ApaSteScanMde_D_Stat 1;
BA_ "U_U55X_MY2022_Tx" SG_ 936 ApaSteScanMde_D_Stat 1;
BA_ "U_CD764_MY2022_Tx" SG_ 936 ApaSteScanMde_D_Stat 1;
BA_ "U_T6_MCA_MY2020_Tx" SG_ 936 ApaSelSapp_D_Stat 1;
BA_ "U_CD542_MY2021_Tx" SG_ 936 ApaSelSapp_D_Stat 1;
BA_ "U_U55X_MY2022_Tx" SG_ 936 ApaSelSapp_D_Stat 1;
BA_ "U_CD764_MY2022_Tx" SG_ 936 ApaSelSapp_D_Stat 1;
BA_ "U_T6_MCA_MY2020_Tx" SG_ 936 ApaSelPpa_D_Stat 1;
BA_ "U_CD542_MY2021_Tx" SG_ 936 ApaSelPpa_D_Stat 1;
BA_ "U_U55X_MY2022_Tx" SG_ 936 ApaSelPpa_D_Stat 1;
BA_ "U_CD764_MY2022_Tx" SG_ 936 ApaSelPpa_D_Stat 1;
BA_ "U_T6_MCA_MY2020_Tx" SG_ 936 ApaSelPoa_D_Stat 1;
BA_ "U_CD542_MY2021_Tx" SG_ 936 ApaSelPoa_D_Stat 1;
BA_ "U_U55X_MY2022_Tx" SG_ 936 ApaSelPoa_D_Stat 1;
BA_ "U_CD764_MY2022_Tx" SG_ 936 ApaSelPoa_D_Stat 1;
BA_ "U_T6_MCA_MY2020_Tx" SG_ 936 ApaScan_D_Stat 1;
BA_ "U_CD542_MY2021_Tx" SG_ 936 ApaScan_D_Stat 1;
BA_ "U_U55X_MY2022_Tx" SG_ 936 ApaScan_D_Stat 1;
BA_ "U_CD764_MY2022_Tx" SG_ 936 ApaScan_D_Stat 1;
BA_ "U_T6_MCA_MY2020_Tx" SG_ 936 ApaLongCtl_D_RqDrv 1;
BA_ "U_CD542_MY2021_Tx" SG_ 936 ApaLongCtl_D_RqDrv 1;
BA_ "U_U55X_MY2022_Tx" SG_ 936 ApaLongCtl_D_RqDrv 1;
BA_ "U_CD764_MY2022_Tx" SG_ 936 ApaLongCtl_D_RqDrv 1;
BA_ "U_T6_MCA_MY2020_Tx" SG_ 936 ApaGearShif_D_RqDrv 1;
BA_ "U_CD542_MY2021_Tx" SG_ 936 ApaGearShif_D_RqDrv 1;
BA_ "U_U55X_MY2022_Tx" SG_ 936 ApaGearShif_D_RqDrv 1;
BA_ "U_CD764_MY2022_Tx" SG_ 936 ApaGearShif_D_RqDrv 1;
BA_ "U_T6_MCA_MY2020_Tx" SG_ 936 ApaActvSide2_D_Stat 1;
BA_ "U_CD542_MY2021_Tx" SG_ 936 ApaActvSide2_D_Stat 1;
BA_ "U_U55X_MY2022_Tx" SG_ 936 ApaActvSide2_D_Stat 1;
BA_ "U_CD764_MY2022_Tx" SG_ 936 ApaActvSide2_D_Stat 1;
BA_ "U_T6_MCA_MY2020_Tx" SG_ 936 ApaAcsy_D_RqDrv 1;
BA_ "U_CD542_MY2021_Tx" SG_ 936 ApaAcsy_D_RqDrv 1;
BA_ "U_U55X_MY2022_Tx" SG_ 936 ApaAcsy_D_RqDrv 1;
BA_ "U_CD764_MY2022_Tx" SG_ 936 ApaAcsy_D_RqDrv 1;
BA_ "U_T6_MCA_MY2020_Tx" SG_ 936 ApaTrgtDist_D_Stat 1;
BA_ "U_CD542_MY2021_Tx" SG_ 936 ApaTrgtDist_D_Stat 1;
BA_ "U_U55X_MY2022_Tx" SG_ 936 ApaTrgtDist_D_Stat 1;
BA_ "U_CD764_MY2022_Tx" SG_ 936 ApaTrgtDist_D_Stat 1;
BA_ "U_T6_MCA_MY2020_Tx" SG_ 936 ApaMsgTxt_D_Rq 1;
BA_ "U_CD542_MY2021_Tx" SG_ 936 ApaMsgTxt_D_Rq 1;
BA_ "U_U55X_MY2022_Tx" SG_ 936 ApaMsgTxt_D_Rq 1;
BA_ "U_CD764_MY2022_Tx" SG_ 936 ApaMsgTxt_D_Rq 1;
BA_ "U_T6_MCA_MY2020_Tx" SG_ 936 ApaChime_D_Rq 1;
BA_ "U_CD542_MY2021_Tx" SG_ 936 ApaChime_D_Rq 1;
BA_ "U_U55X_MY2022_Tx" SG_ 936 ApaChime_D_Rq 1;
BA_ "U_CD764_MY2022_Tx" SG_ 936 ApaChime_D_Rq 1;
BA_ "U_T6_MCA_MY2020_Tx" SG_ 936 SAPPStatusCoding 1;
BA_ "U_CD542_MY2021_Tx" SG_ 936 SAPPStatusCoding 1;
BA_ "U_U55X_MY2022_Tx" SG_ 936 SAPPStatusCoding 1;
BA_ "U_CD764_MY2022_Tx" SG_ 936 SAPPStatusCoding 1;
BA_ "U_CX727_MY2021_Rx" SG_ 936 EPASExtAngleStatReq 1;
BA_ "U_P702_MY2021_Rx" SG_ 936 EPASExtAngleStatReq 1;
BA_ "U_T6_MCA_MY2020_Rx" SG_ 936 EPASExtAngleStatReq 1;
BA_ "U_CD542_MY2021_Rx" SG_ 936 EPASExtAngleStatReq 1;
BA_ "U_U55X_MY2022_Rx" SG_ 936 EPASExtAngleStatReq 1;
BA_ "U_CD764_MY2022_Rx" SG_ 936 EPASExtAngleStatReq 1;
BA_ "U_T6_MCA_MY2020_Tx" SG_ 936 EPASExtAngleStatReq 1;
BA_ "U_CD542_MY2021_Tx" SG_ 936 EPASExtAngleStatReq 1;
BA_ "U_U55X_MY2022_Tx" SG_ 936 EPASExtAngleStatReq 1;
BA_ "U_CD764_MY2022_Tx" SG_ 936 EPASExtAngleStatReq 1;
BA_ "U_CX727_MY2021_Rx" SG_ 936 ExtSteeringAngleReq2 1;
BA_ "U_P702_MY2021_Rx" SG_ 936 ExtSteeringAngleReq2 1;
BA_ "U_T6_MCA_MY2020_Rx" SG_ 936 ExtSteeringAngleReq2 1;
BA_ "U_CD542_MY2021_Rx" SG_ 936 ExtSteeringAngleReq2 1;
BA_ "U_U55X_MY2022_Rx" SG_ 936 ExtSteeringAngleReq2 1;
BA_ "U_CD764_MY2022_Rx" SG_ 936 ExtSteeringAngleReq2 1;
BA_ "U_T6_MCA_MY2020_Tx" SG_ 936 ExtSteeringAngleReq2 1;
BA_ "U_CD542_MY2021_Tx" SG_ 936 ExtSteeringAngleReq2 1;
BA_ "U_U55X_MY2022_Tx" SG_ 936 ExtSteeringAngleReq2 1;
BA_ "U_CD764_MY2022_Tx" SG_ 936 ExtSteeringAngleReq2 1;
BA_ "U_T6_MCA_MY2020_Tx" SG_ 936 ApaButtnPrssd_B_Stat 1;
BA_ "U_U55X_MY2022_Tx" SG_ 936 ApaButtnPrssd_B_Stat 1;
BA_ "GenSigStartValueInteger" SG_ 877 RngImpctDrv_L_Dsply 255;
BA_ "U_CX727_MY2021_Tx" SG_ 877 RngImpctDrv_L_Dsply 1;
BA_ "U_P702_MY2021_Tx" SG_ 877 RngImpctDrv_L_Dsply 1;
BA_ "U_CD542_MY2021_Tx" SG_ 877 RngImpctDrv_L_Dsply 1;
BA_ "GenSigStartValueInteger" SG_ 877 RngImpctClim_L_Dsply 255;
BA_ "U_CX727_MY2021_Tx" SG_ 877 RngImpctClim_L_Dsply 1;
BA_ "U_P702_MY2021_Tx" SG_ 877 RngImpctClim_L_Dsply 1;
BA_ "U_CD542_MY2021_Tx" SG_ 877 RngImpctClim_L_Dsply 1;
BA_ "GenSigStartValueInteger" SG_ 877 VehElEffAvg_No_Dsply 126;
BA_ "GenSigStartValue" SG_ 877 VehElEffAvg_No_Dsply 126;
BA_ "ECGUsedRxSignal" SG_ 877 VehElEffAvg_No_Dsply 1;
BA_ "U_CX727_MY2021_Tx" SG_ 877 VehElEffAvg_No_Dsply 1;
BA_ "U_P702_MY2021_Tx" SG_ 877 VehElEffAvg_No_Dsply 1;
BA_ "U_CD542_MY2021_Tx" SG_ 877 VehElEffAvg_No_Dsply 1;
BA_ "GenSigSendType" SG_ 877 PwFlwFuelDrv_D_Dsply 3;
BA_ "U_CX727_MY2021_Tx" SG_ 877 PwFlwFuelDrv_D_Dsply 1;
BA_ "U_P702_MY2021_Tx" SG_ 877 PwFlwFuelDrv_D_Dsply 1;
BA_ "U_CD542_MY2021_Tx" SG_ 877 PwFlwFuelDrv_D_Dsply 1;
BA_ "GenSigSendType" SG_ 877 PwFlwFuelClimt_B_Dsply 3;
BA_ "U_P702_MY2021_Tx" SG_ 877 PwFlwFuelClimt_B_Dsply 1;
BA_ "U_CD542_MY2021_Tx" SG_ 877 PwFlwFuelClimt_B_Dsply 1;
BA_ "GenSigSendType" SG_ 877 PwFlwFuelBatt_B_Dsply 3;
BA_ "U_CX727_MY2021_Tx" SG_ 877 PwFlwFuelBatt_B_Dsply 1;
BA_ "U_P702_MY2021_Tx" SG_ 877 PwFlwFuelBatt_B_Dsply 1;
BA_ "U_CD542_MY2021_Tx" SG_ 877 PwFlwFuelBatt_B_Dsply 1;
BA_ "GenSigSendType" SG_ 877 PwFlwBattGen_D_Dsply 3;
BA_ "U_CX727_MY2021_Tx" SG_ 877 PwFlwBattGen_D_Dsply 1;
BA_ "U_P702_MY2021_Tx" SG_ 877 PwFlwBattGen_D_Dsply 1;
BA_ "U_CD542_MY2021_Tx" SG_ 877 PwFlwBattGen_D_Dsply 1;
BA_ "GenSigSendType" SG_ 877 PwFlwBattClimt_B_Dsply 3;
BA_ "U_CX727_MY2021_Tx" SG_ 877 PwFlwBattClimt_B_Dsply 1;
BA_ "U_P702_MY2021_Tx" SG_ 877 PwFlwBattClimt_B_Dsply 1;
BA_ "U_CD542_MY2021_Tx" SG_ 877 PwFlwBattClimt_B_Dsply 1;
BA_ "GenSigSendType" SG_ 877 PwFlwBatt_D_Dsply 3;
BA_ "U_CX727_MY2021_Tx" SG_ 877 PwFlwBatt_D_Dsply 1;
BA_ "U_P702_MY2021_Tx" SG_ 877 PwFlwBatt_D_Dsply 1;
BA_ "U_CD542_MY2021_Tx" SG_ 877 PwFlwBatt_D_Dsply 1;
BA_ "GenSigStartValueInteger" SG_ 791 StopStrtVThres_D_RqMnu 1;
BA_ "GenSigStartValue" SG_ 791 StopStrtVThres_D_RqMnu 1;
BA_ "U_P702_MY2021_Rx" SG_ 791 EngAirFilt_B_RqReset 1;
BA_ "GenSigStartValueInteger" SG_ 791 BattElEmotive_Pc_Dsply 1022;
BA_ "GenSigStartValue" SG_ 791 BattElEmotive_Pc_Dsply 1022;
BA_ "U_CX727_MY2021_Rx" SG_ 791 HybMdeOvrrd_D_Rq 1;
BA_ "U_CD542_MY2021_Rx" SG_ 791 HybMdeOvrrd_D_Rq 1;
BA_ "U_CX727_MY2021_Rx" SG_ 791 GpsElMdeSel_B_Rq 1;
BA_ "U_CD542_MY2021_Rx" SG_ 791 GpsElMdeSel_B_Rq 1;
BA_ "U_CX727_MY2021_Rx" SG_ 791 LongTermReset_B_Rq 1;
BA_ "U_CD542_MY2021_Rx" SG_ 791 LongTermReset_B_Rq 1;
BA_ "U_CX727_MY2021_Rx" SG_ 791 DrvEffLvl_No_Stat 1;
BA_ "U_CD542_MY2021_Rx" SG_ 791 DrvEffLvl_No_Stat 1;
BA_ "WakeupSignal" SG_ 791 ChargeProfIDPref_Rq 1;
BA_ "U_CX727_MY2021_Rx" SG_ 791 GrdAsstAllw_D_RqMnu 1;
BA_ "U_CD542_MY2021_Rx" SG_ 791 GrdAsstAllw_D_RqMnu 1;
BA_ "U_CX727_MY2021_Rx" SG_ 791 PlgOvrrdStrt_D_Cmd 1;
BA_ "U_CD542_MY2021_Rx" SG_ 791 PlgOvrrdStrt_D_Cmd 1;
BA_ "GenSigStartValueInteger" SG_ 791 EcoMde_D_RqMnu 1;
BA_ "GenSigStartValue" SG_ 791 EcoMde_D_RqMnu 1;
BA_ "U_CX727_MY2021_Rx" SG_ 791 EcoMde_D_RqMnu 1;
BA_ "U_CD542_MY2021_Rx" SG_ 791 EcoMde_D_RqMnu 1;
BA_ "GenSigStartValue" SG_ 786 VehElRnge_L2_Dsply 8191;
BA_ "ECGUsedRxSignal" SG_ 786 VehElRnge_L2_Dsply 1;
BA_ "U_CD542_MY2021_Rx" SG_ 786 VehElRnge_L2_Dsply 1;
BA_ "U_U55X_MY2022_Rx" SG_ 786 VehElRnge_L2_Dsply 1;
BA_ "ECGUsedRxSignal" SG_ 786 VehElRngeCyc_L_Dsply 1;
BA_ "U_CD542_MY2021_Rx" SG_ 786 VehElRngeCyc_L_Dsply 1;
BA_ "U_U55X_MY2022_Rx" SG_ 786 VehElRngeCyc_L_Dsply 1;
BA_ "U_CX727_MY2021_Tx" SG_ 786 VehElRngeCyc_L_Dsply 1;
BA_ "U_CD542_MY2021_Tx" SG_ 786 VehElRngeCyc_L_Dsply 1;
BA_ "ECGUsedRxSignal" SG_ 786 RgenTrip_Pc_Dsply 1;
BA_ "U_CD542_MY2021_Rx" SG_ 786 RgenTrip_Pc_Dsply 1;
BA_ "U_U55X_MY2022_Rx" SG_ 786 RgenTrip_Pc_Dsply 1;
BA_ "U_CX727_MY2021_Tx" SG_ 786 RgenTrip_Pc_Dsply 1;
BA_ "U_P702_MY2021_Tx" SG_ 786 RgenTrip_Pc_Dsply 1;
BA_ "U_CD542_MY2021_Tx" SG_ 786 RgenTrip_Pc_Dsply 1;
BA_ "GenSigStartValueInteger" SG_ 786 RgenTrip_L_Dsply 65535;
BA_ "GenSigStartValue" SG_ 786 RgenTrip_L_Dsply 65535;
BA_ "ECGUsedRxSignal" SG_ 786 RgenTrip_L_Dsply 1;
BA_ "U_CD542_MY2021_Rx" SG_ 786 RgenTrip_L_Dsply 1;
BA_ "U_U55X_MY2022_Rx" SG_ 786 RgenTrip_L_Dsply 1;
BA_ "U_CX727_MY2021_Tx" SG_ 786 RgenTrip_L_Dsply 1;
BA_ "U_P702_MY2021_Tx" SG_ 786 RgenTrip_L_Dsply 1;
BA_ "U_CD542_MY2021_Tx" SG_ 786 RgenTrip_L_Dsply 1;
BA_ "ECGUsedRxSignal" SG_ 786 PtDataKeyId_D_Stat 1;
BA_ "U_CD542_MY2021_Rx" SG_ 786 PtDataKeyId_D_Stat 1;
BA_ "U_U55X_MY2022_Rx" SG_ 786 PtDataKeyId_D_Stat 1;
BA_ "U_CX727_MY2021_Tx" SG_ 786 PtDataKeyId_D_Stat 1;
BA_ "U_CD542_MY2021_Tx" SG_ 786 PtDataKeyId_D_Stat 1;
BA_ "U_CX727_MY2021_Rx" SG_ 748 ChrgrOutHi_U_Actl 1;
BA_ "U_CD542_MY2021_Rx" SG_ 748 ChrgrOutHi_U_Actl 1;
BA_ "U_CX727_MY2021_Rx" SG_ 748 ChrgrOutHi_I_Actl 1;
BA_ "U_CD542_MY2021_Rx" SG_ 748 ChrgrOutHi_I_Actl 1;
BA_ "U_CX727_MY2021_Rx" SG_ 748 ChrgrIn_Pw_Mx 1;
BA_ "U_CD542_MY2021_Rx" SG_ 748 ChrgrIn_Pw_Mx 1;
BA_ "WakeupSignal" SG_ 748 PtWakeupActv3_B_Rq 1;
BA_ "GenSigStartValueInteger" SG_ 748 PlgActv_D_ActlChrgr 3;
BA_ "GenSigStartValue" SG_ 748 PlgActv_D_ActlChrgr 2;
BA_ "U_CX727_MY2021_Rx" SG_ 748 PlgActv_D_ActlChrgr 1;
BA_ "U_CX727_MY2021_Rx" SG_ 748 ChrgrRdyStat_D_Actl 1;
BA_ "U_CD542_MY2021_Rx" SG_ 748 ChrgrRdyStat_D_Actl 1;
BA_ "GenSigStartValueInteger" SG_ 740 BattDcChrg_U_Actl 1022;
BA_ "GenSigStartValue" SG_ 740 BattDcChrg_U_Actl 1022;
BA_ "U_CX727_MY2021_Rx" SG_ 740 BattTracSoc_Pc_Dpltd 1;
BA_ "U_CD542_MY2021_Rx" SG_ 740 BattTracSoc_Pc_Dpltd 1;
BA_ "U_CX727_MY2021_Rx" SG_ 740 BattAuxCnnct_B_Cmd 1;
BA_ "U_CD542_MY2021_Rx" SG_ 740 BattAuxCnnct_B_Cmd 1;
BA_ "WakeupSignal" SG_ 740 PtWakeupActv2_B_Rq 1;
BA_ "U_CX727_MY2021_Rx" SG_ 740 BattChrg_U_Rq 1;
BA_ "U_CD542_MY2021_Rx" SG_ 740 BattChrg_U_Rq 1;
BA_ "U_CX727_MY2021_Rx" SG_ 740 BattChrg_I_Rq 1;
BA_ "U_CD542_MY2021_Rx" SG_ 740 BattChrg_I_Rq 1;
BA_ "U_CX727_MY2021_Rx" SG_ 589 BattTrac2_Pw_LimChrg 1;
BA_ "U_P702_MY2021_Rx" SG_ 589 BattTrac2_Pw_LimChrg 1;
BA_ "U_CD542_MY2021_Rx" SG_ 589 BattTrac2_Pw_LimChrg 1;
BA_ "U_CX727_MY2021_Rx" SG_ 589 BattTrac2_Pw_LimDchrg 1;
BA_ "U_P702_MY2021_Rx" SG_ 589 BattTrac2_Pw_LimDchrg 1;
BA_ "U_CD542_MY2021_Rx" SG_ 589 BattTrac2_Pw_LimDchrg 1;
BA_ "U_CX727_MY2021_Rx" SG_ 589 BattTrac2_Pw_DchrgInst 1;
BA_ "U_P702_MY2021_Rx" SG_ 589 BattTrac2_Pw_DchrgInst 1;
BA_ "U_CD542_MY2021_Rx" SG_ 589 BattTrac2_Pw_DchrgInst 1;
BA_ "U_CX727_MY2021_Rx" SG_ 589 BattTrac2_Pw_ChrgInst 1;
BA_ "U_P702_MY2021_Rx" SG_ 589 BattTrac2_Pw_ChrgInst 1;
BA_ "U_CD542_MY2021_Rx" SG_ 589 BattTrac2_Pw_ChrgInst 1;
BA_ "WakeupSignal" SG_ 588 HvacAirFlw_B_RqBatt 1;
BA_ "U_CX727_MY2021_Rx" SG_ 588 BattChrgRdyStat_D_Actl 1;
BA_ "U_CD542_MY2021_Rx" SG_ 588 BattChrgRdyStat_D_Actl 1;
BA_ "GenSigStartValueInteger" SG_ 588 BattTracSoc2_Pc_Actl 16382;
BA_ "GenSigStartValue" SG_ 588 BattTracSoc2_Pc_Actl 16382;
BA_ "U_CX727_MY2021_Rx" SG_ 588 BattTracSoc2_Pc_Actl 1;
BA_ "U_P702_MY2021_Rx" SG_ 588 BattTracSoc2_Pc_Actl 1;
BA_ "U_CD542_MY2021_Rx" SG_ 588 BattTracSoc2_Pc_Actl 1;
BA_ "GenSigStartValueInteger" SG_ 588 BattTracSoc_Pc_Dsply 254;
BA_ "GenSigStartValue" SG_ 588 BattTracSoc_Pc_Dsply 254;
BA_ "U_CX727_MY2021_Rx" SG_ 588 BattTracSoc_Pc_Dsply 1;
BA_ "U_CD542_MY2021_Rx" SG_ 588 BattTracSoc_Pc_Dsply 1;
BA_ "GenSigStartValueInteger" SG_ 588 BattTracClntIn_Te_Actl 75;
BA_ "GenSigStartValue" SG_ 588 BattTracClntIn_Te_Actl 75;
BA_ "GenSigStartValueInteger" SG_ 588 BattTrac_Te_Actl 150;
BA_ "GenSigStartValue" SG_ 588 BattTrac_Te_Actl 150;
BA_ "U_CX727_MY2021_Rx" SG_ 588 BattTrac_Te_Actl 1;
BA_ "U_P702_MY2021_Rx" SG_ 588 BattTrac_Te_Actl 1;
BA_ "U_CD542_MY2021_Rx" SG_ 588 BattTrac_Te_Actl 1;
BA_ "GenSigStartValueInteger" SG_ 588 HvacRec_D_RqMxBatt 10;
BA_ "GenSigStartValue" SG_ 588 HvacRec_D_RqMxBatt 10;
BA_ "GenSigStartValueInteger" SG_ 587 BattTracClnt_Te_Actl 164;
BA_ "GenSigStartValue" SG_ 587 BattTracClnt_Te_Actl 254;
BA_ "U_CX727_MY2021_Rx" SG_ 587 BattTracClnt_Te_Actl 1;
BA_ "U_P702_MY2021_Rx" SG_ 587 BattTracClnt_Te_Actl 1;
BA_ "U_CD542_MY2021_Rx" SG_ 587 BattTracClnt_Te_Actl 1;
BA_ "GenSigStartValueInteger" SG_ 587 BattTracClnt_Te_Rq 190;
BA_ "GenSigStartValue" SG_ 587 BattTracClnt_Te_Rq 190;
BA_ "GenSigStartValueInteger" SG_ 587 BattTracSoc_Pc_MxPrtct 700;
BA_ "GenSigStartValue" SG_ 587 BattTracSoc_Pc_MxPrtct 700;
BA_ "U_CX727_MY2021_Rx" SG_ 587 BattTracSoc_Pc_MxPrtct 1;
BA_ "U_P702_MY2021_Rx" SG_ 587 BattTracSoc_Pc_MxPrtct 1;
BA_ "U_CD542_MY2021_Rx" SG_ 587 BattTracSoc_Pc_MxPrtct 1;
BA_ "GenSigStartValueInteger" SG_ 587 BattTracSoc_Pc_MnPrtct 300;
BA_ "GenSigStartValue" SG_ 587 BattTracSoc_Pc_MnPrtct 30;
BA_ "U_CX727_MY2021_Rx" SG_ 587 BattTracSoc_Pc_MnPrtct 1;
BA_ "U_P702_MY2021_Rx" SG_ 587 BattTracSoc_Pc_MnPrtct 1;
BA_ "U_CD542_MY2021_Rx" SG_ 587 BattTracSoc_Pc_MnPrtct 1;
BA_ "GenSigStartValueInteger" SG_ 587 BattTracSoc_Pc_LimLo 400;
BA_ "GenSigStartValue" SG_ 587 BattTracSoc_Pc_LimLo 400;
BA_ "U_CX727_MY2021_Rx" SG_ 587 BattTracSoc_Pc_LimLo 1;
BA_ "U_P702_MY2021_Rx" SG_ 587 BattTracSoc_Pc_LimLo 1;
BA_ "U_CD542_MY2021_Rx" SG_ 587 BattTracSoc_Pc_LimLo 1;
BA_ "GenSigStartValueInteger" SG_ 587 BattTracSoc_Pc_LimHi 600;
BA_ "GenSigStartValue" SG_ 587 BattTracSoc_Pc_LimHi 600;
BA_ "U_CX727_MY2021_Rx" SG_ 587 BattTracSoc_Pc_LimHi 1;
BA_ "U_P702_MY2021_Rx" SG_ 587 BattTracSoc_Pc_LimHi 1;
BA_ "U_CD542_MY2021_Rx" SG_ 587 BattTracSoc_Pc_LimHi 1;
BA_ "U_CX727_MY2021_Tx" SG_ 389 BattTracClntFlw_Pc_Rq 1;
BA_ "U_P702_MY2021_Tx" SG_ 389 BattTracClntFlw_Pc_Rq 1;
BA_ "U_CD542_MY2021_Tx" SG_ 389 BattTracClntFlw_Pc_Rq 1;
BA_ "U_CX727_MY2021_Tx" SG_ 389 HtrnOvrTeLamp_B_Dsply 1;
BA_ "U_P702_MY2021_Tx" SG_ 389 HtrnOvrTeLamp_B_Dsply 1;
BA_ "U_CD542_MY2021_Tx" SG_ 389 HtrnOvrTeLamp_B_Dsply 1;
BA_ "U_CX727_MY2021_Tx" SG_ 389 HtrnMil_D_Rq 1;
BA_ "U_P702_MY2021_Tx" SG_ 389 HtrnMil_D_Rq 1;
BA_ "U_CD542_MY2021_Tx" SG_ 389 HtrnMil_D_Rq 1;
BA_ "U_P702_MY2021_Rx" SG_ 389 HtrnAin_UHi_Actl 1;
BA_ "ECGUsedRxSignal" SG_ 389 HtrnAin_UHi_Actl 1;
BA_ "U_CD542_MY2021_Rx" SG_ 389 HtrnAin_UHi_Actl 1;
BA_ "U_U55X_MY2022_Rx" SG_ 389 HtrnAin_UHi_Actl 1;
BA_ "U_CD764_MY2022_Rx" SG_ 389 HtrnAin_UHi_Actl 1;
BA_ "U_CX727_MY2021_Tx" SG_ 389 HtrnAin_UHi_Actl 1;
BA_ "U_P702_MY2021_Tx" SG_ 389 HtrnAin_UHi_Actl 1;
BA_ "U_CD542_MY2021_Tx" SG_ 389 HtrnAin_UHi_Actl 1;
BA_ "ECGUsedRxSignal" SG_ 389 HtrnSrvcRqd_B_Dsply 1;
BA_ "U_CD764_MY2022_Rx" SG_ 389 HtrnSrvcRqd_B_Dsply 1;
BA_ "U_CX727_MY2021_Tx" SG_ 389 HtrnSrvcRqd_B_Dsply 1;
BA_ "U_P702_MY2021_Tx" SG_ 389 HtrnSrvcRqd_B_Dsply 1;
BA_ "U_CD542_MY2021_Tx" SG_ 389 HtrnSrvcRqd_B_Dsply 1;
BA_ "U_P702_MY2021_Rx" SG_ 389 HtrnHvilOpen_B_Actl 1;
BA_ "ECGUsedRxSignal" SG_ 389 HtrnHvilOpen_B_Actl 1;
BA_ "U_CD542_MY2021_Rx" SG_ 389 HtrnHvilOpen_B_Actl 1;
BA_ "U_U55X_MY2022_Rx" SG_ 389 HtrnHvilOpen_B_Actl 1;
BA_ "U_CD764_MY2022_Rx" SG_ 389 HtrnHvilOpen_B_Actl 1;
BA_ "U_CX727_MY2021_Tx" SG_ 389 HtrnHvilOpen_B_Actl 1;
BA_ "U_P702_MY2021_Tx" SG_ 389 HtrnHvilOpen_B_Actl 1;
BA_ "U_CD542_MY2021_Tx" SG_ 389 HtrnHvilOpen_B_Actl 1;
BA_ "U_CX727_MY2021_Tx" SG_ 389 PtWakeupDeltaT_T_Rq 1;
BA_ "U_P702_MY2021_Tx" SG_ 389 PtWakeupDeltaT_T_Rq 1;
BA_ "U_CD542_MY2021_Tx" SG_ 389 PtWakeupDeltaT_T_Rq 1;
BA_ "U_CX727_MY2021_Rx" SG_ 389 PreCondActv_B_Actl 1;
BA_ "U_CD542_MY2021_Rx" SG_ 389 PreCondActv_B_Actl 1;
BA_ "U_CX727_MY2021_Tx" SG_ 389 PreCondActv_B_Actl 1;
BA_ "U_P702_MY2021_Tx" SG_ 389 PreCondActv_B_Actl 1;
BA_ "U_CD542_MY2021_Tx" SG_ 389 PreCondActv_B_Actl 1;
BA_ "U_CX727_MY2021_Tx" SG_ 389 DrvCondTpRrDefrs_B_Rq 1;
BA_ "U_P702_MY2021_Tx" SG_ 389 DrvCondTpRrDefrs_B_Rq 1;
BA_ "U_CD542_MY2021_Tx" SG_ 389 DrvCondTpRrDefrs_B_Rq 1;
BA_ "GenSigStartValueInteger" SG_ 389 BattTrac_I_EstVsc 15000;
BA_ "U_CX727_MY2021_Tx" SG_ 389 BattTrac_I_EstVsc 1;
BA_ "U_P702_MY2021_Tx" SG_ 389 BattTrac_I_EstVsc 1;
BA_ "U_CD542_MY2021_Tx" SG_ 389 BattTrac_I_EstVsc 1;
BA_ "U_T6_MCA_MY2020_Rx" SG_ 1009 AutoHoldSwtch_D_Stat3 1;
BA_ "U_CD542_MY2021_Rx" SG_ 1009 AutoHoldSwtch_D_Stat3 1;
BA_ "U_U55X_MY2022_Rx" SG_ 1009 AutoHoldSwtch_D_Stat3 1;
BA_ "U_CD764_MY2022_Rx" SG_ 1009 AutoHoldSwtch_D_Stat3 1;
BA_ "U_P702_MY2021_Rx" SG_ 1009 TrlrAidCancl_B_Rq 1;
BA_ "U_T6_MCA_MY2020_Rx" SG_ 1009 TrlrAidCancl_B_Rq 1;
BA_ "U_CD542_MY2021_Rx" SG_ 1009 TrlrAidCancl_B_Rq 1;
BA_ "U_U55X_MY2022_Rx" SG_ 1009 TrlrAidCancl_B_Rq 1;
BA_ "GenSigStartValueInteger" SG_ 1009 CenterStackRing_D_Actl 2;
BA_ "GenSigStartValue" SG_ 1009 CenterStackRing_D_Actl 2;
BA_ "ContentDependant" SG_ 360 GsmSrvcRqd_B_Rq 1;
BA_ "U_CX727_MY2021_Rx" SG_ 360 GsmSrvcRqd_B_Rq 1;
BA_ "U_CD542_MY2021_Rx" SG_ 360 GsmSrvcRqd_B_Rq 1;
BA_ "ContentDependant" SG_ 360 TrnTrcmPwmSig_D_Actl 1;
BA_ "ContentDependant" SG_ 360 TrnGearPwmFalt_B_Actl 1;
BA_ "U_CX727_MY2021_Rx" SG_ 360 TrnGearPwmFalt_B_Actl 1;
BA_ "U_P702_MY2021_Rx" SG_ 360 TrnGearPwmFalt_B_Actl 1;
BA_ "U_T6_MCA_MY2020_Rx" SG_ 360 TrnGearPwmFalt_B_Actl 1;
BA_ "U_CD542_MY2021_Rx" SG_ 360 TrnGearPwmFalt_B_Actl 1;
BA_ "U_U55X_MY2022_Rx" SG_ 360 TrnGearPwmFalt_B_Actl 1;
BA_ "U_CD764_MY2022_Rx" SG_ 360 TrnGearPwmFalt_B_Actl 1;
BA_ "ContentDependant" SG_ 360 GearButtnStuck_B_Actl 1;
BA_ "U_CX727_MY2021_Rx" SG_ 360 GearButtnStuck_B_Actl 1;
BA_ "U_P702_MY2021_Rx" SG_ 360 GearButtnStuck_B_Actl 1;
BA_ "U_T6_MCA_MY2020_Rx" SG_ 360 GearButtnStuck_B_Actl 1;
BA_ "U_CD542_MY2021_Rx" SG_ 360 GearButtnStuck_B_Actl 1;
BA_ "U_U55X_MY2022_Rx" SG_ 360 GearButtnStuck_B_Actl 1;
BA_ "U_CD764_MY2022_Rx" SG_ 360 GearButtnStuck_B_Actl 1;
BA_ "GenSigStartValueInteger" SG_ 331 TrnAout2_W_ActlUnfilt 65534;
BA_ "GenSigStartValue" SG_ 331 TrnAout2_W_ActlUnfilt 65534;
BA_ "U_CD542_MY2021_Rx" SG_ 331 CmbbEngTqMn_B_ActlHtrn 1;
BA_ "U_CX727_MY2021_Tx" SG_ 331 CmbbEngTqMn_B_ActlHtrn 1;
BA_ "U_CD542_MY2021_Tx" SG_ 331 CmbbEngTqMn_B_ActlHtrn 1;
BA_ "U_CD542_MY2021_Rx" SG_ 331 CmbbDeny_B_ActlHtrn 1;
BA_ "U_CX727_MY2021_Tx" SG_ 331 CmbbDeny_B_ActlHtrn 1;
BA_ "U_CD542_MY2021_Tx" SG_ 331 CmbbDeny_B_ActlHtrn 1;
BA_ "GenSigStartValueInteger" SG_ 122 BattTrac_U_LimLo 88;
BA_ "GenSigStartValue" SG_ 122 BattTrac_U_LimLo 88;
BA_ "U_CX727_MY2021_Rx" SG_ 122 BattTrac_U_LimLo 1;
BA_ "U_P702_MY2021_Rx" SG_ 122 BattTrac_U_LimLo 1;
BA_ "U_CD542_MY2021_Rx" SG_ 122 BattTrac_U_LimLo 1;
BA_ "GenSigStartValueInteger" SG_ 122 BattTrac_U_LimHi 163;
BA_ "GenSigStartValue" SG_ 122 BattTrac_U_LimHi 163;
BA_ "U_CX727_MY2021_Rx" SG_ 122 BattTrac_U_LimHi 1;
BA_ "U_P702_MY2021_Rx" SG_ 122 BattTrac_U_LimHi 1;
BA_ "U_CD542_MY2021_Rx" SG_ 122 BattTrac_U_LimHi 1;
BA_ "U_CX727_MY2021_Rx" SG_ 122 VehStrtInhbt_B_RqBatt 1;
BA_ "U_P702_MY2021_Rx" SG_ 122 VehStrtInhbt_B_RqBatt 1;
BA_ "U_CD542_MY2021_Rx" SG_ 122 VehStrtInhbt_B_RqBatt 1;
BA_ "U_CX727_MY2021_Rx" SG_ 122 BattTracOffFst_D_Actl 1;
BA_ "U_P702_MY2021_Rx" SG_ 122 BattTracOffFst_D_Actl 1;
BA_ "U_CD542_MY2021_Rx" SG_ 122 BattTracOffFst_D_Actl 1;
BA_ "U_CX727_MY2021_Rx" SG_ 122 BattTracOff_B_Actl 1;
BA_ "U_P702_MY2021_Rx" SG_ 122 BattTracOff_B_Actl 1;
BA_ "U_CD542_MY2021_Rx" SG_ 122 BattTracOff_B_Actl 1;
BA_ "U_CX727_MY2021_Rx" SG_ 122 BattTracMil_D_Rq 1;
BA_ "U_CD542_MY2021_Rx" SG_ 122 BattTracMil_D_Rq 1;
BA_ "U_CX727_MY2021_Rx" SG_ 122 BattTracCnnct_B_Cmd 1;
BA_ "GenSigStartValueInteger" SG_ 122 BattTrac_U_Actl 1022;
BA_ "GenSigStartValue" SG_ 122 BattTrac_U_Actl 1022;
BA_ "U_CX727_MY2021_Rx" SG_ 122 BattTrac_U_Actl 1;
BA_ "U_P702_MY2021_Rx" SG_ 122 BattTrac_U_Actl 1;
BA_ "U_CD542_MY2021_Rx" SG_ 122 BattTrac_U_Actl 1;
BA_ "GenSigStartValueInteger" SG_ 122 BattTrac_I_Actl 15000;
BA_ "U_CX727_MY2021_Rx" SG_ 122 BattTrac_I_Actl 1;
BA_ "U_P702_MY2021_Rx" SG_ 122 BattTrac_I_Actl 1;
BA_ "U_CD542_MY2021_Rx" SG_ 122 BattTrac_I_Actl 1;
VAL_ 1108 RCMSerialNoByte8 255 "Invalid" 254 "Unknown" ;
VAL_ 1108 RCMSerialNoByte7 255 "Invalid" 254 "Unknown" ;
VAL_ 1108 RCMSerialNoByte6 255 "Invalid" 254 "Unknown" ;
VAL_ 1108 RCMSerialNoByte5 255 "Invalid" 254 "Unknown" ;
VAL_ 1108 RCMSerialNoByte4 255 "Invalid" 254 "Unknown" ;
VAL_ 1108 RCMSerialNoByte3 255 "Invalid" 254 "Unknown" ;
VAL_ 1108 RCMSerialNoByte2 255 "Invalid" 254 "Unknown" ;
VAL_ 1108 RCMSerialNoByte1 255 "Invalid" 254 "Unknown" ;
VAL_ 261 ChrgStatDsply_D_Rq 3 "NotUsed_2" 2 "NotUsed_1" 1 "On" 0 "Off" ;
VAL_ 261 NextUsageTimeToggle_Rq 0 "Inactive" 2 "Disable" 1 "Enable" ;
VAL_ 261 LongTermParking_Rq 2 "On" 1 "Off" 0 "Inactive" ;
VAL_ 261 ModemReset_D_Rq 15 "NotUsed_11" 14 "NotUsed_10" 13 "NotUsed_9" 12 "NotUsed_8" 11 "NotUsed_7" 10 "NotUsed_6" 9 "NotUsed_5" 8 "NotUsed_4" 7 "NotUsed_3" 6 "BrandConnectReset2" 5 "BrandConnectReset1" 4 "CcsReset" 3 "OnlineTrafficReset" 2 "PaakReset" 1 "WifiHotspotReset" 0 "Null" ;
VAL_ 261 StopStrtDrvMde_B_RqBtn3 1 "Pressed" 0 "Not_Pressed" ;
VAL_ 261 TCU_ESN_D_Rq 3 "NotUsed" 2 "TCU_ESN_Request" 1 "NoRequest" 0 "Inactive" ;
VAL_ 261 FactoryReset_Rq 1 "ResetFactoryDefaults" 0 "Inactive" ;
VAL_ 1146 TrlrAidSwtch_D_RqDrv 3 "Faulty" 2 "NotUsed" 1 "Pressed" 0 "Not_Pressed" ;
VAL_ 1146 TrlrAidCtl_U_RqDrv 4095 "Faulty" 4094 "NoDataExists" ;
VAL_ 533 TjaLcEnbl_D_RqMnu 3 "NotUsed" 2 "On" 1 "Off" 0 "Null" ;
VAL_ 533 ClrExitAsstEnbl_D_RqMnu 3 "NotUsed" 0 "Inactive" 2 "Enable" 1 "Disable" ;
VAL_ 533 TrlrAidMde_D_Rq 3 "Mode_3" 2 "Mode_2" 1 "Mode_1" 0 "NoRequest" ;
VAL_ 533 TCU_Init_Actvtn_St 3 "NotUsed" 2 "InitialActivateDeny" 1 "InitialActivateAccept" 0 "Invalid" ;
VAL_ 533 TCU_Final_Actvtn_St 3 "NotUsed" 2 "FinalActivateDeny" 1 "FinalActivateAccept" 0 "Invalid" ;
VAL_ 533 OtaTrg_D_Stat 3 "NotUsed_1" 2 "Accepted" 1 "NotAccepted" 0 "Null" ;
VAL_ 533 OnbChrgGoTTouch_D_Rq 3 "NotUsed" 2 "On" 1 "Off" 0 "Null" ;
VAL_ 533 OnbChrgGoTPrcond_D_Rq 3 "High" 2 "Medium" 1 "Low" 0 "Off" ;
VAL_ 533 OnbChrgGoTOn_D_Rq 3 "NotUsed" 2 "On" 1 "Off" 0 "Null" ;
VAL_ 533 OnbChrgGoTMnte_D_Rq 15 "NotUsed_4" 14 "NotUsed_3" 13 "NotUsed_2" 12 "NotUsed_1" 11 "Minute_55" 10 "Minute_50" 9 "Minute_45" 8 "Minute_40" 7 "Minute_35" 6 "Minute_30" 5 "Minute_25" 4 "Minute_20" 3 "Minute_15" 2 "Minute_10" 1 "Minute_5" 0 "Minute_0" ;
VAL_ 533 OnbChrgGoTHr_T_Rq 31 "Faulty" 30 "NoDataExists" ;
VAL_ 533 OnbChrgGoTExtHtr_D_Rq 3 "NotUsed" 2 "On" 1 "Off" 0 "Null" ;
VAL_ 533 OnbChrgGoTDelete_B_Rq 1 "Request" 0 "NoRequest" ;
VAL_ 533 OnbChrgClearAll_B_Rq 1 "Request" 0 "NoRequest" ;
VAL_ 533 PaakMyKey_D_Rq 3 "NotUsed" 2 "ConfirmNewPaakMyKey" 1 "RequestNewPaakMyKey" 0 "None" ;
VAL_ 533 AutoEpbZoomView_B_Stat 1 "Active" 0 "Inactive" ;
VAL_ 533 AutoEpbButtn_B_Stat 1 "Pressed" 0 "Not_Pressed" ;
VAL_ 533 DcacPw_D_Rq 3 "High" 2 "Low" 1 "Off" 0 "Null" ;
VAL_ 533 DcacPwReset_B_Rq 1 "Reset" 0 "Null" ;
VAL_ 533 LghtAmbDrvMde_D_Rq 3 "NotUsed" 2 "Automatic" 1 "Manual" 0 "Null" ;
VAL_ 533 DcacPwLoButtn_B_Stat 1 "Pressed" 0 "Not_Pressed" ;
VAL_ 533 DcacPwOffButtn_B_Stat 1 "Pressed" 0 "Not_Pressed" ;
VAL_ 533 DcacPwHiButtn_B_Stat 1 "Pressed" 0 "Not_Pressed" ;
VAL_ 533 DcacPwResetButtn_B_Stat 1 "Pressed" 0 "Not_Pressed" ;
VAL_ 533 DcacPwButtn_B_Falt 1 "Faulted" 0 "NotFaulted" ;
VAL_ 533 OnbChrgGoTUpdate_B_Rq 1 "Request" 0 "NoRequest" ;
VAL_ 533 TrlrAlarmButtn_B_Stat 1 "On" 0 "Off" ;
VAL_ 533 DcacMdeButtn_B_Stat 1 "Pressed" 0 "Not_Pressed" ;
VAL_ 533 DcacGfciTestBttn_B_Stat 1 "Pressed" 0 "Not_Pressed" ;
VAL_ 533 TrlrHitch_D_RqMnu 15 "NotUsed_10" 14 "NotUsed_9" 13 "NotUsed_8" 12 "NotUsed_7" 11 "NotUsed_6" 10 "NotUsed_5" 9 "NotUsed_4" 8 "NotUsed_3" 7 "NotUsed_2" 6 "NotUsed_1" 5 "GoToTraileringDomain" 4 "Confirm" 3 "TurnOnTba" 2 "TurnOnAutohitch" 1 "CancelAutohitch" 0 "NoRequest" ;
VAL_ 533 DcacPwButtn_B_Stat 1 "Pressed" 0 "Not_Pressed" ;
VAL_ 778 PrkAidAcsyRear_D_RqDrv 3 "NotUsed" 2 "On" 1 "Off" 0 "Null" ;
VAL_ 778 PrkAidAcsyFront_D_RqDrv 3 "NotUsed" 2 "On" 1 "Off" 0 "Null" ;
VAL_ 778 Cta_D_Rq 3 "Unused" 2 "NoDataExists" 1 "On" 0 "Off" ;
VAL_ 778 PrkAidRear_D_RqDrv 2 "Status" 3 "NotUsed" 1 "Enabled" 0 "Disabled" ;
VAL_ 778 PrkAidFront_D_RqDrv 2 "Status" 3 "NotUsed" 1 "Enabled" 0 "Disabled" ;
VAL_ 778 SteEffort_D_Rq 7 "NotUsed_3" 6 "NotUsed_2" 5 "NotUsed_1" 4 "SpecialMode_2" 3 "SpecialMode_1" 2 "Comfort" 1 "Sport" 0 "Normal" ;
VAL_ 778 Sod_D_Rq 2 "BLIS_On_Second_Warning_ON" 1 "BLIS_On_Second_Warning_OFF" 0 "Off" ;
VAL_ 778 ClrExitAsstEnbl_D_RqDrv 3 "NotUsed" 0 "Inactive" 2 "Enable" 1 "Disable" ;
VAL_ 1041 ElCmprUHi_D_Stat 3 "Overvoltage" 2 "Undervoltage" 1 "InRange" 0 "Undetermined" ;
VAL_ 1041 ElCmprOverTe_D_Stat 3 "OverTempStop" 2 "OverTempWarning" 1 "Normal" 0 "Undefined" ;
VAL_ 1041 ElCmpr_N_Actl 255 "Invalid" ;
VAL_ 1041 ElCmpr_Pw_Actl 255 "Invalid" ;
VAL_ 1041 ElCmpr_D_Stat 7 "Signal_Invalid" 6 "Comp_Off_ActlSpd_Abnormal" 5 "Comp_Off_TrgtSpd_OutRange" 4 "Comp_Shutdown" 3 "Comp_Stopped_Self_Protect" 2 "Comp_Degraded" 1 "Comp_On" 0 "Comp_Off" ;
VAL_ 1041 ElCmprPerfErr_D_Falt 3 "NotUsed" 2 "Pass" 1 "Fail" 0 "Not_Diagnose_Yet" ;
VAL_ 1041 ElCmprInnrErr_D_Falt 3 "NotUsed" 2 "Pass" 1 "Fail" 0 "Not_Diagnose_Yet" ;
VAL_ 1041 ElCmprLostComm_D_Falt 3 "NotUsed" 2 "Pass" 1 "Fail" 0 "Not_Diagnose_Yet" ;
VAL_ 1041 ElCmprOverLoad_D_Falt 3 "NotUsed" 2 "Pass" 1 "Fail" 0 "Not_Diagnose_Yet" ;
VAL_ 1041 ElCmprOverTe_D_Falt 3 "NotUsed" 2 "Pass" 1 "Fail" 0 "Not_Diagnose_Yet" ;
VAL_ 1041 ElCmprBattURng_D_Falt 3 "NotUsed" 2 "Pass" 1 "Fail" 0 "Not_Diagnose_Yet" ;
VAL_ 1041 ElCmprBattSysU_D_Falt 3 "NotUsed" 2 "Pass" 1 "Fail" 0 "Not_Diagnose_Yet" ;
VAL_ 1041 ElCmprSysU_D_Falt 3 "NotUsed" 2 "Pass" 1 "Fail" 0 "Not_Diagnose_Yet" ;
VAL_ 1067 BattULoAux_U_Rq 4095 "Faulty" ;
VAL_ 1067 BattULoAuxIsol_D_Rq 3 "Undefined" 2 "Retain" 1 "Close" 0 "Open" ;
VAL_ 1067 BattULoAux_I_Actl 4095 "Faulty" ;
VAL_ 1067 BattULoAux_D_Qlty 3 "OK" 2 "Not_Within_Specifications" 1 "Eval_In_Progress" 0 "Faulty" ;
VAL_ 1067 BattULoAux_U_Actl 255 "Faulty" ;
VAL_ 1067 BattULoAux_B_Falt 1 "Fault" 0 "No_Fault" ;
VAL_ 1118 BptTgl_B_Complt 1 "Yes" 0 "No" ;
VAL_ 1118 AcChrgRdy_B_Stat 1 "True" 0 "False" ;
VAL_ 1118 DgtlCommGtwyMde_D_Rq 15 "NotUsed_10" 14 "NotUsed_9" 13 "NotUsed_8" 12 "NotUsed_7" 11 "NotUsed_6" 10 "NotUsed_5" 9 "NotUsed_4" 8 "NotUsed_3" 7 "NotUsed_2" 6 "NotUsed_1" 5 "AcPnC" 4 "AcEIM" 3 "DcPnC" 2 "DcEIM" 1 "AttemptDgtlComm" 0 "NoDgtlComm" ;
VAL_ 1118 ExtChrgNowButtn_B_Rq 1 "Request" 0 "NoRequest" ;
VAL_ 1118 CoolFanChrgr_D_Rq 3 "High" 2 "Medium" 1 "Low" 0 "Off" ;
VAL_ 1118 ChrgrClntFlw_D_Rq 3 "High" 2 "Medium" 1 "Low" 0 "Off" ;
VAL_ 1118 PlgStatEvnt_B_Stat 1 "Active" 0 "Inactive" ;
VAL_ 1118 ChrgrCnnctPwr_B_Stat 1 "Asserted" 0 "NotAsserted" ;
VAL_ 1118 ChrgrAvailEvnt_B_Stat 1 "Active" 0 "Inactive" ;
VAL_ 1118 ChrgrSrvcRqd_B_Rq 1 "On" 0 "Off" ;
VAL_ 1118 ChrgrS2Swtch_B_Stat 1 "Close" 0 "Open" ;
VAL_ 1118 ChrgChngEvnt_B_Stat 1 "Active" 0 "Inactive" ;
VAL_ 1118 ChrgCordLck_D_Stat 7 "Faulty" 6 "LockFail" 5 "UnlockFail" 4 "LockInProgress" 3 "UnlockInProgress" 2 "Lock" 1 "Unlock" 0 "Retain" ;
VAL_ 1118 ChrgrInPwMde_D_Actl 15 "NotUsed_5" 14 "NotUsed_4" 13 "NotUsed_3" 12 "NotUsed_2" 11 "NotUsed_1" 10 "DcBpt" 9 "DigitalCommEnd" 8 "EvseFault" 7 "EvseNotCompatible" 6 "IcCharging" 5 "DcCharging" 4 "AcDigital" 3 "AcBasic" 2 "DigitalCommDetected" 1 "EvsePaused" 0 "EvseNotDetected" ;
VAL_ 1118 ChrgPortDrOpen_B_Stat 1 "True" 0 "False" ;
VAL_ 1118 ChrgrDcOvrVolt_B_Falt 1 "Yes" 0 "No" ;
VAL_ 1118 ChrgrDcOvrCurnt_B_Falt 1 "Yes" 0 "No" ;
VAL_ 1118 ChrgrPncEnbl_D_Stat 3 "NotUsed" 2 "Enable" 1 "Disable" 0 "Null" ;
VAL_ 1118 ChrgrCc2Cnnct_B_Falt 1 "Yes" 0 "No" ;
VAL_ 1118 ChrgPortDcTeMx_B_Falt 1 "Yes" 0 "No" ;
VAL_ 1118 ChrgCrdLck_D_Falt 3 "NotUsed" 2 "HardwareFault" 1 "CsiFault" 0 "NoFault" ;
VAL_ 1040 RoadGrd_Pc_Est 1023 "Faulty" ;
VAL_ 1040 BattTrac_I2_EstVsc 262143 "Faulty" 262142 "NoDataExists" ;
VAL_ 1040 ElCmprEnbl_B_Rq 1 "Enable" 0 "Disable" ;
VAL_ 1144 BattTracCool_B_Actl 1 "On" 0 "Off" ;
VAL_ 1144 BattChrgInhbt_D2_Rq 7 "NotUsed_4" 6 "NotUsed_3" 5 "NotUsed_2" 4 "NotUsed_1" 3 "MaintainTargetSoc" 2 "EndAtTarget" 1 "InhibitCharging" 0 "Enable_Charging" ;
VAL_ 1144 AwdLckMde_D_Stat 7 "NotUsed_2" 6 "NotUsed_1" 5 "PrimaryAxleSpeedControl" 4 "DualAxleSpeedControl" 3 "EfficiencySplit" 2 "SecondaryAxleTorqueCtrl" 1 "SecondaryAxleSpeedCtrl" 0 "Off" ;
VAL_ 1144 ULoBattTrnsfrSustn_B_Rq 1 "Active" 0 "Inactive" ;
VAL_ 1144 ULoBattTransfer_D_Stat 7 "NotUsed_2" 6 "NotUsed_1" 5 "TransferError" 4 "TransferComplete" 3 "TransferThroughGridEnergy" 2 "InsufficientEnergyToXfer" 1 "TransferInProgress" 0 "NoTransfer" ;
VAL_ 1144 BattChrgTrgtSoC_D_Rq 7 "Percent_50" 6 "Percent_60" 5 "Percent_70" 4 "Percent_80" 3 "Percent_85" 2 "Percent_90" 1 "Percent_95" 0 "Percent_100" ;
VAL_ 1144 CabnEvapSovFront_B_Rq 1 "On" 0 "Off" ;
VAL_ 1144 HeatCoreSovRear_B_Rq 1 "On" 0 "Off" ;
VAL_ 1144 BattChlrSov_B_Rq 1 "On" 0 "Off" ;
VAL_ 1144 CabnEvapSovRear_B_Rq 1 "On" 0 "Off" ;
VAL_ 1144 BrkAppl_D_RqPt 3 "BrakesSlowRelease" 2 "BrakesFastRelease" 1 "BrakesEngage" 0 "NotActive" ;
VAL_ 1144 BattClntVlvOvrrd_D_Rq 3 "NotUsed" 2 "OverrideTbcvToChiller" 1 "OverrideTbcvToRadiator" 0 "NoOverrideToTbcvCLogic" ;
VAL_ 1144 BattTracChillerOn_B_Rq 1 "On" 0 "Off" ;
VAL_ 1144 BattTracChiller_D_Stat 3 "NotUsed" 2 "ChillerNotAvailable" 1 "ChillerBrieflyAvailable" 0 "ChillerAvailable" ;
VAL_ 1144 HtrnDcdcDis_B_Rq 1 "Yes" 0 "No" ;
VAL_ 1144 HtrnCnnctPwr_B_Stat 1 "Asserted" 0 "NotAsserted" ;
VAL_ 1144 PtcHtr_D_Stat 3 "Faulty" 2 "NotUsed" 1 "On" 0 "Off" ;
VAL_ 1144 WakeAlarm0_B_Typ 1 "CanAndEcuDriveCircuit" 0 "CanOnly" ;
VAL_ 1144 HtrnClntFlw_D_Rq 3 "High" 2 "Medium" 1 "Low" 0 "Off" ;
VAL_ 1144 BattTracDrvSustn_B_Rq 1 "Active" 0 "Inactive" ;
VAL_ 1144 CabinDrvSustn_B_Rq 1 "Active" 0 "Inactive" ;
VAL_ 1144 ChrgNowEvnt_B_Stat 1 "Active" 0 "Inactive" ;
VAL_ 1144 PreCondBatt_B_Actl 1 "On" 0 "Off" ;
VAL_ 1144 BattTracClntVlv_B_Rq 1 "On" 0 "Off" ;
VAL_ 1112 BattDcCnnct_D_Cmd 7 "NotUsed_3" 6 "NotUsed_2" 5 "NotUsed_1" 4 "WeldCheck" 3 "OkToDischarge" 2 "Closed" 1 "Precharge" 0 "Open" ;
VAL_ 1112 BattTrac2_E_Avail 4095 "Faulty" 4094 "NoDataExists" ;
VAL_ 1112 BattTracCnnct_D_Cmd 7 "NotUsed_3" 6 "NotUsed_2" 5 "NotUsed_1" 4 "WeldCheck" 3 "OkToDischarge" 2 "Closed" 1 "Precharge" 0 "Open" ;
VAL_ 1112 BattTracHvilOpen_B_Stat 1 "Open" 0 "Closed" ;
VAL_ 1112 BattTracCoolLvl_D_Rq 7 "Faulty" 6 "NotUsed" 5 "ChillerCoolingBattFirst" 4 "ChillerCoolingCabinFirst" 3 "ForcedCoolingRadiator" 2 "OpportunisticCoolingRad" 1 "CoolantFlowBypassLine" 0 "Off" ;
VAL_ 1112 BattTracTeSustn_B_Rq 1 "Active" 0 "Inactive" ;
VAL_ 1112 BattTracTeEvnt_B_Stat 1 "Active" 0 "Inactive" ;
VAL_ 1112 BattTracDcdcDis_B_Rq 1 "Yes" 0 "No" ;
VAL_ 1112 BattChrgTrgtEvnt_B_Stat 1 "Active" 0 "Inactive" ;
VAL_ 1112 BattTracChrgSustn_B_Rq 1 "Active" 0 "Inactive" ;
VAL_ 1112 HtrnClntPump_D_Stat 3 "Faulty" 2 "No_Data_Exists" 1 "On" 0 "Off" ;
VAL_ 1112 BattTracIsoDis_B_Stat 1 "Yes" 0 "No" ;
VAL_ 1112 BattTrac2_E_Max 4095 "Faulty" 4094 "NoDataExists" ;
VAL_ 1112 BattTracHeat_D_Rq 3 "Faulty" 2 "NotUsed" 1 "On" 0 "Off" ;
VAL_ 1112 BattTracDcFstSustn_B_Rq 1 "Active" 0 "Inactive" ;
VAL_ 1112 BattTracDiagClr_B_Rq 1 "On" 0 "Off" ;
VAL_ 1112 BattTracHazrd_D_Stat 3 "Disabled" 2 "HazardConfirmed" 1 "ExternalMonitoringRequired" 0 "NoHazardDetected" ;
VAL_ 1112 BattTracDelta_Te_Actl 255 "Faulty" 254 "NoDataExists" ;
VAL_ 1112 BattTracClntPmp_D_Stat 3 "Faulty" 2 "No_Data_Exists" 1 "On" 0 "Off" ;
VAL_ 139 AccButtnGpTogglePress2 1 "Pressed" 0 "Not_Pressed" ;
VAL_ 139 TjaButtnOnOffPress2 1 "Pressed" 0 "Not_Pressed" ;
VAL_ 139 ActvFrontSteMsgTxt_D_Rq 7 "Message7" 6 "Message6" 5 "Message5" 4 "Message4" 3 "Message3" 2 "Message2" 1 "Message1" 0 "NoMessage" ;
VAL_ 139 ActvFrontSteLck_D_Stat 3 "Test_passed" 2 "Test_failed" 1 "Test_cannot_run" 0 "Test_incomplete" ;
VAL_ 139 SelDrvMdeAdptSte_D_Stat 3 "Faulty" 2 "TemporarilyNotAvailable" 1 "Available" 0 "NotAvailable" ;
VAL_ 139 AslButtnOnOffPress2 1 "Button_Pressed" 0 "Button_Not_Pressed" ;
VAL_ 139 AslButtnOnOffCnclPres2 1 "Button_Pressed" 0 "Button_Not_Pressed" ;
VAL_ 139 CcButtnOnPress2 1 "Button_Pressed" 0 "Button_Not_Pressed" ;
VAL_ 139 CcButtnOnOffPress2 1 "Button_Pressed" 0 "Button_Not_Pressed" ;
VAL_ 139 CcButtnOnOffCnclPress2 1 "Button_Pressed" 0 "Button_Not_Pressed" ;
VAL_ 139 CcButtnOffPress2 1 "Button_Pressed" 0 "Button_Not_Pressed" ;
VAL_ 139 CcAsllButtnResPress2 1 "Button_Pressed" 0 "Button_Not_Pressed" ;
VAL_ 139 CcAslButtnSetPress2 1 "Button_Pressed" 0 "Button_Not_Pressed" ;
VAL_ 139 CcAslButtnSetIncPress2 1 "Button_Pressed" 0 "Button_Not_Pressed" ;
VAL_ 139 CcAslButtnSetDecPress2 1 "Button_Pressed" 0 "Button_Not_Pressed" ;
VAL_ 139 CcAslButtnResIncPress2 1 "Button_Pressed" 0 "Button_Not_Pressed" ;
VAL_ 139 CcAslButtnResDecPress2 1 "Button_Pressed" 0 "Button_Not_Pressed" ;
VAL_ 139 CcAslButtnOnPress2 1 "Button_Pressed" 0 "Button_Not_Pressed" ;
VAL_ 139 CcAslButtnOnOffCncl2 1 "Button_Pressed" 0 "Button_Not_Pressed" ;
VAL_ 139 CcAslButtnOffCnclPres2 1 "Button_Pressed" 0 "Button_Not_Pressed" ;
VAL_ 139 CcAslButtnIndxIncPres2 1 "Button_Pressed" 0 "Button_Not_Pressed" ;
VAL_ 139 CcAslButtnIndxDecPres2 1 "Button_Pressed" 0 "Button_Not_Pressed" ;
VAL_ 139 CcAslButtnDeny_B_Actl2 1 "Yes" 0 "No" ;
VAL_ 139 CcAslButtnCnclResPres2 1 "Button_Pressed" 0 "Button_Not_Pressed" ;
VAL_ 139 CcAslButtnCnclPress2 1 "Button_Pressed" 0 "Button_Not_Pressed" ;
VAL_ 139 AccButtnGapIncPress2 1 "Button_Pressed" 0 "Button_Not_Pressed" ;
VAL_ 139 AccButtnGapDecPress2 1 "Button_Pressed" 0 "Button_Not_Pressed" ;
VAL_ 139 AfsPw_B_Rq 1 "Yes" 0 "No" ;
VAL_ 1121 OffRdSwtch_D_RqMnu 3 "Faulty" 2 "NoRequest" 1 "On" 0 "Off" ;
VAL_ 1121 SelDrvMdeSwtchOk_D_Stat 3 "Faulty" 2 "Pressed" 1 "NotPressed" 0 "Null" ;
VAL_ 1121 AutoHoldSwtch_D_Stat2 3 "Faulty" 2 "NotUsed" 1 "Pressed" 0 "Not_Pressed" ;
VAL_ 1121 PrkAidSwtch_D_RqDrv3 1 "Pressed" 0 "Not_Pressed" ;
VAL_ 1121 ApaSwtch_D_RqDrv3 3 "NotUsed2" 2 "NotUsed1" 1 "Pressed" 0 "Not_Pressed" ;
VAL_ 1121 StopStrtDrvMde_B_RqBtn2 1 "Pressed" 0 "Not_Pressed" ;
VAL_ 1121 SelDrvMdeSwtch_D_Stat 3 "Faulty" 2 "SwitchState2" 1 "SwitchState1" 0 "NotPressed" ;
VAL_ 1121 SelDrvMdeCnt_D_Stat 4 "FourCounts" 3 "ThreeCounts" 2 "TwoCounts" 1 "OneCount" 0 "ZeroCounts" 7 "SevenOrMoreCounts" 6 "SixCounts" 5 "FiveCounts" ;
VAL_ 1120 StabBarCnncButtn_D_Stat 3 "Faulty" 2 "NotUsed" 1 "Pressed" 0 "Not_Pressed" ;
VAL_ 1120 DrvSlipCtlMde_B_Rq3 1 "Pressed" 0 "Not_Pressed" ;
VAL_ 1120 HybMdeSwtch_B_Rq 1 "Pressed" 0 "Not_Pressed" ;
VAL_ 1120 AwdLck_D_RqDrv 3 "Faulty" 2 "NoRequest" 1 "On" 0 "Off" ;
VAL_ 1120 TrailCtlSwtch_B_Stat3 1 "Pressed" 0 "Not_Pressed" ;
VAL_ 1120 RearDiffLck_D_RqDrv 3 "Faulty" 2 "NoRequest" 1 "On" 0 "Off" ;
VAL_ 1120 AwdMde_D_RqDrv 7 "Faulty" 6 "NotUsed2" 5 "NoRequest" 4 "Neutral" 3 "FourByFourLow" 2 "FourByFourHigh" 1 "FourByFourAuto" 0 "FourByTwo" ;
VAL_ 1120 HdcSwtchPos_B_Actl 1 "Pressed" 0 "Not_Pressed" ;
VAL_ 1120 FrontDiffLck_D_RqDrv 3 "Faulty" 2 "NoRequest" 1 "On" 0 "Off" ;
VAL_ 1050 CamraRearBttn_D_Stat 1 "Pressed" 0 "Not_Pressed" ;
VAL_ 1050 TrailCtlSwtch_B_Stat 1 "Pressed" 0 "Not_Pressed" ;
VAL_ 1050 AutoHoldSwtch_D_Stat 3 "Faulty" 2 "NotUsed" 1 "Pressed" 0 "Not_Pressed" ;
VAL_ 1050 EcoInhbt_B_RqHvac 1 "Yes" 0 "No" ;
VAL_ 1050 LpdbPtc3_B_Rq 1 "On" 0 "Off" ;
VAL_ 1050 LpdbPtc2_B_Rq 1 "On" 0 "Off" ;
VAL_ 1050 LpdbPtc1_B_Rq 1 "On" 0 "Off" ;
VAL_ 1050 LpdbHeatWiprPrk_B_Rq 1 "On" 0 "Off" ;
VAL_ 1050 LpdbDfrstRearOn_B_Rq 1 "On" 0 "Off" ;
VAL_ 1050 LpdbDfrstFrOn_B_Rq 1 "On" 0 "Off" ;
VAL_ 1050 LpdbDfrstFlOn_B_Rq 1 "On" 0 "Off" ;
VAL_ 1050 LpdbAuxBlwr_B_Rq 1 "On" 0 "Off" ;
VAL_ 1050 PrkAidSwtch_D_RqDrv 1 "Pressed" 0 "Not_Pressed" ;
VAL_ 1050 SteWhlHeat_D_Rq 15 "NotUsed6" 14 "NotUsed5" 13 "NotUsed4" 12 "NotUsed3" 11 "NotUsed2" 10 "NotUsed1" 9 "Reserved_3" 8 "Reserved_2" 7 "Reserved_1" 6 "Level_3_Heating" 5 "Level_3_Heating_LS" 4 "Level_2_Heating" 3 "Level_2_Heating_LS" 2 "Level_1_Heating" 1 "Level_1_Heating_LS" 0 "Off" ;
VAL_ 1050 MirrorHeatOn_B_Rq 1 "True" 0 "False" ;
VAL_ 1050 Remote_Start_QuietMode 1 "Quiet" 0 "Not_Quiet" ;
VAL_ 1050 DrvSlipCtlMde_B_Rq 1 "Pressed" 0 "Not_Pressed" ;
VAL_ 1050 Outside_Air_Temp_Stat 255 "Invalid" 254 "Unknown" ;
VAL_ 1050 CamraFrntBttn_D_Stat 1 "Pressed" 0 "Not_Pressed" ;
VAL_ 621 IgnPsswrdActv_B_Stat 1 "Active" 0 "Inactive" ;
VAL_ 621 FobTrgtZone_D_Rq 15 "NotUsed_9" 14 "NotUsed_8" 13 "NotUsed_7" 12 "NotUsed_6" 11 "NotUsed_5" 10 "NotUsed_4" 9 "NotUsed_3" 8 "NotUsed_2" 7 "NotUsed_1" 6 "Approach" 5 "RearInterior" 4 "RearExterior" 3 "Passenger" 2 "Driver" 1 "Interior" 0 "Null" ;
VAL_ 621 FobTrgtType_D_Rq 7 "NotUsed_4" 6 "NotUsed_3" 5 "NotUsed_2" 4 "NotUsed_1" 3 "Polling" 2 "Registry" 1 "Crypto" 0 "Null" ;
VAL_ 621 RmtCtlSelSlot_D_Rq 7 "NotUsed_3" 6 "NotUsed_2" 5 "NotUsed_1" 4 "Right" 3 "Left" 2 "Rear" 1 "Front" 0 "None" ;
VAL_ 621 RmtCtlSelPrkMde_D_Rq 3 "NotUsed" 2 "FreeDrive" 1 "ParkIn" 0 "None" ;
VAL_ 621 RmtCtlSelMoveDir_D_Rq 3 "NotUsed" 2 "Backward" 1 "Forward" 0 "None" ;
VAL_ 621 RmtCtlRjctAutoCfg_B_Rq 1 "Yes" 0 "No" ;
VAL_ 1124 GPS_Vdop 31 "Invalid" 30 "Unknown" ;
VAL_ 1124 GPS_Speed 255 "Invalid" 254 "Unknown" ;
VAL_ 1124 GPS_Sat_num_in_view 31 "Invalid" 30 "Unknown" ;
VAL_ 1124 GPS_MSL_altitude 4095 "Fault" 4094 "Unknown" ;
VAL_ 1124 GPS_Heading 65535 "Fault" 65534 "Unknown" ;
VAL_ 1124 GPS_Hdop 31 "Invalid" 30 "Unknown" ;
VAL_ 1124 GPS_dimension 2 "_3D" 1 "_2D" 0 "No_Fix" ;
VAL_ 1137 RngPerChrgLbl_L_Dsply 4095 "Faulty" 4094 "NoDataExists" ;
VAL_ 1137 RngPerChrgAvg_L_Dsply 4095 "Faulty" 4094 "NoDataExists" ;
VAL_ 1137 RngImpctTot_Pc_Dsply 1023 "Faulty" ;
VAL_ 1137 RngImpctExt_Pc_Dsply 1023 "Faulty" ;
VAL_ 1137 RngImpctDrv_Pc_Dsply 1023 "Faulty" ;
VAL_ 1137 RngImpctClim_Pc_Dsply 1023 "Faulty" ;
VAL_ 1255 BalrRight4Threat_D_Stat 1 "Yes" 0 "No" ;
VAL_ 1255 BalrRight4Fast_B_Stat 1 "Yes" 0 "No" ;
VAL_ 1255 BalrRight4Dsply_B_Stat 1 "Yes" 0 "No" ;
VAL_ 1254 BalrRight3Threat_D_Stat 1 "Yes" 0 "No" ;
VAL_ 1254 BalrRight3Fast_B_Stat 1 "Yes" 0 "No" ;
VAL_ 1254 BalrRight3Dsply_B_Stat 1 "Yes" 0 "No" ;
VAL_ 1253 BalrRight2Threat_D_Stat 1 "Yes" 0 "No" ;
VAL_ 1253 BalrRight2Fast_B_Stat 1 "Yes" 0 "No" ;
VAL_ 1253 BalrRight2Dsply_B_Stat 1 "Yes" 0 "No" ;
VAL_ 1252 BalrRight1Threat_D_Stat 1 "Yes" 0 "No" ;
VAL_ 1252 BalrRight1Fast_B_Stat 1 "Yes" 0 "No" ;
VAL_ 1252 BalrRight1Dsply_B_Stat 1 "Yes" 0 "No" ;
VAL_ 1251 BalrLeft4Threat_D_Stat 1 "Yes" 0 "No" ;
VAL_ 1251 BalrLeft4Fast_B_Stat 1 "Yes" 0 "No" ;
VAL_ 1251 BalrLeft4Dsply_B_Stat 1 "Yes" 0 "No" ;
VAL_ 1250 BalrLeft3Threat_D_Stat 1 "Yes" 0 "No" ;
VAL_ 1250 BalrLeft3Fast_B_Stat 1 "Yes" 0 "No" ;
VAL_ 1250 BalrLeft3Dsply_B_Stat 1 "Yes" 0 "No" ;
VAL_ 1249 BalrLeft2Threat_D_Stat 1 "Yes" 0 "No" ;
VAL_ 1249 BalrLeft2Fast_B_Stat 1 "Yes" 0 "No" ;
VAL_ 1249 BalrLeft2Dsply_B_Stat 1 "Yes" 0 "No" ;
VAL_ 1248 BalrLeft1Threat_D_Stat 1 "Yes" 0 "No" ;
VAL_ 1248 BalrLeft1Fast_B_Stat 1 "Yes" 0 "No" ;
VAL_ 1248 BalrLeft1Dsply_B_Stat 1 "Yes" 0 "No" ;
VAL_ 1113 TrlrTrgtAcquire_D_Stat 7 "Faulty" 6 "NotUsed_2" 5 "NotUsed_1" 4 "RVCforTBA_Activated" 3 "Processing" 2 "TargetNotAcquired" 1 "TargetAcquired" 0 "Null" ;
VAL_ 1113 TrlrAnOffstDir_D_Calc 3 "NotUSed" 2 "Right" 1 "Left_or_Center" 0 "Null" ;
VAL_ 1113 TrlrAnCalib_B_Complt 1 "Yes" 0 "No" ;
VAL_ 1113 TrlrRvrse_D_Stat 3 "Faulty" 2 "TrailerReverseGuidanceLite" 1 "On" 0 "Off" ;
VAL_ 1113 TrlrAid_D2_Stat 15 "Faulty" 14 "NotUsed_4" 13 "NotUsed_3" 12 "NotUsed_2" 11 "NotUsed_1" 10 "DirtyCamera" 9 "IncorrectLighting" 8 "TrackingLost" 7 "TrackingUnknownConfidence" 6 "TrackingHighConfidence" 5 "TrackingMediumConfidence" 4 "TrackingLowConfidence" 3 "TurnRequested" 2 "DriveStraighRequested" 1 "Initializing" 0 "NotTracking" ;
VAL_ 1113 TrlrAid_An3_Actl 2047 "Faulty" ;
VAL_ 1113 TrlrAid_AnRate2_Actl 1023 "Faulty" ;
VAL_ 1113 HitchToVehAxle_L_Calc 255 "Faulty" ;
VAL_ 1105 ClrExitAsstMsgTxt2_D_Rq 15 "NotUsed_7" 14 "NotUsed_6" 13 "NotUsed_5" 12 "NotUsed_4" 11 "NotUsed_3" 10 "NotUsed_2" 9 "NotUsed_1" 8 "FrontLeftRearRight" 7 "RearLeftFrontRight" 6 "FrontLeftFrontRight" 5 "RearLeftRearRight" 4 "FrontRight" 3 "FrontLeft" 2 "RearRight" 1 "RearLeft" 0 "NoMessage" ;
VAL_ 1105 ClrExitAsstActv_B_Rq 1 "Active" 0 "Inactive" ;
VAL_ 1105 TrlrRvrseMsgTxt_D2_Rq 31 "Message31" 30 "Message30" 29 "Message29" 28 "Message28" 27 "Message27" 26 "Message26" 25 "Message25" 24 "Message24" 23 "Message23" 22 "Message22" 21 "Message21" 20 "Message20" 19 "Message19" 18 "Message18" 17 "Message17" 16 "Message16" 15 "Message15" 14 "Message14" 13 "Message13" 12 "Message12" 11 "Message11" 10 "Message10" 9 "Message9" 8 "Message8" 7 "Message7" 6 "Message6" 5 "Message5" 4 "Message4" 3 "Message3" 2 "Message2" 1 "Message1" 0 "NoMessage" 63 "Message63" 47 "Message47" ;
VAL_ 1105 TrlrRvrseEnbl_D2_Stat 7 "NotUsed" 6 "TbaActiveExpertActive" 5 "TbaActiveExpertAvail" 4 "TbaOffTrgActive" 3 "TbaOffTrgSetup" 2 "TbaSetup" 1 "TbaActive" 0 "Inactive" ;
VAL_ 1105 RbaMsg_D_Rq 3 "Faulty" 2 "Unavailable" 1 "Off" 0 "Null" ;
VAL_ 1105 BrkDecel_B_RqRba 1 "Enable" 0 "Disable" ;
VAL_ 1105 BrkEnbl_B_RqRba 1 "Enable" 0 "Disable" ;
VAL_ 1105 Rba_D_Stat 3 "NotUsed" 2 "Disabled" 1 "On" 0 "Off" ;
VAL_ 1105 RbaAlrt_D_Dsply 3 "Both" 2 "Text" 1 "Graphic" 0 "Off" ;
VAL_ 1105 RbaMnu_D_Rq 3 "NotUsed" 2 "Active" 1 "Inactive" 0 "None" ;
VAL_ 1105 CamraFrntStat_D_Stat 3 "No_Data_Present" 2 "NotUsed" 1 "On" 0 "Off" ;
VAL_ 1105 TrlrHitchLamp_D_Rq2 1 "On" 0 "Off" ;
VAL_ 1105 CamraFrntOffRd_B_Stat 1 "Active" 0 "Inactive" ;
VAL_ 1105 TrlrAidSwtchLamp_B_Rq 1 "On" 0 "Off" ;
VAL_ 1105 TrlrAidEnbl_D_RqAdas 7 "NotUsed_4" 6 "NotUsed_3" 5 "NotUsed_2" 4 "NotUsed_1" 3 "Deactivate" 2 "NotAvailable" 1 "ActiveTba" 0 "Inactive" ;
VAL_ 1105 TrlrHitchMsgTxt_D_Rq 31 "Message31" 30 "Message30" 29 "Message29" 28 "Message28" 27 "Message27" 26 "Message26" 25 "Message25" 24 "Message24" 23 "Message23" 22 "Message22" 21 "Message21" 20 "Message20" 19 "Message19" 18 "Message18" 17 "Message17" 16 "Message16" 15 "Message15" 14 "Message14" 13 "Message13" 12 "Message12" 11 "Message11" 10 "Message10" 9 "Message9" 8 "Message8" 7 "Message7" 6 "Message6" 5 "Message5" 4 "Message4" 3 "Message3" 2 "Message2" 1 "Message1" 0 "NoMessage" 63 "Message63" 47 "Message47" ;
VAL_ 1105 TrlrHitchIcon_D_Rq 15 "Icon15" 14 "Icon14" 13 "Icon13" 12 "Icon12" 11 "Icon11" 10 "Icon10" 9 "Icon9" 8 "Icon8" 7 "Icon7" 6 "Icon6" 5 "Icon5" 4 "Icon4" 3 "Icon3" 2 "Icon2" 1 "Icon1" 0 "NoIcon" ;
VAL_ 1105 TrlrHitchChime_D_Rq 7 "NotUsed_1" 6 "NotUsed_1" 5 "WarningChime" 4 "NonCriticalAlertChime" 3 "StopNowChime" 2 "ManeuveringReadyChime" 1 "TrailerFoundChime" 0 "NoChime" ;
VAL_ 938 SidePrkSnsR2_D_Stat 15 "NotUsed" 14 "NotFullyScannedYet" 13 "NoObjectInSector" 12 "Zone12" 11 "Zone11" 10 "Zone10" 9 "Zone9" 8 "Zone8" 7 "Zone7" 6 "Zone6" 5 "Zone5" 4 "Zone4" 3 "Zone3" 2 "Zone2" 1 "Zone1" 0 "Off" ;
VAL_ 938 SidePrkSnsR1_D_Stat 15 "NotUsed" 14 "NotFullyScannedYet" 13 "NoObjectInSector" 12 "Zone12" 11 "Zone11" 10 "Zone10" 9 "Zone9" 8 "Zone8" 7 "Zone7" 6 "Zone6" 5 "Zone5" 4 "Zone4" 3 "Zone3" 2 "Zone2" 1 "Zone1" 0 "Off" ;
VAL_ 938 SidePrkSnsL2_D_Stat 15 "NotUsed" 14 "NotFullyScannedYet" 13 "NoObjectInSector" 12 "Zone12" 11 "Zone11" 10 "Zone10" 9 "Zone9" 8 "Zone8" 7 "Zone7" 6 "Zone6" 5 "Zone5" 4 "Zone4" 3 "Zone3" 2 "Zone2" 1 "Zone1" 0 "Off" ;
VAL_ 938 ApaMde_D_Stat 7 "NotUsed" 6 "RePA" 5 "ParkIn" 4 "POA" 3 "PPA" 2 "SAPP" 1 "Off" 0 "Null" ;
VAL_ 938 ApaActvSd_D_Actl 3 "Dirver_Side" 2 "Passenger_Side" 1 "No_Side" 0 "Null" ;
VAL_ 938 PrkAidSwtch_B_Stat 1 "Pressed" 0 "Not_Pressed" ;
VAL_ 938 ApaMde_D_Avail 15 "NotUsed7" 14 "NotUsed6" 13 "NotUsed5" 12 "NotUsed4" 11 "NotUsed3" 10 "NotUsed2" 9 "NotUsed1" 8 "PPA_POA" 7 "SAPP_POA" 6 "POA" 5 "PPA" 4 "SAPP" 3 "SAPP_PPA_POA" 2 "SAPP_PPA" 1 "None" 0 "Null" ;
VAL_ 938 PrkAidSnsFrCrnr_D_Stat 15 "Zone_15" 14 "Zone_14" 13 "Zone_13" 12 "Zone_12" 11 "Zone_11" 10 "Zone_10" 9 "Zone_9" 8 "Zone_8" 7 "Zone_7" 6 "Zone_6" 5 "Zone_5" 4 "Zone_4" 3 "Zone_3" 2 "Zone_2" 1 "Zone_1" 0 "Off" ;
VAL_ 938 PrkAidSnsFrCntr_D_Stat 15 "Zone_15" 14 "Zone_14" 13 "Zone_13" 12 "Zone_12" 11 "Zone_11" 10 "Zone_10" 9 "Zone_9" 8 "Zone_8" 7 "Zone_7" 6 "Zone_6" 5 "Zone_5" 4 "Zone_4" 3 "Zone_3" 2 "Zone_2" 1 "Zone_1" 0 "Off" ;
VAL_ 938 PrkAidSnsFlCrnr_D_Stat 15 "Zone_15" 14 "Zone_14" 13 "Zone_13" 12 "Zone_12" 11 "Zone_11" 10 "Zone_10" 9 "Zone_9" 8 "Zone_8" 7 "Zone_7" 6 "Zone_6" 5 "Zone_5" 4 "Zone_4" 3 "Zone_3" 2 "Zone_2" 1 "Zone_1" 0 "Off" ;
VAL_ 938 PrkAidSnsFlCntr_D_Stat 15 "Zone_15" 14 "Zone_14" 13 "Zone_13" 12 "Zone_12" 11 "Zone_11" 10 "Zone_10" 9 "Zone_9" 8 "Zone_8" 7 "Zone_7" 6 "Zone_6" 5 "Zone_5" 4 "Zone_4" 3 "Zone_3" 2 "Zone_2" 1 "Zone_1" 0 "Off" ;
VAL_ 938 PrkBrkEl_B_RqFap 1 "Yes" 0 "No" ;
VAL_ 938 RpaChime_D_Rq 15 "Zone15_Chime" 14 "Zone14_Chime" 13 "Zone13_Chime" 12 "Zone12_Chime" 11 "Zone11_Chime" 10 "Zone10_Chime" 9 "Zone9_Chime" 8 "Zone8_Chime" 7 "Zone7_Chime" 6 "Zone6_Chime" 5 "Zone5_Chime" 4 "Zone4_Chime" 3 "Zone3_Chime" 2 "Zone2_Chime" 1 "Zone1_Chime" 0 "No_Chime" ;
VAL_ 938 FpaChime_D_Rq 15 "Zone15_Chime" 14 "Zone14_Chime" 13 "Zone13_Chime" 12 "Zone12_Chime" 11 "Zone11_Chime" 10 "Zone10_Chime" 9 "Zone9_Chime" 8 "Zone8_Chime" 7 "Zone7_Chime" 6 "Zone6_Chime" 5 "Zone5_Chime" 4 "Zone4_Chime" 3 "Zone3_Chime" 2 "Zone2_Chime" 1 "Zone1_Chime" 0 "No_Chime" ;
VAL_ 938 PrkAidMsgTxt_D_Rq 15 "All_Sns_Blk" 14 "R_Sns_ON_F_Sns_Blk" 13 "R_Sns_Blk_F_Sns_ON" 12 "R_Sns_Inactive_Trlr_atch" 11 "Not_Avail_Trlr_attchd" 10 "Fail_Mode_no_Chime" 9 "Fail_Mode_with_Chime" 8 "R_Sns_Trlr_F_Sns_Blk" 7 "NotUsed3" 6 "Park_Sys_Alternate_Mode" 5 "R_Snsrs_On_F_Snsrs_On" 4 "NotUsed2" 3 "Reset_Message_Warn" 2 "R_Snsrs_Off_F_Snsrs_On" 1 "R_Snsrs_On_F_Snsrs_Off" 0 "All_Park_Sensors_Off" ;
VAL_ 938 SidePrkSnsL1_D_Stat 15 "NotUsed" 14 "NotFullyScannedYet" 13 "NoObjectInSector" 12 "Zone12" 11 "Zone11" 10 "Zone10" 9 "Zone9" 8 "Zone8" 7 "Zone7" 6 "Zone6" 5 "Zone5" 4 "Zone4" 3 "Zone3" 2 "Zone2" 1 "Zone1" 0 "Off" ;
VAL_ 938 PrkAidAudioMute_B_Rq 1 "Enable" 0 "Disable" ;
VAL_ 939 SidePrkSnsR4_D_Stat 15 "NotUsed" 14 "NotFullyScannedYet" 13 "NoObjectInSector" 12 "Zone12" 11 "Zone11" 10 "Zone10" 9 "Zone9" 8 "Zone8" 7 "Zone7" 6 "Zone6" 5 "Zone5" 4 "Zone4" 3 "Zone3" 2 "Zone2" 1 "Zone1" 0 "Off" ;
VAL_ 939 SidePrkSnsR3_D_Stat 15 "NotUsed" 14 "NotFullyScannedYet" 13 "NoObjectInSector" 12 "Zone12" 11 "Zone11" 10 "Zone10" 9 "Zone9" 8 "Zone8" 7 "Zone7" 6 "Zone6" 5 "Zone5" 4 "Zone4" 3 "Zone3" 2 "Zone2" 1 "Zone1" 0 "Off" ;
VAL_ 939 SidePrkSnsL4_D_Stat 15 "NotUsed" 14 "NotFullyScannedYet" 13 "NoObjectInSector" 12 "Zone12" 11 "Zone11" 10 "Zone10" 9 "Zone9" 8 "Zone8" 7 "Zone7" 6 "Zone6" 5 "Zone5" 4 "Zone4" 3 "Zone3" 2 "Zone2" 1 "Zone1" 0 "Off" ;
VAL_ 939 SidePrkSnsL3_D_Stat 15 "NotUsed" 14 "NotFullyScannedYet" 13 "NoObjectInSector" 12 "Zone12" 11 "Zone11" 10 "Zone10" 9 "Zone9" 8 "Zone8" 7 "Zone7" 6 "Zone6" 5 "Zone5" 4 "Zone4" 3 "Zone3" 2 "Zone2" 1 "Zone1" 0 "Off" ;
VAL_ 939 PrkAidChime_D_Stat 3 "Fault" 2 "No_Data_Exists" 1 "On" 0 "Off" ;
VAL_ 939 PrkAidSnsRlCntr_D_Stat 15 "Zone_15" 14 "Zone_14" 13 "Zone_13" 12 "Zone_12" 11 "Zone_11" 10 "Zone_10" 9 "Zone_9" 8 "Zone_8" 7 "Zone_7" 6 "Zone_6" 5 "Zone_5" 4 "Zone_4" 3 "Zone_3" 2 "Zone_2" 1 "Zone_1" 0 "Off" ;
VAL_ 939 PrkAidSnsRrCrnr_D_Stat 15 "Zone_15" 14 "Zone_14" 13 "Zone_13" 12 "Zone_12" 11 "Zone_11" 10 "Zone_10" 9 "Zone_9" 8 "Zone_8" 7 "Zone_7" 6 "Zone_6" 5 "Zone_5" 4 "Zone_4" 3 "Zone_3" 2 "Zone_2" 1 "Zone_1" 0 "Off" ;
VAL_ 939 PrkAidSnsRrCntr_D_Stat 15 "Zone_15" 14 "Zone_14" 13 "Zone_13" 12 "Zone_12" 11 "Zone_11" 10 "Zone_10" 9 "Zone_9" 8 "Zone_8" 7 "Zone_7" 6 "Zone_6" 5 "Zone_5" 4 "Zone_4" 3 "Zone_3" 2 "Zone_2" 1 "Zone_1" 0 "Off" ;
VAL_ 939 PrkAidSnsRlCrnr_D_Stat 15 "Zone_15" 14 "Zone_14" 13 "Zone_13" 12 "Zone_12" 11 "Zone_11" 10 "Zone_10" 9 "Zone_9" 8 "Zone_8" 7 "Zone_7" 6 "Zone_6" 5 "Zone_5" 4 "Zone_4" 3 "Zone_3" 2 "Zone_2" 1 "Zone_1" 0 "Off" ;
VAL_ 939 PrkAidRear_D_Stat 3 "Faulted" 2 "Unused" 1 "Enabled" 0 "Disabled" ;
VAL_ 939 PrkAidFront_D_Stat 3 "Faulted" 2 "Unused" 1 "Enabled" 0 "Disabled" ;
VAL_ 939 PrkAid_D_Falt 7 "NotUsed2" 6 "NotUsed1" 5 "Failure_Front_PSM_Sensors" 4 "No_Data_Exists" 3 "Failure_Rear_Sensors" 2 "Speaker_Fault" 1 "ECU_Fault" 0 "No_Fault" ;
VAL_ 939 ApaLongCtrlEnbl_D_Rq 1 "Enable" 0 "Disable" ;
VAL_ 939 PrkAidLamp_D_Rq 3 "Not_Used" 2 "Flash" 1 "On" 0 "Off" ;
VAL_ 939 ApaBrk_D_Rq 3 "NotUsed" 2 "LowDecel" 1 "HighDecel" 0 "NoRequest" ;
VAL_ 937 TrnRng_D_RqFap 7 "NotUsed3" 6 "NotUsed2" 5 "NotUsed1" 4 "Backwards" 3 "Forwards" 2 "NoMotion" 1 "Immobilize" 0 "NoRequest" ;
VAL_ 937 FapLcDistToObj_L_Actl 255 "Faulty" 254 "NoDataExists" ;
VAL_ 936 ApaSys_D_Stat 7 "Faulty" 6 "Finished" 5 "NotAccessible" 4 "ApaCancelled" 3 "Overspeed" 2 "On" 1 "Off" 0 "Null" ;
VAL_ 936 ApaSteWhl_D_RqDrv 3 "TakeControl" 2 "RemoveHands" 1 "NoRequest" 0 "Null" ;
VAL_ 936 ApaSteScanMde_D_Stat 3 "Steering" 2 "Scanning" 1 "NotScanning" 0 "Null" ;
VAL_ 936 ApaSelSapp_D_Stat 3 "NotConfigured" 2 "NotSelectable" 1 "Selectable" 0 "Null" ;
VAL_ 936 ApaSelPpa_D_Stat 3 "NotConfigured" 2 "NotSelectable" 1 "Selectable" 0 "Null" ;
VAL_ 936 ApaSelPoa_D_Stat 3 "NotConfigured" 2 "NotSelectable" 1 "Selectable" 0 "Null" ;
VAL_ 936 ApaScan_D_Stat 3 "ParkSlotReady" 2 "ParkSlotFound" 1 "NoParkSlot" 0 "Null" ;
VAL_ 936 ApaLongCtl_D_RqDrv 7 "NotUsed3" 6 "NotUsed2" 5 "ReleaseBrake" 4 "DriveBackward" 3 "DriveForward" 2 "Stop" 1 "NoRequest" 0 "Null" ;
VAL_ 936 ApaGearShif_D_RqDrv 7 "NotUSed2" 6 "NotUsed1" 5 "ShiftToP" 4 "ShiftToN" 3 "ShiftToD" 2 "ShiftToR" 1 "NoRequest" 0 "Null" ;
VAL_ 936 ApaActvSide2_D_Stat 3 "NoSide" 2 "Right" 1 "Left" 0 "Null" ;
VAL_ 936 ApaAcsy_D_RqDrv 7 "CloseDoor" 6 "SelectSideRight" 5 "SelectSideLeft" 4 "CheckForObject" 3 "PressApaButton" 2 "SelectSide" 1 "NoRequest" 0 "Null" ;
VAL_ 936 ApaTrgtDist_D_Stat 15 "Step15" 14 "Step14" 13 "Step13" 12 "Step12" 11 "Step11" 10 "Step10" 9 "Step9" 8 "Step8" 7 "Step7" 6 "Step6" 5 "Step5" 4 "Step4" 3 "Step3" 2 "Step2" 1 "Step1" 0 "Off" ;
VAL_ 936 ApaMsgTxt_D_Rq 15 "NotUsed_6" 14 "NotUsed_5" 13 "NotUsed_4" 12 "NotUsed_3" 11 "ReleaseEpb" 10 "TrailerFeatureNotAvailable" 9 "AccelPedalInactive" 8 "WrongDirection" 7 "SteeringInteraction" 6 "BrakingActive" 5 "HighInclination" 4 "SpeedLimitExceeded" 3 "TcsDisabled" 2 "WheelSlip" 1 "None" 0 "Null" ;
VAL_ 936 ApaChime_D_Rq 7 "NotUsed2" 6 "NotUsed1" 5 "Warning_Chime" 4 "Finish_Chime" 3 "Stop_Now_Chime" 2 "Spot_Ready_Chime" 1 "Spot_Found_Chime" 0 "No_Chime" ;
VAL_ 936 EPASExtAngleStatReq 1 "Request" 0 "NoRequest" ;
VAL_ 936 ExtSteeringAngleReq2 32767 "Invalid" 32766 "Unknown" ;
VAL_ 936 ApaButtnPrssd_B_Stat 1 "Pressed" 0 "Not_Pressed" ;
VAL_ 877 VehElEffAvg_No_Dsply 127 "Faulty" 126 "NoDataExists" ;
VAL_ 877 PwFlwFuelDrv_D_Dsply 7 "NotUsed_4" 6 "NotUsed_3" 5 "NotUsed_2" 4 "NotUsed_1" 3 "FlwFromFuelToAllWhls" 2 "FlwFromFuelToFrontWhls" 1 "FlwFromFuelToRearWhls" 0 "NoFlow" ;
VAL_ 877 PwFlwFuelClimt_B_Dsply 1 "On" 0 "Off" ;
VAL_ 877 PwFlwFuelBatt_B_Dsply 1 "On" 0 "Off" ;
VAL_ 877 PwFlwBattGen_D_Dsply 1 "On" 0 "Off" ;
VAL_ 877 PwFlwBattClimt_B_Dsply 1 "On" 0 "Off" ;
VAL_ 877 PwFlwBatt_D_Dsply 15 "NotUsed_8" 14 "NotUsed_7" 13 "NotUsed_6" 12 "NotUsed_5" 11 "NotUsed_4" 10 "NotUsed_3" 9 "NotUsed_2" 8 "NotUsed_1" 7 "FlwFromWallToBatt" 6 "FlwFromAllWhlsToBatt" 5 "FlwFromBattToAllWhls" 4 "FlwFromFrontWhlsToBatt" 3 "FlwFromBattToFrontWhls" 2 "FlwFromRearWhlsToBatt" 1 "FlwFromBattToRearWhls" 0 "NoFlow" ;
VAL_ 791 AwdDrvMde_D2_Rq 15 "Faulty" 14 "NotUsed_7" 13 "NotUsed_6" 12 "NotUsed_5" 11 "NotUsed_4" 10 "NotUsed_3" 9 "NotUsed_2" 8 "NotUsed_1" 7 "NotAvailable" 6 "TowHaul" 5 "RockCrawl" 4 "Baja" 3 "MudAndSand" 2 "Weather" 1 "Sport" 0 "Normal" ;
VAL_ 791 StopStrtVThres_D_RqMnu 3 "High" 2 "Medium" 1 "Low" 0 "NoSelection" ;
VAL_ 791 EngAirFilt_B_RqReset 1 "Yes" 0 "No" ;
VAL_ 791 BattElEmotive_Pc_Dsply 1023 "Faulty" 1022 "NoDataExists" ;
VAL_ 791 HybMdeOvrrd_D_Rq 3 "NotUsed" 2 "Invalid" 1 "Override" 0 "Null" ;
VAL_ 791 GpsElMdeSel_B_Rq 1 "On" 0 "Off" ;
VAL_ 791 LongTermReset_B_Rq 1 "On" 0 "Off" ;
VAL_ 791 EcoCcActv_B_Rq 1 "On" 0 "Off" ;
VAL_ 791 DrvEffLvl_No_Stat 63 "Fault" 62 "NoDataExists" ;
VAL_ 791 ChargeProfIDPref_Rq 3 "NotUsed" 2 "Value" 1 "ChargeNow" 0 "Inactive" ;
VAL_ 791 GrdAsstAllw_D_RqMnu 3 "NotUsed" 2 "On" 1 "Off" 0 "NoModeSelected" ;
VAL_ 791 PlgOvrrdStrt_D_Cmd 3 "NotUsed" 2 "Override_Plug_Status" 1 "Dont_Override_Plug_Status" 0 "Null_State" ;
VAL_ 791 EcoMde_D_RqMnu 3 "NotUsed" 2 "On" 1 "Off" 0 "Null" ;
VAL_ 791 EmotiveType_D_Dsply 3 "EmotiveDisplay_3" 2 "EmotiveDisplay_2" 1 "EmotiveDisplay_1" 0 "Null" ;
VAL_ 791 VehElEffTrip2Reset_B_Rq 1 "On" 0 "Off" ;
VAL_ 791 VehElEffTrip1Reset_B_Rq 1 "On" 0 "Off" ;
VAL_ 786 VehElRnge_L2_Dsply 8191 "Faulty" 8190 "NoDataExists" ;
VAL_ 786 VehElRngeCyc_L_Dsply 4095 "Faulty" 4094 "NoDataExists" ;
VAL_ 786 RgenTrip_L_Dsply 65535 "Fault" 65534 "NoDataExists" ;
VAL_ 786 PtDataKeyId_D_Stat 15 "NotUsed5" 14 "NotUsed4" 13 "NotUsed3" 12 "NotUsed2" 11 "NotUsed1" 10 "Tot_Veh_NUT" 9 "Cust_4_NUT" 8 "Cust_3_NUT" 7 "Cust_2_NUT" 6 "Cust_1_NUT" 5 "Tot_Veh_Stat" 4 "Cust_4_Stat" 3 "Cust_3_Stat" 2 "Cust_2_Stat" 1 "Cust_1_Stat" 0 "Null" ;
VAL_ 748 ChrgrOutHi_U_Actl 511 "Invalid" ;
VAL_ 748 ChrgrOutHi_I_Actl 4095 "Invalid" ;
VAL_ 748 ChrgrInPwType_D_Actl 6 "NotUsed3" 5 "NotUsed2" 4 "NotUsed1" 3 "DC_Fast_Charging" 2 "AC_Level2_240v" 1 "AC_Level1_120v" 0 "EVSE_Not_Detected" ;
VAL_ 748 ChrgrIn_Pw_Mx 4095 "Fault" ;
VAL_ 748 PtWakeupActv3_B_Rq 1 "On" 0 "Off" ;
VAL_ 748 PlgActv_D_ActlChrgr 3 "Faulty" 2 "NoDataExists" 1 "On_Plug__Connected_" 0 "Off_Plug__Disconnected_" ;
VAL_ 748 ChrgrRdyStat_D_Actl 7 "NotUsed4" 6 "NotUsed3" 5 "NotUsed2" 4 "NotUsed1" 3 "Charging" 2 "ChargerFault" 1 "ChargerReady" 0 "NotReady" ;
VAL_ 740 BattDcChrg_U_Actl 1023 "Faulty" 1022 "NoDataExists" ;
VAL_ 740 BattChrgMde_D_Actl 3 "NotUsed" 2 "ConstantCurrent" 1 "ConstantVoltage" 0 "NotCharging" ;
VAL_ 740 BattAuxCnnct_B_Cmd 1 "Close" 0 "Open" ;
VAL_ 740 PtWakeupActv2_B_Rq 1 "On" 0 "Off" ;
VAL_ 740 BattChrgCnnct_B_Cmd 1 "Close" 0 "Open" ;
VAL_ 589 DcdcUHi2_I_Actl 2047 "Faulty" ;
VAL_ 588 HvacAirFlw_B_RqBatt 1 "Request" 0 "NoRequest" ;
VAL_ 588 BattChrgRdyStat_D_Actl 7 "NotUsed2" 6 "NotUsed1" 5 "Faulted" 4 "ChargeComplete" 3 "Charging" 2 "BatteryChargeReady" 1 "ChargeWait" 0 "NotReady" ;
VAL_ 588 BattTracSoc2_Pc_Actl 16383 "Faulty" 16382 "NoDataExists" ;
VAL_ 588 BattTracSoc_Pc_Dsply 255 "Faulty" 254 "NoDataExists" ;
VAL_ 588 BattTracCool_D_Falt 3 "NotUsed" 2 "CoolSysPartialyOperational" 1 "Cooling_System_Faulted" 0 "Cooling_System_Operational" ;
VAL_ 588 BattTracClntIn_Te_Actl 255 "Fault" ;
VAL_ 588 BattTrac_Te_Actl 1023 "Fault" 1022 "Unknown" ;
VAL_ 588 HvacRec_D_RqMxBatt 15 "NotUsed5" 14 "NotUsed4" 13 "NotUsed3" 12 "NotUsed2" 11 "NotUsed1" 10 "No_Override" 9 "90Percent_RecircMax" 8 "80Percent_RecircMax" 7 "70Percent_RecircMax" 6 "60Percent_RecircMax" 5 "50Percent_RecircMax" 4 "40Percent_RecircMax" 3 "30Percent_RecircMax" 2 "20Percent_RecircMax" 1 "10Percent_RecircMax" 0 "0Percent_RecircFullOpen" ;
VAL_ 588 HvacAir_Flw_EstBatt 255 "Invalid" ;
VAL_ 587 BattTracClnt_Te_Actl 255 "Faulty" 254 "NoDataExists" ;
VAL_ 587 PwSrcULoMde_D_Actl 3 "BuckSpecial" 2 "ReverseBoost" 1 "ForwardBuck" 0 "Standby" ;
VAL_ 587 BattTracWarnLamp_B_Rq 1 "On" 0 "Off" ;
VAL_ 587 BattTracSrvcRqd_B_Rq 1 "On" 0 "Off" ;
VAL_ 389 HtrnOvrTeLamp_B_Dsply 1 "On" 0 "Off" ;
VAL_ 389 HtrnMil_D_Rq 3 "Not_Used" 2 "Flash" 1 "On" 0 "Off" ;
VAL_ 389 HtrnAin_UHi_Actl 1023 "Fault" 1022 "Unknown" ;
VAL_ 389 HtrnSrvcRqd_B_Dsply 1 "On" 0 "Off" ;
VAL_ 389 HtrnHvilOpen_B_Actl 1 "HVIL_is_Open" 0 "Normal_Operation" ;
VAL_ 389 PtWakeupDeltaT_T_Rq 2047 "Fault" 2046 "NoDataExists" ;
VAL_ 389 PreCondActv_B_Actl 1 "On" 0 "Off" ;
VAL_ 389 DrvCondTpRrDefrs_B_Rq 1 "On" 0 "Off" ;
VAL_ 389 BattTrac_I_EstVsc 32767 "Fault" 32766 "NoDataExists" ;
VAL_ 1009 ChrgCordUnlock_B_Rq 1 "Request" 0 "NoRequest" ;
VAL_ 1009 AutoHoldSwtch_D_Stat3 3 "Faulty" 2 "NotUsed" 1 "Pressed" 0 "Not_Pressed" ;
VAL_ 1009 TrlrAidCancl_B_Rq 1 "Cancel" 0 "Null" ;
VAL_ 1009 CenterStackRing_D_Actl 3 "LimitedOn" 2 "On" 1 "Off" 0 "Null" ;
VAL_ 1009 ValetMode_D_Stat 3 "NotUsed" 2 "On" 1 "Off" 0 "Null" ;
VAL_ 1009 TrlrAidSetup_D_Stat 7 "Faulty" 6 "NotUsed_3" 5 "NotUsed_2" 4 "NotUsed_1" 3 "EnterParameters" 2 "EndSetup" 1 "BeginSetup" 0 "Null" ;
VAL_ 1009 TrlrTrgtAcquire_D_Rq 7 "NotUsed_2" 6 "NotUsed_1" 5 "ActivateRVCforTBA" 4 "CancelAcquisition" 3 "RetryAcquisition" 2 "AcquisitionSuccessful" 1 "StartAcquisition" 0 "Inactive" ;
VAL_ 360 GsmSrvcRqd_B_Rq 1 "Yes" 0 "No" ;
VAL_ 360 TrnTrcmPwmSig_D_Actl 15 "Faulty" 14 "NoDataExists" 13 "NotUsed5" 12 "NotUsed4" 11 "NotUsed3" 10 "NotUsed2" 9 "NotUsed1" 8 "Default_To_Park" 7 "Neutral_Tow" 6 "Car_Wash_Mode" 5 "Manual" 4 "Drive" 3 "Neutral" 2 "Reverse" 1 "Park" 0 "No_Gear" ;
VAL_ 360 TrnGearPwmFalt_B_Actl 1 "Yes" 0 "No" ;
VAL_ 360 GearButtnStuck_B_Actl 1 "Yes" 0 "No" ;
VAL_ 331 TrnAout2_W_ActlUnfilt 65535 "Fault" 65534 "NoDataExists" ;
VAL_ 331 CmbbEngTqMn_B_ActlHtrn 1 "Active" 0 "Inactive" ;
VAL_ 331 CmbbDeny_B_ActlHtrn 1 "Yes" 0 "No" ;
VAL_ 140 DcacPwResetBttn_D_Stat 3 "NotUsed" 2 "Stuck" 1 "Pressed" 0 "Not_Pressed" ;
VAL_ 140 CcAslButtnIndxIncPress2 1 "Button_Pressed" 0 "Button_Not_Pressed" ;
VAL_ 140 SteWhlSwtchMde_D_Stat 3 "NotUsed_2" 2 "NotUsed_1" 1 "Dialog" 0 "Domain" ;
VAL_ 140 CcAslButtnIndxDecPress2 1 "Button_Pressed" 0 "Button_Not_Pressed" ;
VAL_ 140 CcAslButtnResIncPress3 1 "Pressed" 0 "Not pressed" ;
VAL_ 140 CcButtnOnPress3 1 "Pressed" 0 "Not pressed" ;
VAL_ 140 CcButtnOnOffPress3 1 "Pressed" 0 "Not pressed" ;
VAL_ 140 CcButtnOnOffCnclPress3 1 "Pressed" 0 "Not pressed" ;
VAL_ 140 CcButtnOffPress3 1 "Pressed" 0 "Not pressed" ;
VAL_ 140 CcAsllButtnResPress3 1 "Pressed" 0 "Not pressed" ;
VAL_ 140 CcAslButtnSetPress3 1 "Pressed" 0 "Not pressed" ;
VAL_ 140 CcAslButtnSetIncPress3 1 "Pressed" 0 "Not pressed" ;
VAL_ 140 CcAslButtnSetDecPress3 1 "Pressed" 0 "Not pressed" ;
VAL_ 140 CcAslButtnResDecPress3 1 "Pressed" 0 "Not pressed" ;
VAL_ 140 CcAslButtnOnPress3 1 "Pressed" 0 "Not pressed" ;
VAL_ 140 CcAslButtnOnOffCncl3 1 "Pressed" 0 "Not pressed" ;
VAL_ 140 CcAslButtnDeny_B_Actl3 1 "Pressed" 0 "Not pressed" ;
VAL_ 140 CcAslButtnCnclPress3 1 "Pressed" 0 "Not pressed" ;
VAL_ 140 AslButtnOnOffPress3 1 "Pressed" 0 "Not pressed" ;
VAL_ 140 AslButtnOnOffCnclPress2 1 "Pressed" 0 "Not pressed" ;
VAL_ 140 CcAslButtnOffCnclPress2 1 "Button_Pressed" 0 "Button_Not_Pressed" ;
VAL_ 140 CcAslButtnCnclResPress2 1 "Button_Pressed" 0 "Button_Not_Pressed" ;
VAL_ 122 VehStrtInhbt_B_RqBatt 1 "Yes" 0 "No" ;
VAL_ 122 BattTracOffFst_D_Actl 3 "Unexpected_Contactor_Open" 2 "Restraints_Impact_Event" 1 "Interlock_Open" 0 "Normal" ;
VAL_ 122 BattTracOff_B_Actl 1 "Yes" 0 "No" ;
VAL_ 122 BattTracMil_D_Rq 3 "Not_Used" 2 "Flash" 1 "On" 0 "Off" ;
VAL_ 122 BattTracCnnct_B_Cmd 1 "Close" 0 "Open" ;
VAL_ 122 BattTrac_U_Actl 1023 "Fault" 1022 "Unknown" ;
VAL_ 122 BattTrac_I_Actl 32767 "Fault" 32766 "Unknown" ;
